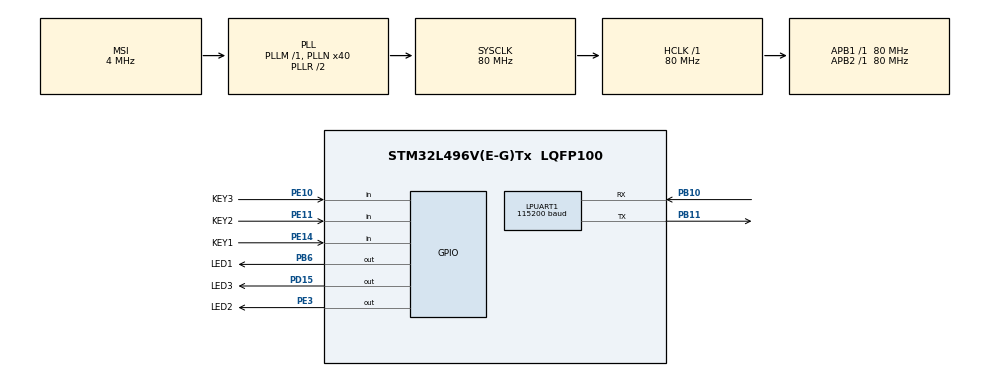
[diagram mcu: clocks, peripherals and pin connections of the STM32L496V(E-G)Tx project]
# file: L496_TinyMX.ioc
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LPUART1.BaudRate=115200
LPUART1.WordLength=UART_WORDLENGTH_8B
Mcu.Family=STM32L4
Mcu.Name=STM32L496V(E-G)Tx
Mcu.Package=LQFP100
NVIC.LPUART1_IRQn=true\:0\:0\:false\:false\:true\:true\:true\:true
NVIC.PriorityGroup=NVIC_PRIORITYGROUP_4
PA13\ (JTMS/SWDIO).Mode=Serial_Wire
PA13\ (JTMS/SWDIO).Signal=SYS_JTMS-SWDIO
PA14\ (JTCK/SWCLK).Mode=Serial_Wire
PA14\ (JTCK/SWCLK).Signal=SYS_JTCK-SWCLK
PB10.Mode=Asynchronous
PB10.Signal=LPUART1_RX
PB11.Mode=Asynchronous
PB11.Signal=LPUART1_TX
PB6.GPIO_FM6=I2C_FASTMODEPLUS_PB6
PB6.GPIO_Label=LED1
PB6.GPIO_Speed=GPIO_SPEED_FREQ_VERY_HIGH
PB6.Signal=GPIO_Output
PD15.GPIO_Label=LED3
PD15.GPIO_Speed=GPIO_SPEED_FREQ_VERY_HIGH
PD15.Signal=GPIO_Output
PE10.GPIO_Label=KEY3
PE10.GPIO_PuPd=GPIO_PULLUP
PE10.Signal=GPIO_Input
PE11.GPIO_Label=KEY2
PE11.GPIO_PuPd=GPIO_PULLUP
PE11.Signal=GPIO_Input
PE14.GPIO_Label=KEY1
PE14.GPIO_PuPd=GPIO_PULLUP
PE14.Signal=GPIO_Input
PE3.GPIO_Label=LED2
PE3.GPIO_Speed=GPIO_SPEED_FREQ_VERY_HIGH
PE3.Signal=GPIO_Output
PH0-OSC_IN\ (PH0).Mode=HSE-External-Oscillator
PH0-OSC_IN\ (PH0).Signal=RCC_OSC_IN
PH1-OSC_OUT\ (PH1).Mode=HSE-External-Oscillator
PH1-OSC_OUT\ (PH1).Signal=RCC_OSC_OUT
ProjectManager.HeapSize=0x200
ProjectManager.StackSize=0x400
ProjectManager.TargetToolchain=MDK-ARM V5.32
RCC.ADCFreq_Value=16000000
RCC.AHBFreq_Value=80000000
RCC.APB1Freq_Value=80000000
RCC.APB1TimFreq_Value=80000000
RCC.APB2Freq_Value=80000000
RCC.APB2TimFreq_Value=80000000
RCC.CortexFreq_Value=80000000
RCC.HCLKFreq_Value=80000000
RCC.HSE_VALUE=8000000
RCC.HSI48_VALUE=48000000
RCC.HSI_VALUE=16000000
RCC.LSE_VALUE=32768
RCC.MSI_VALUE=4000000
RCC.PLLN=40
RCC.SYSCLKFreq_VALUE=80000000
RCC.SYSCLKSource=RCC_SYSCLKSOURCE_PLLCLK
RCC.USBFreq_Value=16000000
RCC.VCOOutputFreq_Value=160000000
board=custom

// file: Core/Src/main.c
/* USER CODE BEGIN Header */
/**
  ******************************************************************************
  * @file           : main.c
  * @brief          : Main program body
  ******************************************************************************
  * @attention
  *
  * Copyright (c) 2022 STMicroelectronics.
  * All rights reserved.
  *
  * This software is licensed under terms that can be found in the LICENSE file
  * in the root directory of this software component.
  * If no LICENSE file comes with this software, it is provided AS-IS.
  *
  ******************************************************************************
  */
/* USER CODE END Header */
#include "main.h"
#include "usart.h"
#include "gpio.h"

/* USER CODE BEGIN Includes */
#include "stdio.h"

#include "tinymaix.h"

/* USER CODE END Includes */

void SystemClock_Config(void);

/* USER CODE BEGIN 0 */
int fputc(int ch, FILE *f)
{
  HAL_UART_Transmit(&hlpuart1, (uint8_t *)&ch, 1, 0xffff);
  return ch;
}

int fgetc(FILE *f)
{
  uint8_t ch = 0;
  HAL_UART_Receive(&hlpuart1, &ch, 1, 0xffff);
  return ch;
}

#define TEST_MDL 2

#if TEST_MDL==0
	#include "mnist_q_valid.h"
	#define IMG_L   (28)
	#define IMG_CH  (1)
	#define CLASS_N (10)

const uint8_t test_pic[28*28] ={
  0,  0,  0,  0,  0,  0,  0,  0,  0,  0,  0,  0,  0,  0,  0,  0,  0,  0,  0,  0,  0,  0,  0,  0,  0,  0,  0,  0,
  0,  0,  0,  0,  0,  0,  0,  0,  0,  0,  0,  0,  0,  0,  0,  0,  0,  0,  0,  0,  0,  0,  0,  0,  0,  0,  0,  0,
  0,  0,  0,  0,  0,  0,  0,  0,  0,  0,  0,  0,  0,  0,  0,  0,  0,  0,  0,  0,  0,  0,  0,  0,  0,  0,  0,  0,
  0,  0,  0,  0,  0,  0,  0,  0,  0,  0,116,125,171,255,255,150, 93,  0,  0,  0,  0,  0,  0,  0,  0,  0,  0,  0,
  0,  0,  0,  0,  0,  0,  0,  0,  0,169,253,253,253,253,253,253,218, 30,  0,  0,  0,  0,  0,  0,  0,  0,  0,  0,
  0,  0,  0,  0,  0,  0,  0,  0,169,253,253,253,213,142,176,253,253,122,  0,  0,  0,  0,  0,  0,  0,  0,  0,  0,
  0,  0,  0,  0,  0,  0,  0, 52,250,253,210, 32, 12,  0,  6,206,253,140,  0,  0,  0,  0,  0,  0,  0,  0,  0,  0,
  0,  0,  0,  0,  0,  0,  0, 77,251,210, 25,  0,  0,  0,122,248,253, 65,  0,  0,  0,  0,  0,  0,  0,  0,  0,  0,
  0,  0,  0,  0,  0,  0,  0,  0, 31, 18,  0,  0,  0,  0,209,253,253, 65,  0,  0,  0,  0,  0,  0,  0,  0,  0,  0,
  0,  0,  0,  0,  0,  0,  0,  0,  0,  0,  0,  0,  0,117,247,253,198, 10,  0,  0,  0,  0,  0,  0,  0,  0,  0,  0,
  0,  0,  0,  0,  0,  0,  0,  0,  0,  0,  0,  0, 76,247,253,231, 63,  0,  0,  0,  0,  0,  0,  0,  0,  0,  0,  0,
  0,  0,  0,  0,  0,  0,  0,  0,  0,  0,  0,  0,128,253,253,144,  0,  0,  0,  0,  0,  0,  0,  0,  0,  0,  0,  0,
  0,  0,  0,  0,  0,  0,  0,  0,  0,  0,  0,176,246,253,159, 12,  0,  0,  0,  0,  0,  0,  0,  0,  0,  0,  0,  0,
  0,  0,  0,  0,  0,  0,  0,  0,  0,  0, 25,234,253,233, 35,  0,  0,  0,  0,  0,  0,  0,  0,  0,  0,  0,  0,  0,
  0,  0,  0,  0,  0,  0,  0,  0,  0,  0,198,253,253,141,  0,  0,  0,  0,  0,  0,  0,  0,  0,  0,  0,  0,  0,  0,
  0,  0,  0,  0,  0,  0,  0,  0,  0, 78,248,253,189, 12,  0,  0,  0,  0,  0,  0,  0,  0,  0,  0,  0,  0,  0,  0,
  0,  0,  0,  0,  0,  0,  0,  0, 19,200,253,253,141,  0,  0,  0,  0,  0,  0,  0,  0,  0,  0,  0,  0,  0,  0,  0,
  0,  0,  0,  0,  0,  0,  0,  0,134,253,253,173, 12,  0,  0,  0,  0,  0,  0,  0,  0,  0,  0,  0,  0,  0,  0,  0,
  0,  0,  0,  0,  0,  0,  0,  0,248,253,253, 25,  0,  0,  0,  0,  0,  0,  0,  0,  0,  0,  0,  0,  0,  0,  0,  0,
  0,  0,  0,  0,  0,  0,  0,  0,248,253,253, 43, 20, 20, 20, 20,  5,  0,  5, 20, 20, 37,150,150,150,147, 10,  0,
  0,  0,  0,  0,  0,  0,  0,  0,248,253,253,253,253,253,253,253,168,143,166,253,253,253,253,253,253,253,123,  0,
  0,  0,  0,  0,  0,  0,  0,  0,174,253,253,253,253,253,253,253,253,253,253,253,249,247,247,169,117,117, 57,  0,
  0,  0,  0,  0,  0,  0,  0,  0,  0,118,123,123,123,166,253,253,253,155,123,123, 41,  0,  0,  0,  0,  0,  0,  0,
  0,  0,  0,  0,  0,  0,  0,  0,  0,  0,  0,  0,  0,  0,  0,  0,  0,  0,  0,  0,  0,  0,  0,  0,  0,  0,  0,  0,
  0,  0,  0,  0,  0,  0,  0,  0,  0,  0,  0,  0,  0,  0,  0,  0,  0,  0,  0,  0,  0,  0,  0,  0,  0,  0,  0,  0,
  0,  0,  0,  0,  0,  0,  0,  0,  0,  0,  0,  0,  0,  0,  0,  0,  0,  0,  0,  0,  0,  0,  0,  0,  0,  0,  0,  0,
  0,  0,  0,  0,  0,  0,  0,  0,  0,  0,  0,  0,  0,  0,  0,  0,  0,  0,  0,  0,  0,  0,  0,  0,  0,  0,  0,  0,
  0,  0,  0,  0,  0,  0,  0,  0,  0,  0,  0,  0,  0,  0,  0,  0,  0,  0,  0,  0,  0,  0,  0,  0,  0,  0,  0,  0,
};
#elif TEST_MDL==1
	#include "cifar10_q.h"
	#define IMG_L   (32)
	#define IMG_CH  (3)
	#define CLASS_N (10)

const unsigned char test_pic[32*32*3]={\
 62,116, 47,  60,111, 51,  64,113, 59,  68,119, 62,  74,127, 64,  79,132, 69,  82,133, 76,  89,134, 85,  94,136, 89,  97,136, 91, 104,143, 98, 100,142, 95, 100,145, 89, 102,146, 87, 106,145, 90, 113,146,101, 107,156, 88, 110,157, 95, 113,154,103, 118,157,112, 120,156,112, 120,157,111, 127,163,116, 126,162,115, 128,164,118, 130,166,120, 133,169,122, 136,174,122, 140,178,126, 142,178,131, 141,175,134, 140,172,137,
 67,118, 51,  66,114, 56,  71,117, 64,  74,123, 67,  79,130, 68,  82,135, 72,  85,135, 77,  92,138, 85,  98,142, 89, 103,144, 93, 101,143, 95, 100,143, 92, 105,153, 94, 104,151, 88, 110,154, 95, 113,152,100, 113,159, 93, 114,158, 99, 116,158,105, 125,162,116, 127,164,118, 127,165,117, 133,170,120, 133,170,120, 134,170,123, 137,173,127, 139,175,129, 142,179,129, 144,181,131, 148,182,135, 147,179,138, 146,176,141,
 72,116, 55,  73,115, 60,  76,119, 68,  81,126, 70,  84,133, 71,  88,137, 75,  90,138, 79,  96,141, 84, 102,145, 88, 104,146, 91, 108,149, 98, 116,159,108, 115,163,105, 107,156, 94, 104,152, 93, 109,155,102, 115,157, 96, 116,157, 99, 119,159,104, 128,165,115, 131,167,120, 131,168,118, 134,173,118, 134,173,118, 136,175,123, 138,176,128, 141,177,133, 144,179,135, 147,180,135, 148,181,136, 150,180,139, 149,177,141,
 76,118, 57,  76,116, 61,  80,121, 70,  82,127, 71,  86,133, 71,  92,139, 77,  96,139, 82, 103,144, 87, 132,172,114, 117,153, 99, 120,153,109, 146,180,140, 149,185,143, 146,185,139, 122,163,118, 110,152,111, 118,158,100, 120,160,102, 125,165,107, 133,169,115, 136,171,121, 137,173,121, 136,175,119, 135,176,118, 139,180,123, 142,180,132, 145,181,139, 147,181,141, 150,183,139, 152,182,139, 154,182,139, 155,181,141,
 78,122, 61,  78,121, 64,  81,125, 72,  83,128, 71,  87,133, 74,  93,139, 80, 101,141, 86, 109,145, 91, 153,187,133, 145,173,127, 124,145,113, 103,119,101, 101,120,103, 138,161,139, 151,179,156, 124,152,133, 121,160,104, 123,164,103, 129,170,109, 135,173,115, 137,172,122, 140,174,127, 139,177,125, 137,178,120, 139,182,125, 142,182,134, 145,182,142, 148,182,145, 151,183,142, 154,185,140, 157,184,140, 159,183,141,
 80,127, 65,  78,126, 68,  80,129, 73,  81,131, 73,  86,134, 75,  94,139, 82, 102,141, 89, 109,145, 91, 121,151, 98, 141,164,120, 107,120, 96,  34, 38, 33,  19, 23, 24,  63, 71, 70, 138,153,149, 145,164,161, 121,164,107, 122,164,103, 129,171,106, 132,173,112, 136,171,121, 141,174,130, 139,175,128, 139,179,124, 140,182,127, 143,183,135, 145,183,141, 148,183,143, 149,184,140, 153,184,139, 157,184,140, 159,184,140,
 77,128, 68,  76,127, 70,  78,130, 76,  79,133, 74,  84,136, 76,  90,140, 82,  99,141, 86, 106,145, 89,  90,125, 68, 110,136, 90,  82, 95, 71,  21, 22, 20,  12, 10, 16,  17, 21, 26,  80, 92, 92, 145,163,162, 127,173,121, 122,168,109, 126,172,106, 132,174,113, 136,172,125, 139,173,133, 139,173,132, 142,180,132, 142,184,131, 143,185,137, 145,185,143, 148,186,144, 152,188,142, 157,189,142, 159,188,142, 160,187,143,
 75,126, 68,  74,127, 70,  76,131, 76,  75,133, 74,  81,138, 77,  90,141, 83,  93,143, 85,  99,146, 84,  97,140, 77, 109,142, 91,  71, 88, 61,   6, 12,  7,   5,  5, 11,   2,  9, 12,  27, 44, 41, 121,144,140, 133,179,137, 121,169,117, 122,171,109, 128,175,113, 135,173,123, 136,171,131, 136,170,133, 141,177,133, 141,181,133, 144,183,137, 146,185,140, 148,187,142, 151,189,141, 153,190,140, 158,190,143, 158,189,144,
 76,126, 68,  76,129, 72,  77,132, 77,  76,134, 75,  78,137, 76,  84,140, 81,  89,143, 84,  93,146, 83,  92,144, 80, 106,148, 95,  81,106, 78,   0,  8,  5,   4,  6, 14,   1,  7, 12,   1, 19, 18,  90,114,112, 150,193,166, 122,167,128, 117,166,110, 127,175,116, 132,176,123, 131,170,125, 134,171,131, 138,177,132, 140,179,133, 142,181,135, 146,185,140, 148,187,141, 152,190,142, 153,191,141, 155,191,144, 155,190,146,
 79,127, 68,  78,129, 72,  76,131, 76,  76,134, 75,  80,137, 76,  85,139, 80,  88,141, 84,  89,145, 86,  96,150, 90, 106,150,103,  68, 91, 69,   5, 10, 11,   3,  0, 10,   0,  0,  8,  25, 33, 40, 122,136,142, 162,196,186, 140,179,154, 125,171,125, 122,170,112, 123,169,110, 129,173,120, 134,174,126, 137,176,130, 139,178,132, 141,180,134, 145,184,139, 148,187,141, 150,190,142, 151,191,143, 152,191,145, 153,192,147,
 81,127, 68,  78,127, 71,  77,129, 75,  80,133, 76,  82,136, 76,  85,136, 78,  89,139, 85,  91,144, 87,  94,147, 90, 100,141, 96,  49, 68, 47,   9,  4,  3,  17,  0,  7,  26,  8, 15,  65, 53, 59, 157,150,157, 165,186,188, 147,175,162, 137,172,138, 126,170,117, 127,174,112, 123,172,110, 126,171,114, 127,171,118, 137,177,129, 140,179,133, 146,183,137, 149,185,141, 149,188,143, 150,189,144, 150,191,146, 151,192,147,
 81,126, 69,  77,126, 72,  78,127, 75,  82,133, 76,  84,135, 75,  87,135, 77,  89,138, 82,  92,143, 86,  98,148, 90, 107,143, 96,  53, 65, 35,  20,  4,  0,  62, 28, 22, 101, 62, 54, 114, 78, 70, 156,124,118, 145,152,155, 132,146,140, 131,155,131, 130,165,121, 120,167,105, 119,170,102, 125,175,111, 132,179,123, 134,177,126, 139,179,131, 145,182,136, 148,184,140, 149,185,143, 149,187,145, 149,190,145, 148,192,145,
 77,124, 68,  75,122, 73,  77,125, 77,  81,131, 77,  84,135, 75,  88,134, 75,  90,138, 79,  92,143, 83,  93,144, 82, 104,142, 84,  70, 79, 36,  67, 45, 10, 130, 87, 54, 158,105, 72, 157,103, 72, 176,126, 98, 116,110,103, 109,107, 99, 116,126,109, 136,161,127, 123,163,108, 121,172,105, 118,170,106, 126,176,118, 131,177,125, 138,179,128, 144,182,132, 147,183,137, 148,183,143, 148,185,145, 148,188,146, 148,193,144,
 72,121, 67,  73,121, 73,  74,123, 77,  78,130, 77,  83,134, 74,  86,135, 73,  87,138, 76,  88,143, 80,  94,148, 81, 104,145, 83,  86, 99, 43, 102, 81, 30, 156,109, 57, 162,102, 48, 169,109, 57, 190,130, 84, 126,109, 83,  88, 74, 56,  88, 85, 70, 110,123, 99, 124,157,113, 114,162,103, 118,170,110, 125,175,121, 127,175,123, 136,178,125, 143,181,129, 146,182,135, 148,182,142, 149,183,146, 149,188,143, 149,192,141,
 70,119, 65,  69,119, 71,  71,122, 78,  74,127, 77,  81,132, 74,  84,135, 73,  84,138, 78,  82,141, 80,  83,143, 79,  99,146, 83,  93,111, 52,  93, 76, 19, 132, 88, 27, 159,100, 38, 178,115, 57, 182,119, 68, 135,111, 65,  84, 63, 32,  71, 58, 44,  82, 85, 69, 124,148,116, 117,159,111, 121,171,117, 120,171,121, 127,174,125, 133,177,124, 141,180,124, 146,182,130, 148,180,139, 149,182,145, 147,186,141, 147,191,138,
 67,117, 63,  69,119, 71,  71,122, 78,  74,127, 77,  78,132, 73,  84,137, 74,  82,139, 78,  79,141, 81,  80,145, 83,  95,146, 86, 105,126, 71,  91, 78, 22, 108, 67,  5, 145, 88, 26, 171,108, 50, 179,116, 66, 147,119, 59, 110, 83, 46,  72, 53, 38,  66, 64, 53, 100,121, 96, 119,159,117, 117,167,119, 119,168,122, 126,174,126, 133,178,122, 140,180,122, 145,181,127, 147,179,138, 147,180,143, 148,184,140, 147,189,134,
 67,115, 67,  68,114, 71,  75,121, 79,  77,124, 78,  76,125, 73,  85,136, 78,  81,137, 72,  82,140, 75,  83,143, 79,  86,141, 86,  94,136, 88,  77, 99, 51,  74, 70, 19, 119, 84, 28, 155, 93, 39, 171, 92, 41, 193,103, 49, 178,113, 52, 123, 89, 29,  77, 68, 25,  81, 87, 62, 117,142,116, 116,161,118, 116,172,113, 121,175,115, 133,177,124, 138,175,125, 141,177,130, 144,183,138, 139,182,137, 141,184,133, 145,188,131,
 66,115, 65,  68,116, 68,  71,118, 72,  79,125, 78,  80,128, 76,  82,132, 74,  78,133, 70,  83,141, 76,  80,140, 79,  84,142, 84,  90,139, 87,  89,121, 67,  88, 97, 41, 103, 84, 27, 117, 71, 17, 136, 75, 25, 171, 99, 45, 189,131, 72, 182,143, 88, 129,107, 66,  87, 78, 51,  95,106, 80, 125,159,118, 116,166,112, 121,174,117, 127,173,120, 135,173,123, 138,174,127, 140,176,132, 139,180,135, 140,182,134, 140,185,128,
 64,114, 60,  68,117, 65,  72,121, 71,  76,123, 74,  74,123, 69,  81,131, 73,  85,138, 75,  78,135, 72,  79,139, 78,  80,141, 83,  83,141, 83,  91,137, 78,  95,124, 61, 100,105, 44,  90, 73, 17,  94, 62, 13, 142,100, 47, 161,120, 65, 182,142, 90, 190,151,112, 114, 86, 56,  86, 78, 49, 124,138,102, 127,163,117, 125,170,121, 123,172,118, 132,177,121, 138,177,125, 137,174,128, 140,179,134, 139,181,133, 134,181,125,
 58,113, 56,  61,116, 61,  69,121, 67,  78,129, 72,  75,125, 67,  77,128, 66,  79,132, 69,  81,138, 77,  80,140, 80,  75,139, 79,  75,140, 78,  86,144, 79,  91,138, 70, 102,131, 68,  94,104, 51,  83, 83, 35, 101, 90, 38, 136,113, 63, 181,142, 97, 198,154,113, 156,118, 83, 112, 91, 59,  95, 94, 60, 103,119, 85, 127,160,116, 127,171,118, 126,176,118, 131,178,122, 136,176,128, 139,175,131, 140,179,133, 131,177,125,
 55,113, 58,  61,119, 64,  65,123, 65,  70,124, 64,  76,130, 65,  87,140, 73,  84,137, 70,  81,136, 73,  79,137, 78,  73,137, 77,  71,139, 74,  82,148, 77,  86,143, 74,  95,140, 77, 100,132, 77, 100,124, 76, 101,113, 65, 117,112, 67, 163,139, 97, 176,145,100, 161,135, 89, 178,162,120, 103, 93, 63,  64, 63, 35, 131,145,109, 138,171,120, 124,172,113, 123,174,116, 128,176,124, 129,171,124, 136,175,129, 135,176,125,
 59,115, 66,  60,117, 66,  64,122, 64,  71,126, 63,  84,139, 70, 119,175,100, 121,176,103,  90,144, 77,  74,130, 71,  78,138, 78,  72,138, 73,  74,141, 72,  82,145, 76,  85,139, 79,  94,140, 87,  99,140, 89,  96,121, 77, 111,122, 82, 151,149,108, 142,137, 88, 141,142, 86, 158,161,112, 122,120, 86,  84, 77, 50, 134,133, 99, 145,166,117, 129,170,112, 118,172,113, 120,175,120, 120,167,118, 134,172,124, 138,174,127,
 67,114, 75,  73,120, 74,  76,125, 73,  96,147, 87, 107,160, 87, 123,179, 98, 126,182,101,  94,149, 76,  73,128, 65,  77,135, 76,  73,136, 74,  72,136, 70,  80,143, 81,  82,140, 82,  86,141, 86,  75,127, 73,  58, 92, 51,  89,116, 77, 121,144,100, 133,160,104, 111,145, 80, 110,142, 85, 107,120, 82,  73, 71, 41, 114,108, 71, 133,145, 93, 132,165,108, 119,168,112, 116,171,116, 119,169,115, 128,169,118, 138,172,125,
 98,129, 98, 138,171,134, 135,170,126, 144,184,129, 144,189,120, 119,171, 88, 104,159, 72,  83,140, 61,  77,133, 68,  72,130, 71,  75,135, 74,  76,139, 77,  81,142, 84,  77,136, 85,  83,140, 89,  58,115, 60,  78,120, 79,  89,129, 88,  83,127, 80,  96,149, 86, 101,163, 93, 105,159, 99, 105,142, 96, 109,125, 84,  76, 79, 33, 107,115, 62, 131,154,100, 124,163,111, 116,167,110, 121,172,114, 124,169,113, 135,170,120,
165,182,155, 220,238,209, 209,231,196, 196,223,179, 167,204,142, 123,170, 91, 105,161, 72,  83,141, 60,  73,133, 63,  75,135, 71,  74,135, 71,  75,138, 76,  81,140, 89,  79,135, 92,  73,128, 81,  71,129, 75,  90,138, 96,  77,128, 84,  77,133, 80,  86,152, 87,  87,159, 89,  86,155, 94,  96,154,100, 116,155,103, 105,129, 71,  70, 84, 26,  98,114, 61, 127,156,107, 118,163,106, 117,168,106, 124,170,111, 135,171,117,
194,203,177, 229,241,213, 228,242,214, 232,249,216, 201,230,181, 115,159, 88, 100,155, 70,  88,147, 66,  74,134, 64,  76,137, 71,  74,137, 68,  79,138, 77,  78,132, 85,  74,125, 88,  83,134, 96,  81,135, 88,  77,130, 86,  79,134, 87,  83,144, 88,  85,151, 86,  81,152, 86,  81,151, 90,  84,152, 93,  95,155, 91, 117,161, 92, 105,130, 68,  79, 94, 43, 118,142, 94, 128,169,112, 123,174,107, 121,166,103, 135,172,116,
177,189,159, 210,222,194, 225,238,214, 230,244,220, 207,232,194, 144,182,122, 121,173, 96,  95,152, 77,  73,132, 64,  78,136, 71,  76,136, 66,  81,136, 73,  85,131, 88,  88,127,101, 109,149,121,  89,133, 94,  71,126, 79,  83,140, 89,  89,151, 91,  89,150, 86,  87,147, 86,  83,149, 90,  83,153, 92,  89,159, 88, 104,161, 86, 125,163, 97, 124,148, 94, 120,146, 98, 122,161,105, 119,165, 99, 125,167,102, 135,167,108,
158,178,143, 148,166,135, 193,209,185, 230,244,226, 210,232,204, 189,223,176, 148,194,128,  96,148, 84,  86,137, 79,  86,138, 78,  87,138, 70,  94,139, 76,  75,110, 70,  71, 97, 79, 111,137,119, 111,141,112,  75,132, 81,  84,142, 87,  89,148, 87,  91,148, 87,  92,148, 89,  91,149, 91,  89,155, 90,  92,163, 90,  99,163, 87, 118,168, 98, 146,184,126, 125,161,107, 114,157,100, 140,185,122, 145,182,118, 135,163,103,
161,191,150, 101,127, 91, 156,175,150, 226,239,223, 210,227,206, 222,249,210, 184,220,168, 123,161,111, 139,178,133, 134,175,124, 116,157, 95, 121,157, 97,  77,101, 66,  74, 91, 78,  98,114,103,  97,116, 95,  82,138, 85,  86,144, 85,  90,147, 84,  93,147, 87,  95,148, 91,  93,148, 91,  91,152, 88,  96,160, 88,  99,162, 88, 107,163, 92, 131,181,117, 122,168,109, 121,166,109, 156,197,139, 170,204,143, 159,188,125,
182,215,171, 153,180,141, 188,207,180, 225,235,218, 204,215,195, 216,233,200, 206,230,188, 175,201,165, 200,225,197, 199,225,189, 155,186,131, 154,183,128, 101,120, 87, 105,116,106, 102,113,105,  80, 96, 78,  80,141, 85,  86,146, 85,  92,149, 86,  92,149, 88,  94,149, 92,  93,151, 92,  93,154, 88,  94,155, 87,  98,158, 88, 100,158, 87, 116,172,101, 116,167,100, 138,181,124, 177,216,161, 174,209,152, 148,184,118,
193,223,182, 203,229,189, 214,229,198, 232,236,217, 233,234,214, 233,239,208, 220,232,196, 214,227,203, 222,235,221, 207,223,199, 148,169,124, 144,166,117, 113,128,100, 111,122,114, 128,140,134, 118,137,118,  79,145, 86,  85,148, 86,  91,151, 87,  95,151, 92,  93,152, 94,  93,156, 94,  95,157, 91,  96,154, 89,  97,155, 90, 107,167, 97, 113,172, 97, 122,172,102, 143,182,126, 183,218,168, 140,179,123, 116,163, 95,
176,203,163, 210,231,192, 219,230,198, 233,232,212, 234,229,208, 230,230,200, 211,216,185, 218,222,203, 223,227,221, 222,232,215, 167,185,144, 125,145, 98,  81, 96, 68,  59, 69, 63, 120,134,128, 140,160,141,  84,154, 93,  83,148, 86,  89,149, 85,  95,153, 94,  94,156, 96,  91,156, 94,  93,157, 91,  93,153, 89, 114,171,110, 118,178,108, 111,169, 91, 115,163, 91, 158,193,137, 160,192,145, 109,151, 96, 100,155, 86,
};

  #elif TEST_MDL==2
	#include "vww96_q.h"
	#define IMG_L   (96)
	#define IMG_CH  (3)
	#define CLASS_N (2)
const unsigned char test_pic[96*96*3]={\
155,156,176, 104,105,125, 122,123,143, 155,158,177,  94, 99,118,  75, 80, 99,  73, 79, 95,  77, 83, 99, 133,139,155, 161,164,179, 167,170,185, 165,164,180, 164,161,178, 148,146,160, 145,141,156, 168,161,177, 159,166,174, 160,167,175, 158,165,173,  97,104,112,  71, 78, 86,  79, 86, 94,  74, 81, 89, 126,133,141, 142,149,157, 114,121,129, 142,149,157, 147,154,162,  80, 87, 95,  70, 77, 85,  59, 66, 74,  68, 75, 83,  43, 53, 52,  37, 47, 46,  42, 52, 51,  68, 80, 78, 112,124,122, 145,157,155, 149,161,159, 137,149,147, 137,147,146, 149,159,158, 154,163,162, 144,150,150, 132,136,137, 127,131,132, 122,123,125, 114,115,117,  92, 91, 96,  87, 86, 91,  81, 81, 83,  75, 75, 77,  70, 70, 72,  64, 64, 66,  59, 59, 61,  55, 55, 57,  67, 67, 67,  93, 95, 94, 113,115,114, 118,120,119, 129,131,130, 146,148,145, 142,144,141, 124,126,123,  90, 88, 93,  84, 83, 88,  87, 88, 92, 106,110,113, 119,124,127, 116,126,127, 141,153,151, 185,200,197, 230,245,242, 235,250,247, 241,253,251, 241,252,248, 238,247,244, 240,246,244, 246,252,250, 252,255,255, 252,254,253, 249,251,250, 246,248,247, 247,249,248, 249,251,250, 251,253,252, 249,251,250, 247,249,248, 254,255,255, 254,255,255, 254,255,255, 253,255,254, 253,255,254, 252,254,253, 252,254,253, 252,254,253,
139,138,156,  90, 91,109, 101,103,118, 133,136,151,  81, 84, 99,  60, 66, 80,  57, 63, 77,  60, 66, 78, 100,106,118, 129,133,145, 136,138,150, 132,132,144, 130,128,141, 114,110,124, 108,102,116, 127,121,135, 119,123,132, 119,123,132, 118,122,131,  61, 65, 74,  33, 37, 46,  34, 38, 47,  23, 27, 36,  65, 69, 78,  81, 85, 94,  51, 55, 64,  78, 82, 91,  99,103,112,  55, 59, 68,  64, 68, 77,  74, 78, 87,  97,101,110, 165,174,173, 153,162,161, 128,137,136, 101,110,109,  86, 95, 94,  84, 93, 92,  86, 95, 94,  86, 95, 94, 102,111,110, 103,109,109,  98,104,104,  89, 93, 94,  85, 86, 88,  84, 85, 87,  84, 84, 86,  81, 81, 83,  67, 66, 71,  64, 63, 68,  60, 60, 62,  56, 56, 58,  53, 53, 55,  48, 48, 50,  43, 43, 45,  38, 39, 41,  29, 31, 30,  44, 46, 45,  55, 57, 56,  57, 59, 58,  68, 70, 69,  86, 88, 87,  91, 93, 92,  84, 86, 85,  76, 74, 79,  80, 79, 84,  90, 91, 95, 108,112,115, 114,122,124, 112,122,123, 142,154,154, 191,206,203, 217,232,229, 230,245,242, 247,255,255, 247,255,255, 248,255,255, 247,255,253, 246,252,250, 248,252,251, 254,255,255, 253,255,254, 250,252,251, 250,252,251, 253,255,254, 254,255,255, 253,255,254, 252,254,253, 252,254,253, 252,254,253, 251,253,252, 251,253,252, 250,252,251, 250,252,251, 250,252,251, 249,251,250,
167,167,179, 128,128,140, 128,128,140, 160,163,172, 120,124,133, 103,107,116,  99,103,112, 101,106,112, 121,126,132, 151,154,161, 159,162,167, 156,157,162, 155,154,160, 140,137,144, 133,128,135, 149,144,151, 130,135,141, 129,134,140, 131,136,142,  86, 91, 97,  59, 64, 70,  55, 60, 66,  42, 47, 53,  71, 76, 82,  97,102,108,  60, 65, 71,  69, 74, 80,  90, 95,101,  49, 54, 60,  50, 55, 61,  57, 62, 68,  80, 85, 91, 122,123,125, 139,140,142, 151,152,154, 146,147,149, 130,131,133, 113,117,118, 104,108,109, 100,101,103,  76, 77, 79,  67, 68, 70,  60, 61, 63,  59, 59, 61,  59, 59, 61,  58, 56, 59,  58, 56, 59,  60, 58, 61,  50, 49, 54,  48, 47, 52,  46, 45, 50,  44, 44, 46,  43, 43, 45,  40, 40, 42,  35, 36, 38,  32, 33, 35,  36, 37, 39,  38, 39, 41,  38, 40, 39,  36, 38, 37,  39, 41, 40,  46, 48, 47,  49, 53, 52,  48, 52, 51,  48, 47, 52,  57, 56, 61,  68, 69, 73,  80, 84, 87,  85, 93, 95,  94,104,105, 139,151,151, 199,213,213, 218,232,232, 228,243,240, 238,253,250, 242,254,252, 239,249,248, 239,248,247, 246,252,252, 251,255,255, 252,255,255, 252,255,255, 250,254,253, 250,254,253, 251,255,254, 252,255,255, 252,255,255, 252,255,255, 251,255,254, 251,255,254, 250,254,253, 250,254,253, 250,254,253, 249,253,252, 249,253,252, 249,253,252,
146,145,150, 118,117,122, 105,106,110, 140,141,145, 115,119,122,  99,103,106,  93, 99, 99,  95,101,101, 104,108,109, 136,140,139, 149,151,150, 149,149,149, 152,150,151, 142,138,137, 134,128,128, 147,141,141, 146,149,154, 144,147,152, 149,152,157, 120,123,128,  97,100,105,  92, 95,100,  84, 87, 92, 103,106,111, 144,147,152, 111,114,119, 112,115,120, 141,144,149, 107,110,115,  97,100,105,  96, 99,104, 114,117,122, 156,151,155, 156,151,155, 149,144,148, 132,127,131, 113,108,112,  94, 89, 93,  76, 71, 75,  61, 59, 62,  61, 59, 62,  57, 52, 56,  58, 53, 57,  65, 60, 64,  65, 60, 64,  56, 51, 55,  53, 48, 52,  57, 52, 56,  49, 48, 53,  46, 45, 50,  43, 43, 45,  41, 41, 43,  41, 41, 43,  40, 41, 43,  39, 40, 42,  38, 39, 41,  40, 41, 43,  37, 38, 40,  34, 38, 39,  34, 38, 39,  31, 35, 36,  25, 29, 30,  22, 26, 27,  23, 27, 28,  36, 35, 41,  40, 41, 46,  38, 42, 45,  40, 45, 48,  44, 52, 54,  60, 70, 71, 111,123,123, 170,184,184, 192,206,206, 210,224,224, 233,247,247, 247,255,255, 247,255,255, 242,250,252, 239,247,249, 239,247,249, 250,254,253, 249,253,252, 248,252,251, 247,251,250, 248,252,251, 249,253,252, 250,254,253, 251,255,254, 249,253,252, 249,253,252, 249,253,252, 249,253,252, 249,253,252, 249,253,252, 249,253,252, 249,253,252,
128,126,127, 115,114,112,  89, 89, 87, 122,122,120, 110,112,109,  90, 95, 91,  83, 88, 82,  84, 89, 83,  91, 96, 90, 127,129,124, 142,143,137, 143,142,137, 151,148,143, 143,138,134, 136,129,123, 147,140,134, 140,141,145, 135,136,140, 139,140,144, 121,122,126,  98, 99,103,  91, 92, 96,  90, 91, 95, 101,102,106, 126,127,131, 103,104,108,  99,100,104, 134,135,139, 111,112,116,  99,100,104,  98, 99,103, 111,112,116, 145,134,140, 135,124,130, 115,104,110,  95, 84, 90,  82, 73, 78,  77, 68, 73,  72, 63, 68,  65, 56, 61,  55, 46, 51,  55, 46, 51,  61, 52, 57,  67, 61, 65,  62, 56, 60,  50, 44, 48,  47, 41, 45,  54, 48, 52,  48, 48, 50,  43, 43, 45,  37, 37, 39,  34, 34, 36,  34, 34, 36,  36, 37, 39,  38, 39, 41,  39, 40, 42,  30, 31, 33,  26, 30, 31,  28, 32, 33,  34, 38, 39,  34, 38, 39,  27, 31, 32,  24, 30, 30,  26, 32, 32,  40, 41, 46,  45, 46, 51,  40, 43, 48,  38, 43, 47,  38, 46, 49,  42, 52, 53,  67, 79, 79, 105,117,117, 143,157,157, 162,176,176, 191,203,203, 212,224,224, 225,235,236, 230,240,241, 235,243,245, 238,246,248, 245,249,248, 246,250,249, 247,251,250, 247,251,250, 247,251,250, 247,251,250, 248,252,251, 249,253,252, 246,250,249, 246,250,249, 246,250,249, 247,251,250, 247,251,250, 247,251,250, 247,251,250, 247,251,250,
116,112,109, 116,115,111,  79, 78, 74, 109,110,105, 106,107,101,  83, 86, 79,  73, 76, 69,  74, 77, 70,  81, 84, 75, 117,118,110, 131,131,123, 131,128,119, 139,135,126, 134,127,119, 124,117,109, 133,124,117, 139,139,139, 133,133,133, 134,134,134, 121,121,121,  93, 93, 93,  80, 80, 80,  84, 84, 84,  87, 87, 87, 131,131,131, 117,117,117,  99, 99, 99, 126,126,126, 105,105,105,  92, 92, 92,  91, 91, 91,  97, 97, 97, 106, 93,100, 109, 96,103, 106, 93,100,  92, 79, 86,  77, 64, 71,  67, 54, 61,  59, 46, 53,  54, 41, 48,  62, 51, 57,  63, 52, 58,  65, 54, 60,  62, 53, 58,  54, 45, 50,  44, 38, 42,  46, 40, 44,  53, 47, 51,  45, 43, 46,  40, 38, 41,  32, 32, 34,  29, 29, 31,  30, 30, 32,  33, 33, 35,  35, 36, 38,  37, 38, 40,  37, 38, 40,  32, 36, 37,  32, 36, 37,  34, 38, 39,  35, 41, 41,  34, 40, 40,  36, 42, 42,  40, 46, 46,  36, 37, 41,  46, 50, 53,  54, 58, 61,  60, 65, 68,  62, 70, 72,  51, 61, 63,  45, 55, 57,  54, 65, 67,  91,102,104, 113,124,126, 150,161,163, 186,197,199, 215,225,227, 232,242,244, 239,249,251, 241,251,253, 241,247,245, 244,250,248, 247,253,251, 249,255,253, 248,254,252, 247,253,251, 247,253,251, 247,253,251, 249,255,253, 249,255,253, 249,255,253, 249,255,253, 250,255,254, 250,255,254, 250,255,254, 250,255,254,
118,114,111, 133,129,126,  92, 88, 85, 119,118,114, 123,124,119,  98, 99, 93,  88, 89, 83,  91, 92, 86,  91, 92, 84, 126,127,119, 139,139,131, 138,135,128, 147,143,134, 144,137,129, 134,125,118, 140,131,124, 137,136,134, 131,130,128, 133,132,130, 127,126,124,  93, 92, 90,  75, 74, 72,  84, 83, 81,  82, 81, 79, 109,108,106, 109,108,106,  88, 87, 85, 112,111,109,  96, 95, 93,  86, 85, 83,  87, 86, 84,  88, 87, 85,  98, 86, 90,  96, 84, 88,  85, 73, 77,  70, 58, 62,  61, 49, 53,  63, 51, 55,  69, 57, 61,  72, 60, 64,  72, 60, 64,  73, 62, 66,  70, 59, 63,  59, 50, 53,  49, 43, 45,  47, 41, 43,  45, 41, 42,  44, 40, 41,  36, 34, 35,  33, 31, 32,  30, 28, 29,  29, 27, 28,  31, 29, 30,  33, 33, 35,  34, 34, 36,  33, 34, 36,  33, 34, 36,  31, 35, 36,  30, 34, 35,  27, 31, 32,  25, 30, 33,  27, 32, 35,  28, 33, 36,  27, 32, 35,  27, 31, 34,  40, 44, 47,  49, 53, 56,  57, 62, 65,  65, 70, 73,  54, 62, 64,  40, 50, 51,  41, 51, 53,  50, 60, 62,  77, 88, 90, 124,135,137, 176,186,188, 213,223,225, 230,240,242, 228,238,240, 222,232,234, 235,244,241, 240,249,246, 246,255,252, 249,255,255, 247,255,253, 245,254,251, 243,252,249, 243,252,249, 247,255,253, 248,255,254, 248,255,254, 248,255,254, 249,255,255, 249,255,255, 249,255,255, 249,255,255,
103, 97, 99, 126,122,121,  83, 79, 78, 112,111,109, 122,121,119,  96, 96, 94,  88, 89, 84,  92, 93, 88,  86, 87, 82, 122,121,117, 136,133,128, 134,129,125, 144,136,133, 142,132,130, 132,123,118, 139,128,124, 141,137,134, 137,133,130, 142,138,135, 141,137,134, 107,103,100,  88, 84, 81, 101, 97, 94,  97, 93, 90, 117,113,110, 128,124,121, 107,103,100, 129,125,122, 112,108,105, 100, 96, 93,  96, 92, 89,  88, 84, 81,  86, 77, 78,  77, 68, 69,  66, 56, 57,  59, 49, 50,  67, 55, 57,  77, 65, 67,  78, 66, 68,  74, 62, 64,  70, 58, 60,  72, 62, 63,  66, 57, 58,  52, 46, 46,  46, 42, 41,  43, 42, 40,  35, 34, 32,  22, 22, 20,  28, 22, 22,  26, 22, 21,  27, 23, 22,  29, 25, 24,  32, 28, 27,  32, 30, 31,  31, 29, 30,  29, 29, 29,  24, 26, 25,  31, 32, 34,  32, 36, 37,  30, 34, 35,  29, 35, 35,  32, 38, 38,  29, 34, 37,  22, 27, 30,  34, 38, 39,  39, 43, 44,  36, 40, 41,  34, 38, 39,  40, 45, 48,  39, 44, 47,  36, 41, 44,  40, 48, 50,  54, 62, 65,  52, 60, 63,  56, 66, 68,  80, 90, 92, 119,129,131, 163,172,177, 197,206,211, 216,225,230, 232,241,238, 238,247,244, 245,254,251, 248,255,254, 247,255,253, 243,252,249, 241,250,247, 241,250,247, 240,249,246, 240,249,246, 241,250,247, 241,250,247, 242,251,248, 242,251,248, 243,252,249, 243,252,249,
 71, 64, 71, 104, 99,105,  81, 76, 82,  75, 73, 76, 114,112,115,  72, 72, 74,  74, 74, 76,  68, 68, 68,  71, 71, 71,  96, 94, 95, 128,124,123, 136,130,130, 130,121,122, 133,123,124, 135,125,126, 125,113,115, 134,130,127, 138,134,131, 134,130,127, 133,129,126, 107,103,100,  86, 82, 79,  96, 92, 89,  91, 87, 84, 113,109,106, 131,127,124,  96, 92, 89, 122,118,115, 109,105,102,  82, 78, 75,  79, 75, 72,  71, 67, 64,  68, 64, 61,  62, 58, 55,  56, 51, 48,  56, 48, 46,  57, 49, 47,  62, 52, 51,  63, 53, 52,  64, 52, 52,  65, 55, 54,  73, 63, 62,  75, 67, 65,  63, 58, 55,  49, 45, 42,  38, 37, 33,  33, 34, 29,  28, 30, 25,  37, 29, 27,  36, 28, 26,  36, 28, 26,  34, 29, 26,  34, 29, 26,  31, 27, 26,  29, 25, 24,  25, 24, 22,  35, 35, 35,  22, 22, 22,  18, 20, 19,  27, 31, 32,  31, 35, 36,  24, 28, 29,  17, 23, 23,  19, 25, 25,  30, 32, 31,  29, 31, 30,  25, 29, 28,  24, 28, 27,  26, 30, 31,  30, 34, 35,  35, 39, 40,  38, 42, 45,  50, 55, 58,  56, 61, 64,  58, 63, 67,  65, 73, 76,  90, 98,101, 124,132,135, 167,176,181, 209,218,223, 226,237,233, 237,248,244, 244,255,251, 241,252,248, 236,247,243, 236,247,243, 240,251,247, 243,254,250, 248,255,255, 246,255,253, 242,253,249, 239,250,246, 239,250,246, 239,250,246, 239,250,246, 238,249,245,
 33, 27, 37,  68, 62, 72,  53, 47, 57,  35, 32, 39,  72, 71, 77,  42, 41, 47,  29, 28, 34,  28, 27, 32,  32, 31, 36,  55, 54, 59,  87, 85, 88,  99, 94, 98,  94, 88, 92,  98, 89, 94, 100, 89, 95,  88, 77, 83, 106,103, 98, 108,105,100, 104,101, 96, 101, 98, 93,  74, 71, 66,  52, 49, 44,  61, 58, 53,  56, 53, 48,  85, 82, 77, 108,105,100,  75, 72, 67,  93, 90, 85,  77, 74, 69,  57, 54, 49,  59, 56, 51,  55, 52, 47,  43, 44, 38,  40, 39, 34,  36, 35, 30,  40, 35, 31,  48, 40, 37,  55, 45, 43,  61, 50, 48,  64, 53, 51,  73, 62, 60,  76, 66, 64,  74, 66, 63,  62, 57, 53,  50, 47, 42,  43, 42, 37,  40, 41, 35,  37, 38, 32,  42, 31, 27,  41, 30, 26,  38, 29, 24,  37, 28, 23,  36, 28, 25,  36, 28, 25,  33, 28, 24,  31, 27, 24,  30, 29, 25,  24, 23, 21,  23, 23, 21,  28, 30, 29,  29, 31, 30,  22, 26, 25,  20, 24, 23,  22, 26, 25,  28, 30, 25,  26, 28, 25,  24, 26, 23,  24, 24, 22,  25, 25, 23,  28, 28, 28,  32, 32, 32,  35, 35, 37,  45, 46, 48,  51, 52, 56,  47, 51, 54,  51, 55, 58,  68, 73, 77,  93, 98,102, 126,134,137, 164,172,175, 207,218,214, 223,234,230, 236,247,243, 238,249,245, 237,248,244, 241,252,248, 242,253,249, 239,250,246, 245,255,252, 246,255,253, 248,255,255, 248,255,255, 248,255,255, 248,255,255, 245,255,252, 240,251,247,
 30, 24, 36,  63, 60, 71,  60, 57, 68,  27, 25, 36,  62, 61, 69,  50, 50, 58,  14, 14, 22,  22, 22, 30,  19, 20, 25,  41, 40, 46,  72, 69, 76,  87, 82, 88,  84, 77, 84,  86, 76, 84,  83, 73, 81,  70, 59, 67,  86, 83, 78,  88, 85, 80,  82, 79, 74,  78, 75, 70,  49, 46, 41,  25, 22, 17,  33, 30, 25,  27, 24, 19,  47, 44, 39,  72, 69, 64,  43, 40, 35,  52, 49, 44,  37, 34, 29,  32, 29, 24,  39, 36, 31,  40, 37, 32,  25, 28, 17,  26, 28, 17,  29, 29, 19,  37, 34, 25,  50, 43, 35,  62, 51, 45,  71, 58, 52,  74, 61, 55,  78, 63, 58,  76, 63, 57,  70, 57, 51,  58, 49, 42,  52, 45, 37,  50, 46, 37,  48, 45, 36,  43, 43, 33,  51, 36, 29,  50, 35, 28,  47, 34, 26,  45, 32, 24,  41, 30, 24,  38, 29, 22,  38, 29, 24,  37, 30, 24,  31, 26, 22,  30, 26, 23,  29, 28, 24,  28, 28, 26,  26, 26, 24,  24, 26, 23,  24, 26, 23,  25, 27, 26,  25, 26, 20,  24, 25, 19,  22, 23, 17,  22, 21, 16,  23, 22, 18,  27, 23, 20,  31, 27, 26,  33, 29, 28,  42, 40, 41,  47, 45, 48,  42, 42, 44,  40, 41, 45,  49, 53, 56,  63, 67, 70,  86, 91, 94, 117,122,126, 166,178,174, 199,211,207, 232,244,240, 245,255,253, 247,255,255, 247,255,255, 242,254,250, 232,244,240, 228,240,236, 230,242,238, 235,247,243, 239,251,247, 242,254,250, 240,252,248, 234,246,242, 230,242,238,
 53, 50, 61,  86, 83, 94,  95, 93,104,  54, 52, 63,  81, 81, 89,  88, 91, 98,  36, 39, 46,  49, 52, 59,  35, 38, 43,  53, 54, 59,  83, 82, 88, 100, 98,103,  99, 94,100,  99, 92, 99,  95, 85, 93,  79, 69, 77,  86, 85, 81,  88, 87, 83,  82, 81, 77,  77, 76, 72,  47, 46, 42,  22, 21, 17,  29, 28, 24,  22, 21, 17,  42, 41, 37,  62, 61, 57,  30, 29, 25,  28, 27, 23,  15, 14, 10,  20, 19, 15,  24, 23, 19,  24, 23, 19,  20, 22,  8,  25, 27, 13,  38, 36, 23,  52, 46, 34,  65, 55, 45,  77, 63, 54,  84, 67, 59,  87, 68, 61,  80, 60, 53,  78, 58, 51,  71, 52, 45,  64, 47, 39,  63, 49, 40,  66, 53, 44,  64, 54, 44,  59, 51, 40,  66, 48, 38,  65, 47, 37,  62, 45, 35,  58, 41, 33,  50, 36, 27,  44, 31, 23,  39, 29, 20,  37, 28, 21,  40, 33, 25,  37, 32, 26,  33, 28, 24,  29, 26, 21,  27, 26, 22,  28, 27, 23,  25, 26, 21,  22, 23, 18,  23, 23, 13,  22, 22, 12,  23, 20, 11,  22, 19, 12,  25, 20, 14,  28, 23, 19,  33, 25, 22,  35, 27, 25,  37, 31, 31,  43, 37, 37,  38, 34, 35,  35, 33, 36,  40, 40, 42,  44, 45, 47,  57, 61, 64,  81, 85, 88, 119,134,129, 168,183,178, 219,234,229, 238,253,248, 238,253,248, 239,254,249, 239,254,249, 236,251,246, 239,254,249, 237,252,247, 234,249,244, 234,249,244, 237,252,247, 240,255,250, 241,255,251, 242,255,252,
 37, 36, 44,  63, 62, 70,  83, 83, 91,  46, 46, 54,  58, 61, 66,  82, 85, 90,  29, 34, 38,  39, 44, 47,  42, 46, 49,  54, 58, 61,  82, 83, 87, 103,103,105, 106,104,107, 108,103,107, 103, 97,101,  87, 81, 85, 111,110,106, 114,113,109, 110,109,105, 106,105,101,  77, 76, 72,  51, 50, 46,  57, 56, 52,  49, 48, 44,  63, 62, 58,  71, 70, 66,  35, 34, 30,  26, 25, 21,  14, 13,  9,  22, 21, 17,  15, 14, 10,  14, 13,  9,  20, 21,  3,  32, 31, 13,  51, 45, 29,  68, 59, 44,  81, 67, 54,  90, 70, 59,  93, 69, 59,  94, 67, 58,  89, 60, 52,  88, 59, 51,  85, 56, 48,  83, 56, 47,  86, 62, 52,  89, 69, 58,  87, 69, 57,  82, 64, 52,  84, 62, 49,  82, 63, 49,  80, 61, 47,  73, 55, 43,  64, 46, 34,  54, 37, 27,  48, 34, 25,  45, 32, 23,  55, 45, 36,  44, 35, 28,  33, 26, 18,  29, 24, 18,  31, 28, 23,  32, 29, 24,  23, 22, 17,  17, 16, 11,  23, 21,  8,  22, 20,  8,  23, 19,  8,  26, 19,  9,  28, 21, 13,  32, 23, 16,  37, 26, 22,  39, 28, 26,  31, 21, 19,  36, 26, 25,  33, 24, 25,  28, 24, 23,  29, 27, 28,  26, 26, 26,  31, 32, 34,  49, 50, 52,  73, 88, 83, 131,146,141, 195,210,205, 224,239,234, 224,239,234, 223,238,233, 232,247,242, 242,255,252, 245,255,255, 241,255,251, 236,251,246, 233,248,243, 235,250,245, 239,254,249, 243,255,253, 245,255,255,
 44, 45, 49,  59, 60, 64,  84, 85, 89,  62, 66, 69,  55, 60, 63,  87, 93, 93,  49, 55, 55,  48, 54, 54,  36, 42, 40,  43, 47, 46,  66, 70, 69,  91, 93, 90, 100,100, 98, 105,104,102, 102, 98, 97,  88, 84, 83,  84, 85, 80,  89, 90, 85,  89, 90, 85,  89, 90, 85,  61, 62, 57,  35, 36, 31,  40, 41, 36,  32, 33, 28,  53, 54, 49,  52, 53, 48,  22, 23, 18,  18, 19, 14,  12, 13,  8,  23, 24, 19,  12, 13,  8,  16, 17, 12,  30, 25,  6,  44, 37, 19,  64, 55, 38,  85, 69, 54,  98, 76, 63, 103, 76, 65, 105, 72, 63, 106, 69, 61,  99, 60, 53, 101, 62, 55, 101, 62, 55, 100, 63, 55, 104, 70, 61, 109, 76, 67, 107, 77, 67, 101, 73, 62, 101, 78, 62, 101, 78, 64,  97, 74, 60,  88, 66, 52,  76, 57, 43,  69, 51, 37,  66, 50, 37,  65, 51, 40,  71, 58, 49,  50, 40, 31,  35, 26, 17,  36, 29, 21,  39, 35, 26,  35, 30, 24,  25, 22, 15,  22, 19, 12,  28, 25, 10,  28, 25, 10,  30, 24, 10,  32, 24, 13,  35, 25, 15,  40, 27, 19,  43, 30, 24,  44, 30, 27,  36, 22, 19,  39, 28, 26,  35, 25, 24,  31, 22, 23,  27, 23, 22,  17, 15, 16,  14, 14, 14,  27, 27, 27,  23, 38, 33,  85,100, 95, 170,185,180, 228,243,238, 241,255,251, 231,246,241, 225,240,235, 228,243,238, 230,245,240, 229,244,239, 228,243,238, 229,244,239, 230,245,240, 230,245,240, 228,243,238, 226,241,236,
 20, 22, 21,  22, 26, 25,  48, 52, 51,  46, 52, 50,  21, 27, 25,  52, 61, 56,  33, 42, 37,  19, 28, 23,  26, 35, 30,  28, 35, 28,  47, 52, 46,  71, 73, 68,  82, 83, 77,  88, 87, 82,  87, 84, 79,  74, 71, 66,  76, 76, 74,  85, 85, 83,  88, 88, 86,  92, 92, 90,  67, 67, 65,  41, 41, 39,  46, 46, 44,  36, 36, 34,  29, 29, 27,  26, 26, 24,   8,  8,  6,  13, 13, 11,  10, 10,  8,  22, 22, 20,  10, 10,  8,  26, 26, 24,  36, 28,  9,  51, 40, 22,  73, 57, 41,  92, 73, 58, 106, 80, 67, 112, 80, 69, 116, 78, 69, 119, 76, 69, 111, 66, 60, 115, 68, 62, 115, 68, 62, 112, 67, 61, 115, 72, 65, 119, 79, 71, 120, 82, 73, 116, 79, 70, 117, 91, 74, 114, 88, 71, 109, 83, 68,  97, 74, 58,  89, 67, 53,  86, 67, 52,  92, 74, 60,  97, 81, 68,  87, 73, 62,  61, 48, 39,  46, 36, 26,  53, 44, 35,  55, 48, 40,  41, 37, 28,  35, 31, 22,  40, 35, 29,  45, 39, 23,  44, 38, 22,  45, 38, 22,  46, 36, 24,  49, 37, 25,  51, 37, 28,  52, 37, 30,  53, 38, 33,  48, 33, 30,  52, 38, 35,  46, 35, 33,  41, 31, 30,  34, 29, 26,  21, 17, 16,  12, 11,  9,  21, 20, 18,   2, 19, 13,  44, 61, 55, 124,141,135, 205,222,216, 244,255,255, 239,255,250, 224,241,235, 221,238,232, 229,246,240, 230,247,241, 233,250,244, 236,253,247, 237,254,248, 236,253,247, 231,248,242, 227,244,238,
 18, 23, 19,  15, 20, 16,  39, 44, 40,  50, 56, 52,  10, 19, 14,  42, 52, 44,  37, 47, 39,  14, 24, 16,  15, 25, 16,  13, 20, 12,  27, 34, 26,  50, 53, 46,  60, 61, 53,  64, 65, 57,  61, 61, 53,  50, 47, 40,  47, 47, 45,  57, 57, 55,  63, 63, 61,  69, 69, 67,  46, 46, 44,  21, 21, 19,  25, 25, 23,  16, 16, 14,  28, 28, 26,  24, 24, 22,  13, 13, 11,  19, 19, 17,  12, 12, 10,  19, 19, 17,   6,  6,  4,  29, 29, 27,  35, 24,  4,  49, 36, 17,  71, 54, 36,  91, 68, 52, 104, 75, 61, 114, 78, 66, 121, 78, 69, 125, 78, 70, 127, 77, 70, 129, 79, 72, 128, 78, 71, 124, 75, 68, 124, 77, 69, 128, 84, 75, 130, 87, 78, 130, 87, 78, 125, 98, 81, 121, 94, 77, 112, 86, 69, 103, 77, 62,  96, 73, 57, 100, 78, 64, 112, 93, 79, 122,104, 90, 100, 84, 71,  71, 59, 47,  59, 49, 39,  69, 60, 51,  68, 59, 50,  49, 42, 34,  45, 41, 32,  59, 55, 46,  59, 54, 35,  59, 52, 36,  58, 51, 35,  58, 49, 34,  59, 47, 35,  60, 46, 37,  63, 46, 38,  63, 46, 39,  55, 37, 33,  58, 43, 40,  54, 40, 39,  46, 36, 34,  41, 33, 31,  25, 19, 19,  16, 12, 11,  22, 21, 19,  17, 34, 28,  24, 41, 35,  71, 88, 82, 152,169,163, 212,229,223, 229,246,240, 231,248,242, 237,254,248, 229,246,240, 229,246,240, 230,247,241, 232,249,243, 234,251,245, 234,251,245, 233,250,244, 230,247,241,
 37, 41, 42,  39, 43, 44,  51, 53, 52,  91, 93, 92,  55, 57, 56,  68, 70, 69, 100,100, 98,  63, 63, 61,  64, 64, 62,  69, 69, 67,  73, 72, 68, 102,101, 97, 118,117,113, 112,111,107, 118,114,111, 111,108,103, 112,106, 92, 122,116,104, 124,117,107, 120,113,105, 108,101, 95,  80, 72, 70,  54, 48, 48,  51, 45, 47,  42, 37, 41,  25, 23, 26,  14, 14, 16,  14, 15, 17,  13, 17, 18,  10, 16, 14,  12, 18, 16,  16, 25, 22,  45, 27, 13,  53, 34, 20,  69, 50, 35,  91, 69, 55, 104, 81, 67, 107, 81, 66, 112, 84, 70, 121, 89, 74, 123, 90, 75, 125, 88, 72, 124, 85, 70, 125, 83, 67, 128, 85, 69, 133, 87, 72, 137, 91, 75, 140, 93, 77, 132, 95, 77, 130, 93, 77, 124, 88, 74, 117, 85, 72, 119, 89, 79, 127, 98, 90, 129,104, 97, 128,103, 98,  91, 68, 62,  95, 72, 66,  98, 73, 68,  94, 67, 60,  86, 57, 49,  85, 55, 45,  95, 63, 52, 103, 71, 58, 101, 65, 49,  97, 64, 47,  93, 62, 42,  89, 63, 40,  88, 62, 39,  87, 61, 36,  85, 57, 35,  86, 54, 33,  79, 42, 26,  85, 47, 36,  87, 50, 42,  76, 45, 42,  58, 34, 34,  38, 22, 23,  24, 15, 18,  18, 13, 17,  12, 22, 13,  25, 35, 26,  61, 74, 64, 126,142,131, 159,179,167, 218,240,227, 233,255,245, 224,252,237, 231,255,247, 220,253,236, 209,243,226, 208,242,225, 207,241,224, 205,239,222, 209,243,226, 215,249,232,
 66, 70, 71,  69, 73, 74,  83, 84, 86, 125,126,128,  89, 91, 90, 101,103,102, 131,131,131,  92, 92, 92,  81, 81, 79,  86, 86, 84,  91, 90, 88, 123,122,118, 141,140,136, 138,137,133, 146,142,139, 141,137,134, 138,132,120, 149,143,131, 153,146,136, 152,145,137, 144,136,133, 116,108,106,  87, 81, 81,  82, 76, 78,  43, 38, 42,  26, 24, 27,  15, 13, 16,  14, 14, 16,  15, 17, 16,  11, 15, 14,  14, 19, 15,  19, 25, 21,  46, 27, 13,  50, 31, 16,  65, 43, 29,  82, 60, 46,  95, 72, 58, 104, 78, 63, 115, 86, 72, 126, 94, 79, 122, 89, 74, 124, 87, 71, 124, 85, 70, 126, 84, 68, 129, 86, 70, 134, 88, 73, 138, 92, 76, 140, 94, 78, 138, 99, 82, 133, 96, 78, 127, 91, 75, 124, 91, 76, 131, 99, 88, 136,108, 97, 133,106, 97, 124, 99, 92,  98, 73, 68, 102, 77, 70, 107, 80, 73, 107, 78, 70, 104, 74, 64, 107, 75, 64, 113, 81, 68, 121, 87, 75, 116, 79, 63, 113, 77, 61, 107, 76, 56, 104, 76, 54, 101, 75, 52,  98, 72, 47,  95, 67, 43,  95, 63, 42,  87, 50, 34,  90, 52, 41,  91, 54, 46,  81, 50, 47,  64, 40, 40,  43, 29, 29,  27, 21, 23,  19, 17, 20,  14, 24, 15,  23, 35, 25,  62, 75, 65, 131,147,136, 159,179,167, 205,227,214, 213,240,225, 205,233,218, 212,245,228, 208,241,224, 208,242,225, 214,248,231, 216,250,233, 211,245,228, 208,242,225, 209,243,226,
 66, 70, 73,  70, 74, 75,  84, 85, 87, 126,127,129,  88, 89, 91,  97, 98,100, 124,124,124,  84, 84, 84,  70, 70, 70,  74, 74, 72,  78, 77, 75, 110,109,107, 130,129,127, 128,127,125, 138,134,131, 133,129,126, 124,120,109, 134,130,119, 139,135,126, 141,136,130, 135,130,126, 107,102, 99,  78, 72, 72,  71, 65, 67,  46, 42, 43,  29, 25, 26,  14, 12, 13,  14, 12, 13,  15, 15, 13,  14, 14, 12,  17, 19, 14,  23, 25, 20,  47, 28, 13,  54, 32, 18,  66, 44, 30,  83, 60, 46,  96, 70, 55, 105, 77, 63, 114, 85, 69, 124, 92, 77, 122, 89, 74, 125, 88, 72, 127, 88, 73, 130, 88, 72, 133, 90, 74, 136, 93, 77, 141, 95, 79, 143, 97, 81, 142,101, 83, 139, 98, 80, 133, 94, 77, 133, 97, 81, 140,106, 94, 144,112,101, 135,105, 95, 121, 92, 84, 114, 85, 77, 116, 87, 79, 119, 91, 80, 122, 92, 82, 125, 93, 82, 128, 94, 82, 131, 98, 83, 136,100, 86, 132, 93, 78, 129, 92, 76, 124, 91, 72, 121, 90, 69, 116, 88, 66, 111, 83, 59, 107, 77, 53, 103, 71, 50,  96, 60, 44,  97, 59, 48,  93, 59, 50,  84, 55, 51,  68, 47, 44,  47, 35, 35,  31, 25, 25,  19, 19, 19,  19, 29, 20,  22, 34, 24,  62, 75, 65, 140,156,145, 168,188,176, 207,231,217, 219,246,231, 219,250,234, 209,242,225, 211,244,227, 218,252,235, 228,255,245, 230,255,247, 223,255,240, 214,248,231, 210,244,227,
 85, 89, 92,  88, 92, 95, 101,102,106, 140,141,145, 100,101,105, 108,109,111, 135,135,137,  94, 94, 96,  88, 88, 90,  90, 90, 90,  91, 89, 90, 121,119,120, 140,139,137, 138,137,135, 147,143,142, 141,137,136, 130,127,120, 139,136,129, 142,139,134, 144,141,136, 139,135,132, 112,108,107,  83, 79, 80,  76, 72, 73,  47, 43, 44,  31, 27, 28,  18, 14, 13,  16, 12,  9,  17, 13, 10,  17, 14,  9,  22, 19, 12,  31, 28, 21,  55, 33, 19,  65, 43, 29,  83, 60, 44,  98, 75, 59, 109, 83, 68, 112, 84, 70, 114, 85, 69, 117, 85, 70, 120, 87, 70, 124, 87, 71, 126, 87, 72, 129, 87, 71, 132, 90, 74, 136, 93, 77, 139, 96, 80, 143, 97, 81, 141, 99, 77, 141, 98, 79, 138, 97, 79, 137, 98, 81, 142,105, 89, 144,108, 94, 135,101, 89, 124, 92, 81, 130, 98, 87, 130, 98, 87, 131, 99, 86, 134,100, 88, 138,102, 88, 138,102, 86, 138,101, 85, 137,100, 82, 140, 98, 84, 137, 98, 83, 132, 97, 78, 127, 96, 75, 121, 93, 71, 114, 86, 62, 108, 78, 54, 104, 72, 51, 102, 67, 48, 100, 64, 50,  93, 59, 50,  83, 54, 48,  67, 48, 44,  47, 37, 35,  28, 27, 25,  18, 20, 19,  10, 22, 12,   7, 19,  9,  47, 60, 50, 129,147,135, 159,179,167, 195,219,205, 213,241,226, 228,255,243, 205,238,221, 205,239,222, 207,241,224, 211,245,228, 212,246,229, 208,242,225, 202,236,219, 199,232,215,
 80, 83, 88,  81, 84, 89,  92, 93, 98, 130,131,136,  91, 92, 97, 101,102,106, 130,129,134,  92, 91, 96,  88, 88, 90,  88, 88, 90,  88, 86, 89, 117,115,118, 137,135,136, 135,133,134, 142,138,139, 135,131,132, 127,126,121, 136,135,131, 139,138,134, 140,139,137, 135,134,132, 113,109,110,  88, 84, 85,  84, 80, 81,  47, 41, 43,  33, 27, 27,  22, 17, 14,  21, 13, 10,  20, 13,  7,  21, 14,  6,  32, 25, 15,  45, 38, 28,  75, 52, 36,  86, 63, 47, 103, 77, 62, 115, 89, 74, 122, 95, 78, 124, 95, 79, 125, 93, 78, 123, 90, 75, 120, 84, 68, 121, 84, 68, 123, 84, 69, 124, 85, 68, 129, 87, 71, 133, 90, 74, 137, 94, 78, 139, 96, 80, 141, 95, 72, 144, 99, 76, 145,100, 79, 141, 98, 79, 141,100, 82, 141,102, 85, 138,101, 85, 133, 97, 81, 139,103, 89, 138,102, 88, 138,102, 86, 141,104, 88, 143,106, 88, 143,104, 87, 140,102, 83, 138, 97, 79, 142, 98, 85, 139, 97, 83, 133, 96, 78, 127, 95, 74, 122, 91, 70, 115, 85, 61, 107, 77, 53, 102, 70, 49, 102, 67, 48,  98, 62, 48,  89, 57, 46,  77, 50, 43,  60, 43, 36,  42, 34, 31,  24, 25, 20,  14, 19, 15,  18, 31, 21,  13, 26, 16,  53, 69, 58, 139,157,145, 162,184,171, 190,214,200, 205,233,218, 221,252,236, 217,250,233, 210,244,227, 203,237,220, 197,231,214, 197,231,214, 201,235,218, 205,238,221, 206,239,222,
 61, 64, 71,  62, 65, 72,  73, 73, 81, 112,112,120,  75, 76, 81,  87, 88, 93, 119,118,124,  82, 81, 86,  72, 71, 76,  72, 71, 76,  73, 71, 76, 105,103,106, 127,125,128, 126,124,127, 132,127,131, 124,119,123, 121,121,119, 132,132,130, 137,137,137, 138,138,138, 132,132,132, 110,108,109,  89, 87, 88,  90, 86, 87,  42, 36, 36,  35, 27, 25,  29, 19, 17,  27, 18, 11,  27, 17,  8,  32, 19, 10,  50, 38, 26,  72, 58, 45, 104, 78, 61, 112, 86, 69, 121, 94, 77, 124, 97, 80, 128, 99, 83, 131,102, 86, 134,103, 85, 133,100, 83, 123, 87, 71, 123, 86, 70, 122, 85, 69, 123, 84, 67, 127, 85, 69, 131, 89, 73, 136, 94, 78, 140, 97, 81, 139, 91, 68, 145, 97, 74, 147,101, 77, 145, 99, 76, 142, 97, 76, 143,100, 81, 143,102, 82, 143,102, 84, 140,102, 83, 140,102, 83, 140,102, 83, 144,103, 85, 146,105, 87, 145,104, 84, 144,101, 82, 142, 99, 80, 142, 95, 85, 138, 94, 81, 132, 93, 76, 126, 91, 72, 120, 88, 67, 113, 83, 59, 107, 75, 52, 104, 69, 49, 100, 65, 46,  96, 60, 46,  85, 53, 42,  68, 44, 34,  50, 35, 28,  32, 27, 21,  20, 22, 17,  13, 19, 15,  22, 35, 25,  23, 39, 28,  73, 91, 79, 160,180,168, 181,203,190, 198,225,210, 205,233,218, 216,247,231, 226,255,242, 219,253,236, 208,242,225, 199,233,216, 201,235,218, 211,245,228, 220,253,236, 223,255,239,
 16, 19, 26,  19, 22, 29,  31, 31, 39,  71, 71, 79,  33, 33, 41,  44, 44, 52,  73, 72, 78,  35, 34, 40,  24, 23, 29,  25, 24, 29,  27, 25, 30,  61, 59, 64,  84, 82, 87,  83, 81, 84,  89, 84, 88,  79, 74, 78,  74, 75, 77,  90, 91, 93,  98, 99,101,  97, 98,100,  87, 87, 89,  60, 60, 62,  41, 39, 42,  43, 39, 40,  35, 29, 29,  33, 25, 22,  35, 24, 20,  37, 24, 16,  36, 22, 11,  46, 30, 17,  73, 55, 41, 101, 82, 67, 126, 99, 82, 134,105, 89, 138,109, 93, 135,106, 88, 134,103, 85, 133,102, 84, 130, 97, 80, 125, 92, 75, 118, 82, 66, 116, 79, 63, 113, 76, 58, 113, 74, 57, 115, 76, 59, 120, 81, 64, 127, 85, 69, 131, 89, 73, 135, 85, 60, 140, 90, 65, 142, 95, 69, 142, 94, 71, 144, 98, 74, 147,101, 78, 146,101, 78, 143, 98, 77, 140, 98, 76, 141, 99, 77, 142,100, 78, 143,101, 79, 142,100, 78, 144, 99, 78, 144, 99, 78, 144, 99, 78, 140, 92, 82, 137, 91, 78, 130, 88, 74, 123, 86, 68, 117, 85, 64, 112, 80, 57, 107, 75, 52, 105, 70, 48,  99, 64, 44,  93, 60, 43,  81, 52, 38,  63, 41, 30,  43, 29, 20,  26, 23, 14,  17, 22, 15,  15, 25, 17,   9, 25, 14,  19, 35, 24,  73, 91, 79, 158,180,167, 176,200,186, 191,218,203, 193,224,208, 199,232,215, 205,239,222, 206,240,223, 202,236,219, 196,230,213, 199,233,216, 207,240,223, 210,243,226, 207,240,223,
 21, 24, 33,  24, 27, 36,  37, 37, 47,  76, 76, 84,  36, 36, 44,  43, 43, 51,  69, 68, 76,  28, 27, 33,  23, 22, 28,  24, 23, 29,  26, 24, 29,  60, 58, 63,  84, 82, 87,  82, 80, 85,  86, 81, 87,  75, 70, 76,  67, 68, 72,  85, 86, 90,  94, 95, 99,  92, 93, 97,  76, 77, 81,  45, 45, 47,  22, 20, 23,  24, 20, 21,  30, 25, 22,  33, 24, 19,  39, 26, 18,  44, 27, 17,  45, 27, 15,  58, 36, 22,  90, 67, 51, 122, 99, 81, 139,108, 90, 149,118,100, 154,123,105, 149,118,100, 141,108, 91, 132, 99, 82, 118, 85, 68, 108, 72, 56, 103, 67, 51, 101, 64, 46,  97, 60, 42,  94, 57, 39,  96, 57, 40, 102, 63, 46, 108, 69, 52, 112, 73, 56, 130, 80, 53, 133, 83, 56, 136, 86, 61, 140, 90, 65, 145, 98, 72, 150,102, 79, 145, 97, 74, 136, 90, 66, 142, 96, 73, 143, 97, 74, 143, 98, 75, 141, 96, 73, 139, 94, 71, 137, 92, 69, 138, 93, 72, 140, 95, 74, 139, 89, 80, 133, 87, 74, 127, 83, 70, 119, 82, 64, 116, 81, 61, 110, 78, 55, 106, 74, 51, 105, 70, 48,  99, 64, 44,  94, 61, 44,  82, 53, 39,  62, 40, 27,  39, 26, 17,  24, 21, 12,  18, 24, 14,  17, 29, 19,  23, 41, 29,  33, 51, 39,  81,101, 89, 160,182,169, 171,198,183, 188,216,201, 191,222,206, 196,229,212, 197,231,214, 203,237,220, 207,241,224, 207,241,224, 209,243,226, 212,245,228, 206,239,222, 196,229,212,
 50, 53, 62,  50, 53, 62,  70, 70, 80, 100,100,108,  61, 61, 69,  80, 80, 88, 100, 99,107,  64, 63, 69,  56, 55, 61,  50, 49, 55,  56, 54, 59,  91, 89, 94, 107,105,110, 105,103,108, 111,106,112,  94, 89, 95,  89, 90, 95, 104,105,110,  98, 99,104, 102,103,108,  87, 88, 92,  49, 50, 54,  36, 36, 38,  36, 32, 31,  33, 28, 25,  51, 42, 37,  42, 29, 21,  58, 40, 28,  47, 25, 11,  69, 43, 28, 105, 78, 61, 136,107, 89, 149,116, 97, 151,118, 99, 152,119,100, 150,117, 98, 145,110, 91, 134, 99, 80, 123, 88, 69, 116, 81, 62, 116, 81, 62, 121, 84, 66, 117, 80, 62, 105, 68, 50, 100, 63, 45, 103, 66, 48, 100, 63, 45,  92, 55, 37, 111, 61, 36, 116, 66, 41, 124, 74, 49, 133, 83, 58, 140, 90, 65, 145, 95, 70, 144, 97, 71, 144, 97, 71, 144, 96, 73, 142, 96, 72, 141, 95, 72, 140, 94, 71, 138, 93, 70, 136, 91, 70, 133, 88, 67, 130, 85, 64, 137, 87, 78, 131, 84, 74, 122, 78, 65, 114, 77, 59, 111, 76, 56, 110, 78, 55, 111, 79, 56, 113, 78, 56, 105, 70, 50, 100, 67, 48,  86, 57, 41,  65, 43, 30,  44, 32, 20,  29, 27, 15,  22, 28, 16,  18, 30, 18,  28, 48, 36,  42, 62, 50, 109,131,118, 171,195,181, 184,211,196, 201,229,214, 218,251,234, 210,243,226, 201,235,218, 205,239,222, 207,241,224, 204,238,221, 201,234,217, 199,232,215, 197,230,213, 196,227,211,
 33, 36, 43,  33, 36, 43,  53, 53, 61,  83, 83, 91,  44, 44, 52,  62, 62, 70,  82, 81, 87,  46, 45, 51,  44, 43, 49,  39, 38, 43,  46, 44, 49,  82, 80, 85,  99, 97,102,  97, 95, 98, 103, 98,102,  85, 80, 84,  98, 99,104, 113,114,119, 109,110,115, 114,115,120, 101,102,106,  64, 65, 69,  51, 51, 53,  51, 47, 46,  34, 29, 25,  50, 39, 33,  43, 29, 20,  66, 46, 35,  59, 36, 22,  77, 50, 33, 115, 84, 66, 147,116, 96, 157,120,101, 159,122,103, 160,123,104, 157,120,101, 150,113, 94, 142,105, 87, 135, 98, 80, 133, 96, 78, 129, 92, 74, 137,100, 82, 143,106, 88, 143,106, 88, 140,103, 87, 132, 95, 79, 120, 83, 67, 109, 72, 56, 113, 65, 42, 115, 68, 42, 121, 74, 48, 127, 80, 54, 134, 84, 59, 136, 86, 61, 136, 86, 61, 133, 86, 60, 135, 88, 62, 133, 85, 62, 128, 82, 58, 124, 78, 55, 120, 75, 54, 115, 73, 51, 113, 70, 51, 111, 68, 49, 112, 64, 54, 114, 67, 57, 116, 74, 60, 118, 81, 63, 118, 86, 65, 115, 83, 60, 111, 79, 54, 109, 74, 52, 111, 76, 54, 103, 70, 51,  95, 66, 50,  79, 57, 43,  48, 34, 21,  17, 15,  2,  17, 23,  9,  35, 46, 32,  58, 80, 67,  66, 88, 75, 120,144,130, 173,200,185, 187,215,200, 201,232,216, 212,245,228, 198,232,215, 191,225,208, 189,223,206, 188,222,205, 190,224,207, 194,227,210, 198,231,214, 206,237,221, 211,242,226,
 53, 56, 63,  52, 55, 62,  73, 73, 81, 102,102,110,  64, 65, 70,  82, 83, 88, 102,101,107,  66, 65, 70,  60, 59, 64,  57, 56, 61,  65, 63, 68, 103,101,104, 120,118,121, 118,116,119, 123,118,122, 105,100,104,  94, 93, 99, 111,110,116, 108,107,113, 114,113,119, 101,102,106,  64, 64, 66,  51, 51, 51,  52, 48, 47,  45, 40, 36,  61, 50, 44,  52, 38, 29,  74, 55, 41,  67, 41, 26,  83, 54, 38, 117, 84, 65, 148,113, 94, 146,108, 87, 147,109, 88, 146,108, 87, 137, 99, 80, 124, 86, 67, 114, 77, 58, 110, 73, 54, 111, 74, 55, 102, 65, 47, 100, 63, 45, 102, 67, 48, 108, 73, 54, 115, 79, 63, 119, 83, 67, 126, 90, 74, 132, 96, 80, 117, 71, 48, 118, 72, 49, 121, 75, 52, 125, 79, 55, 131, 83, 60, 133, 85, 62, 133, 86, 60, 131, 84, 58, 137, 89, 66, 131, 85, 61, 123, 77, 54, 113, 68, 47, 105, 62, 43, 100, 59, 39,  98, 57, 39,  96, 58, 39,  95, 48, 40,  94, 50, 39,  94, 55, 40,  95, 60, 41,  97, 65, 44,  99, 69, 45, 104, 72, 47, 107, 73, 48, 118, 83, 61, 114, 79, 59, 107, 76, 58,  86, 63, 47,  51, 38, 22,  23, 20,  5,  26, 30, 16,  45, 53, 40,  54, 76, 63,  78,102, 88, 142,166,152, 191,218,203, 196,224,209, 195,228,211, 196,229,212, 181,215,198, 192,229,211, 189,226,208, 195,229,212, 204,238,221, 205,238,221, 196,229,212, 191,222,206, 191,222,206,
 23, 26, 31,  22, 25, 30,  43, 44, 49,  73, 74, 79,  34, 35, 40,  52, 53, 57,  72, 71, 76,  36, 35, 40,  25, 25, 27,  22, 22, 24,  32, 30, 33,  70, 68, 71,  88, 86, 87,  86, 84, 85,  90, 86, 87,  71, 67, 68,  92, 87, 93, 108,103,109, 102,100,105, 106,105,110,  93, 92, 97,  55, 55, 57,  41, 41, 41,  41, 37, 36,  44, 39, 35,  68, 57, 51,  57, 43, 34,  69, 50, 36,  64, 38, 23,  93, 61, 46, 126, 91, 72, 141,106, 87, 153,112, 92, 156,115, 95, 155,114, 94, 145,104, 84, 129, 91, 70, 119, 81, 62, 118, 80, 61, 119, 82, 63, 103, 66, 48,  85, 48, 30,  68, 33, 14,  61, 26,  7,  58, 22,  6,  57, 24,  7,  69, 36, 19,  84, 51, 34, 114, 71, 52, 114, 71, 52, 116, 74, 52, 123, 78, 57, 131, 85, 62, 136, 90, 67, 136, 90, 66, 135, 89, 65, 124, 78, 55, 121, 76, 53, 117, 72, 51, 113, 70, 51, 112, 71, 53, 115, 76, 59, 120, 83, 67, 125, 88, 72, 139, 95, 86, 134, 92, 80, 124, 87, 71, 112, 79, 60, 103, 72, 51,  98, 68, 44,  96, 66, 40,  98, 66, 41, 120, 85, 63, 122, 87, 67, 111, 80, 62,  85, 59, 44,  53, 37, 22,  36, 30, 16,  37, 39, 25,  45, 51, 37,  79,103, 89, 124,148,134, 188,215,200, 218,246,231, 203,234,218, 194,227,210, 201,235,218, 201,235,218, 196,233,215, 191,228,210, 198,232,215, 209,243,226, 209,242,225, 194,227,210, 184,215,199, 182,213,197,
 22, 26, 29,  21, 25, 28,  41, 42, 46,  71, 72, 76,  32, 33, 37,  51, 52, 54,  71, 71, 73,  35, 35, 37,  26, 26, 28,  23, 23, 23,  32, 30, 31,  70, 68, 69,  87, 86, 84,  85, 84, 82,  89, 85, 84,  70, 66, 65,  83, 76, 83,  97, 90, 97,  90, 85, 91,  90, 88, 91,  75, 73, 76,  35, 35, 37,  22, 20, 21,  21, 17, 14,  30, 25, 21,  67, 56, 50,  57, 43, 34,  58, 39, 25,  58, 32, 19, 105, 73, 58, 137,101, 85, 139,102, 84, 153,111, 89, 159,117, 95, 164,122,100, 159,118, 98, 151,110, 90, 147,106, 86, 147,109, 90, 151,113, 94, 153,116, 97, 138,101, 83, 124, 89, 70, 117, 81, 65, 105, 72, 55,  94, 61, 44,  93, 60, 43, 100, 67, 50, 112, 73, 56, 110, 72, 53, 114, 73, 55, 121, 78, 59, 129, 87, 65, 136, 91, 70, 136, 91, 68, 134, 89, 66, 136, 91, 70, 131, 89, 67, 123, 82, 62, 113, 75, 56, 105, 68, 52, 103, 67, 53, 104, 71, 56, 108, 74, 62, 116, 73, 64, 121, 81, 69, 127, 91, 75, 127, 96, 76, 122, 94, 72, 116, 88, 64, 112, 82, 56, 109, 77, 52, 122, 87, 65, 120, 85, 65, 113, 80, 61,  92, 65, 48,  52, 35, 19,  25, 18,  2,  36, 37, 21,  66, 70, 55, 132,159,144, 166,193,178, 202,230,215, 205,233,218, 185,216,200, 183,216,199, 199,233,216, 208,245,227, 190,227,209, 182,219,201, 181,215,198, 187,221,204, 192,225,208, 193,224,208, 198,229,213, 207,238,222,
 48, 52, 55,  47, 51, 52,  68, 69, 71,  98, 99,101,  59, 60, 62,  77, 78, 80,  97, 97, 97,  61, 61, 61,  54, 54, 54,  51, 51, 49,  58, 57, 55,  94, 93, 91, 111,110,108, 108,107,105, 112,108,105,  93, 89, 86, 101, 92, 97, 114,105,110, 103, 97,101, 103, 98,102,  85, 83, 86,  47, 45, 46,  35, 34, 32,  35, 31, 28,  42, 37, 33,  81, 72, 65,  71, 57, 48,  68, 48, 37,  66, 40, 27, 110, 78, 63, 135, 99, 83, 128, 91, 73, 140, 95, 74, 145,100, 79, 147,105, 83, 146,104, 82, 143,101, 79, 140, 99, 79, 141,103, 82, 145,107, 88, 133, 96, 77, 129, 92, 74, 125, 90, 71, 124, 91, 74, 122, 89, 72, 120, 87, 70, 119, 88, 70, 122, 91, 73, 124, 88, 72, 123, 86, 70, 123, 86, 68, 130, 91, 74, 139, 98, 80, 144,101, 82, 141, 99, 77, 137, 95, 73, 124, 81, 62, 119, 78, 58, 106, 68, 49,  89, 52, 36,  72, 36, 22,  57, 25, 12,  51, 21, 10,  51, 21, 11,  68, 28, 18,  77, 39, 28,  89, 56, 41, 100, 69, 49, 106, 78, 56, 111, 83, 59, 119, 89, 63, 123, 91, 66, 122, 88, 63, 114, 78, 56, 112, 79, 60, 101, 74, 57,  52, 33, 18,  12,  3,  0,  47, 44, 29, 113,115,101, 147,174,159, 171,198,183, 186,214,199, 183,214,198, 182,215,198, 187,221,204, 190,224,207, 186,223,205, 189,226,208, 189,226,208, 190,224,207, 188,222,205, 188,221,204, 191,222,206, 195,226,210, 199,230,214,
 89, 93, 94,  89, 93, 94, 109,110,112, 139,140,142, 100,102,101, 119,121,120, 139,139,139, 102,102,102,  97, 97, 95,  91, 91, 89,  97, 96, 94, 131,130,126, 146,145,141, 142,141,137, 147,143,140, 128,124,121, 141,130,134, 153,142,146, 143,134,137, 142,136,138, 127,123,124,  90, 88, 89,  81, 80, 78,  83, 79, 76,  80, 75, 69, 108, 99, 92,  98, 84, 75, 102, 82, 71,  94, 68, 55, 118, 86, 71, 131, 95, 79, 125, 88, 72, 138, 93, 70, 139, 94, 71, 139, 94, 73, 135, 93, 71, 135, 93, 71, 136, 95, 75, 140, 99, 79, 142,104, 85, 146,109, 90, 146,109, 91, 140,105, 86, 131, 98, 81, 130, 97, 80, 132,101, 83, 134,103, 85, 133,102, 84, 138,104, 92, 136,103, 88, 138,102, 88, 144,107, 91, 152,113, 96, 156,115, 97, 151,110, 90, 146,103, 84, 142,101, 81, 141,103, 84, 138,101, 83, 130, 94, 80, 120, 86, 74, 111, 81, 70, 110, 82, 71, 113, 84, 76, 111, 73, 62, 113, 77, 65, 112, 80, 65, 109, 81, 60, 105, 79, 56, 105, 79, 54, 110, 83, 56, 118, 86, 61, 120, 84, 60, 117, 81, 59, 113, 78, 59,  91, 62, 46,  56, 34, 20,  46, 34, 18,  95, 92, 77, 158,159,143, 149,176,161, 175,203,188, 191,219,204, 193,224,208, 203,236,219, 207,241,224, 193,230,212, 179,216,198, 186,223,205, 198,235,217, 206,240,223, 197,231,214, 189,222,205, 189,220,204, 186,217,201, 182,210,195,
 92, 96, 97,  92, 96, 97, 112,114,113, 142,144,143, 103,105,104, 122,124,123, 142,142,140, 106,106,104, 104,104,102,  98, 98, 96, 101,100, 96, 134,133,129, 148,147,143, 144,143,139, 149,145,142, 130,127,122, 144,132,136, 155,144,148, 146,137,140, 146,140,142, 133,129,130,  99, 97, 98,  93, 92, 90,  96, 92, 89, 104, 99, 93, 123,114,107, 115,101, 92, 134,114,103, 125, 99, 86, 132,100, 87, 138,102, 88, 140,103, 87, 133, 87, 64, 130, 85, 62, 129, 84, 61, 130, 85, 64, 133, 91, 69, 141, 99, 77, 149,108, 88, 152,114, 95, 154,117, 98, 162,125,107, 163,128,109, 156,123,106, 155,122,105, 157,126,108, 154,123,105, 145,113, 98, 140,108, 95, 139,105, 93, 140,107, 92, 149,113, 97, 157,120,102, 160,122,103, 156,115, 97, 149,108, 88, 143,102, 84, 144,105, 88, 143,106, 90, 133,100, 85, 122, 90, 79, 113, 83, 73, 110, 81, 73, 110, 83, 76, 133, 97, 85, 139,105, 93, 146,114, 99, 144,117, 96, 137,111, 88, 128,102, 77, 122, 95, 68, 122, 90, 65, 116, 80, 56, 128, 92, 70, 112, 77, 58,  69, 40, 22,  58, 37, 20, 100, 87, 71, 153,147,133, 180,178,163, 153,181,166, 184,212,197, 194,225,209, 188,219,203, 190,223,206, 193,227,210, 183,220,202, 176,213,195, 172,209,191, 188,225,207, 193,227,210, 179,213,196, 174,207,190, 188,219,203, 198,229,213, 198,226,211,
 81, 80, 78,  84, 83, 81, 107,103,102, 137,133,132, 107,101,101, 106,101, 98, 145,137,135, 104, 96, 94,  84, 74, 72,  99, 88, 86, 103, 89, 86, 124,110,107, 147,132,129, 155,140,137, 157,142,137, 135,120,115, 137,128,131, 142,133,136, 143,137,141, 143,138,144, 126,123,130,  93, 90, 97,  80, 79, 85,  97, 95,100, 127,122,126, 144,135,136, 139,128,124, 131,116,109, 121,101, 90, 128,105, 91, 145,119,102, 127,100, 81, 131, 88, 72, 130, 87, 70, 132, 86, 70, 137, 90, 72, 145, 97, 77, 155,104, 83, 162,110, 88, 166,111, 90, 172,117, 96, 177,122,101, 183,128,108, 181,129,108, 173,120,102, 161,110, 93, 153,102, 85, 148, 96, 82, 143, 86, 67, 143, 86, 67, 147, 92, 72, 159,107, 86, 172,119,101, 173,122,103, 160,112, 92, 148, 99, 82, 147, 98, 81, 157,108, 91, 165,116, 99, 164,112, 98, 159,106, 92, 155,102, 88, 153, 97, 84, 150, 94, 81, 148,100, 77, 149,101, 78, 153,103, 80, 157,107, 82, 159,109, 84, 155,107, 84, 146,102, 77, 136, 98, 75, 118, 86, 65, 126,104, 83,  91, 78, 59,  58, 57, 39,  98,107, 90, 159,175,162, 175,199,185, 167,193,180, 178,204,193, 179,205,194, 179,205,194, 176,204,192, 176,204,192, 180,208,196, 188,216,204, 192,222,210, 181,211,199, 186,216,204, 185,215,203, 178,210,197, 181,213,200, 189,221,208, 186,218,205, 174,206,193,
 87, 85, 86,  88, 86, 87, 106,105,103, 136,132,131, 105,101,100, 105, 99, 99, 143,138,135, 106, 98, 96, 100, 90, 89,  96, 86, 85,  96, 85, 83, 134,123,121, 164,150,149, 157,143,142, 145,131,128, 123,108,105, 145,136,141, 144,138,142, 136,131,137, 131,126,132, 126,123,130, 120,119,125, 132,131,137, 159,158,163, 211,206,210, 220,214,214, 212,203,198, 194,179,172, 153,135,123, 128,105, 91, 137,111, 94, 130,103, 84, 134, 91, 74, 132, 89, 72, 134, 89, 70, 138, 91, 71, 146, 98, 76, 155,104, 83, 161,109, 87, 165,110, 89, 168,113, 92, 166,111, 90, 162,107, 87, 154,102, 81, 146, 93, 75, 138, 87, 70, 133, 81, 67, 128, 79, 64, 146, 90, 73, 143, 90, 72, 146, 93, 75, 155,104, 85, 164,116, 96, 165,118, 98, 155,108, 88, 144, 99, 80, 138, 93, 74, 143, 96, 78, 147,100, 82, 153,104, 87, 164,112, 98, 173,120,106, 174,121,107, 169,116,102, 164,114, 91, 162,112, 89, 159,109, 84, 158,108, 83, 157,107, 82, 151,103, 80, 144, 99, 76, 135, 97, 74, 133,101, 80, 115, 93, 72,  98, 85, 68, 110,109, 91, 150,158,143, 175,191,178, 170,194,181, 160,186,173, 173,199,188, 183,209,198, 195,221,210, 199,225,214, 195,223,211, 190,218,206, 189,217,205, 190,218,206, 187,217,205, 186,216,204, 187,217,205, 189,221,208, 191,223,210, 188,220,207, 185,217,204, 184,216,203,
105,103,104, 104,102,103, 120,118,119, 146,144,145, 116,112,113, 116,112,111, 156,152,151, 118,112,112, 112,106,106, 113,104,105, 111,102,103, 142,132,131, 163,153,152, 158,148,147, 157,145,145, 143,131,131, 121,114,121, 140,135,141, 155,152,159, 168,165,172, 186,185,193, 199,199,207, 215,215,223, 236,235,241, 217,215,218, 210,204,204, 197,187,185, 196,181,174, 169,151,139, 141,119,105, 144,118,101, 135,108, 89, 135, 90, 71, 133, 88, 69, 133, 86, 66, 135, 87, 65, 142, 91, 70, 149, 97, 75, 153,101, 79, 157,103, 79, 167,113, 89, 160,105, 84, 150, 95, 75, 140, 88, 67, 133, 82, 63, 127, 76, 59, 118, 69, 54, 113, 64, 49, 126, 77, 60, 124, 75, 58, 125, 78, 60, 131, 86, 67, 141, 96, 77, 142, 99, 80, 136, 93, 74, 128, 87, 67, 129, 86, 67, 126, 83, 64, 125, 80, 61, 132, 85, 67, 150,103, 85, 168,119,102, 174,123,106, 170,119,102, 174,122, 98, 169,117, 93, 162,110, 86, 157,105, 81, 152,102, 77, 146, 98, 75, 141, 96, 73, 134, 96, 75, 131,100, 80, 108, 87, 68, 127,115, 99, 171,169,154, 180,188,175, 160,176,165, 156,177,168, 166,192,181, 159,185,174, 171,197,186, 185,211,200, 192,218,207, 191,217,206, 188,214,203, 189,217,205, 191,219,207, 179,207,195, 171,201,189, 174,204,192, 184,214,202, 183,213,201, 171,203,190, 170,202,189, 178,210,197,
 95, 95, 95,  95, 95, 95, 113,113,113, 141,139,140, 110,108,109, 110,108,109, 149,147,148, 112,108,109, 101, 97, 98, 108,104,105, 106,100,102, 126,120,122, 145,139,141, 148,142,144, 150,144,146, 135,126,129, 135,132,139, 169,166,173, 195,194,202, 208,208,216, 219,219,229, 216,219,228, 206,209,218, 205,205,213, 211,210,215, 202,198,199, 187,177,175, 184,171,163, 161,143,131, 137,115,101, 138,112, 95, 124, 97, 78, 130, 83, 63, 128, 82, 59, 126, 78, 56, 128, 78, 55, 132, 82, 59, 137, 85, 61, 142, 88, 64, 143, 89, 65, 142, 88, 64, 137, 82, 61, 130, 78, 57, 130, 79, 60, 133, 82, 65, 129, 80, 65, 121, 74, 58, 114, 66, 52, 100, 57, 40,  98, 55, 38,  96, 55, 37,  99, 58, 40, 101, 63, 44, 102, 64, 43,  97, 61, 39,  92, 56, 34, 118, 80, 59, 116, 78, 57, 113, 72, 52, 114, 72, 50, 126, 81, 60, 143, 96, 76, 155,107, 87, 158,110, 90, 172,118, 94, 167,113, 89, 159,107, 83, 153,101, 77, 147, 97, 74, 142, 94, 72, 138, 93, 72, 131, 94, 75, 129,100, 82, 119, 98, 81, 156,144,130, 200,198,186, 189,197,186, 165,181,171, 173,194,187, 190,213,207, 184,207,199, 182,205,197, 178,201,193, 172,195,187, 165,191,182, 164,190,181, 167,193,184, 170,197,188, 174,201,192, 172,199,190, 174,201,192, 176,206,196, 173,203,193, 167,197,187, 170,200,190, 178,208,198,
 49, 49, 51,  51, 51, 53,  73, 73, 75, 102,102,104,  72, 72, 74,  72, 72, 74, 109,108,113,  69, 68, 73,  60, 59, 64,  57, 55, 60,  56, 54, 59,  93, 91, 96, 117,115,120, 112,109,116, 116,113,120, 111,108,115, 192,191,199, 216,215,223, 224,224,234, 216,219,228, 215,217,229, 206,210,221, 190,194,203, 182,185,192, 195,194,199, 210,206,207, 204,196,193, 183,170,162, 139,123,110, 116, 94, 80, 128,105, 87, 123, 98, 78, 127, 79, 56, 124, 76, 53, 120, 72, 49, 121, 71, 46, 124, 72, 48, 127, 76, 49, 131, 77, 51, 132, 78, 52, 128, 74, 50, 121, 69, 47, 119, 67, 46, 124, 73, 54, 133, 84, 67, 139, 92, 76, 137, 91, 76, 132, 86, 71, 118, 79, 62, 116, 77, 60, 113, 76, 58, 113, 76, 58, 112, 77, 58, 110, 75, 55, 106, 71, 51, 103, 68, 46, 117, 82, 60, 124, 88, 66, 125, 87, 64, 118, 77, 55, 113, 71, 49, 125, 80, 57, 143, 97, 74, 157,109, 87, 164,108, 83, 161,107, 81, 158,104, 80, 151, 99, 75, 145, 95, 72, 138, 92, 69, 133, 90, 71, 127, 92, 73, 124, 97, 80, 123,104, 90, 152,142,132, 178,178,168, 180,187,180, 182,197,192, 188,207,203, 177,199,196, 184,205,198, 178,201,193, 172,195,187, 169,192,184, 171,194,186, 174,197,189, 174,200,191, 174,200,191, 182,208,199, 188,214,205, 187,214,205, 179,206,197, 176,203,194, 183,210,201, 186,216,206, 186,216,206,
 21, 22, 26,  23, 24, 28,  46, 47, 51,  76, 77, 81,  47, 48, 52,  47, 48, 52,  84, 85, 90,  43, 44, 49,  28, 29, 34,  20, 20, 28,  28, 28, 36,  73, 73, 81,  86, 86, 94,  78, 78, 86, 126,126,136, 179,179,189, 222,222,232, 234,237,246, 233,236,245, 223,227,238, 225,229,240, 220,227,237, 211,218,228, 211,215,224, 178,179,184, 191,189,192, 185,180,177, 170,159,153, 140,123,113, 124,105, 90, 137,114, 96, 125,100, 80, 128, 81, 55, 124, 77, 51, 122, 72, 47, 120, 70, 43, 122, 71, 44, 126, 72, 46, 128, 74, 48, 128, 74, 48, 133, 79, 55, 120, 68, 46, 108, 57, 36, 103, 55, 35, 106, 59, 41, 110, 64, 48, 109, 66, 50, 107, 63, 50, 117, 79, 66, 120, 82, 69, 123, 87, 73, 127, 91, 75, 130, 94, 78, 130, 97, 78, 130, 98, 77, 131, 96, 76, 127, 92, 70, 139,103, 81, 142,104, 81, 130, 88, 64, 116, 71, 48, 117, 71, 47, 133, 85, 62, 147, 99, 76, 156,100, 75, 157,101, 76, 155,101, 77, 150, 98, 76, 142, 94, 72, 135, 90, 69, 130, 89, 71, 124, 91, 74, 132,106, 93, 156,138,128, 180,171,162, 180,179,174, 174,180,176, 182,194,192, 180,198,198, 165,185,184, 165,186,181, 169,190,185, 177,198,193, 185,206,201, 191,212,207, 190,213,207, 184,207,201, 179,202,196, 176,199,193, 182,207,201, 180,205,199, 169,194,188, 168,193,187, 179,206,199, 184,211,204, 179,206,199,
 36, 37, 41,  37, 38, 42,  58, 59, 63,  85, 88, 93,  55, 58, 63,  55, 58, 63,  94, 97,102,  54, 57, 64,  34, 37, 44,  38, 41, 50,  44, 47, 56,  75, 78, 87,  90, 93,102, 108,110,122, 179,181,193, 240,242,254, 228,231,240, 235,238,247, 230,234,245, 224,228,239, 222,228,240, 213,219,231, 200,207,217, 202,206,215, 205,208,213, 196,196,198, 181,176,173, 180,169,163, 162,148,137, 140,121,107, 134,113, 96, 110, 87, 69, 130, 83, 57, 127, 80, 54, 124, 74, 49, 122, 72, 45, 123, 72, 45, 125, 74, 47, 126, 75, 48, 126, 75, 48, 127, 75, 51, 113, 63, 40,  94, 46, 24,  79, 32, 12,  71, 25,  9,  64, 21,  5,  59, 15,  2,  53, 11,  0,  67, 27, 17,  72, 34, 23,  80, 42, 31,  87, 49, 36,  90, 54, 40,  91, 55, 39,  92, 57, 38,  92, 57, 37, 105, 69, 47, 116, 78, 57, 122, 81, 59, 117, 72, 49, 109, 63, 39, 111, 63, 40, 122, 72, 49, 130, 80, 57, 143, 87, 62, 145, 89, 66, 145, 91, 67, 141, 91, 68, 135, 88, 68, 131, 88, 71, 128, 91, 75, 124, 95, 81, 157,133,123, 192,175,167, 212,203,198, 202,201,197, 190,196,196, 182,194,194, 179,194,197, 182,200,202, 179,198,194, 185,204,200, 191,210,206, 191,210,206, 183,202,198, 172,193,188, 165,186,181, 162,183,178, 169,192,186, 169,192,186, 168,191,185, 167,190,184, 167,192,186, 171,196,190, 172,197,191, 170,195,189,
 57, 61, 64,  56, 59, 64,  74, 77, 82, 101,104,109,  70, 73, 78,  71, 74, 79, 111,114,121,  73, 76, 83,  61, 64, 71,  72, 75, 84,  65, 68, 77,  84, 87, 96, 128,130,142, 178,180,192, 215,217,229, 208,210,222, 230,230,238, 230,233,242, 223,226,235, 220,224,235, 221,228,238, 213,220,230, 205,212,222, 210,217,225, 203,206,211, 193,193,195, 184,180,177, 191,182,175, 164,151,142, 126,108, 94, 119,100, 83, 111, 90, 71, 130, 84, 58, 126, 80, 54, 123, 76, 50, 120, 73, 45, 123, 73, 46, 124, 74, 47, 126, 75, 48, 125, 75, 48, 132, 82, 57, 122, 74, 51, 110, 62, 40,  96, 51, 30,  83, 40, 23,  71, 29, 13,  60, 18,  4,  50, 11,  0,  45,  2,  0,  50,  7,  0,  57, 14,  5,  57, 17,  7,  53, 13,  1,  48,  9,  0,  43,  4,  0,  41,  2,  0,  60, 19,  1,  69, 26,  7,  80, 35, 14,  87, 41, 18,  99, 49, 26, 112, 60, 38, 122, 67, 46, 124, 70, 46, 129, 75, 51, 132, 78, 54, 132, 80, 58, 130, 82, 62, 126, 83, 64, 126, 87, 70, 128, 95, 80, 128,101, 90, 154,134,125, 169,156,150, 171,166,162, 178,178,178, 191,196,199, 181,191,193, 170,181,185, 179,192,198, 172,188,187, 179,195,194, 183,199,198, 178,194,193, 169,185,184, 167,186,184, 179,198,196, 191,210,208, 183,203,201, 174,194,192, 175,195,193, 186,206,204, 189,211,208, 182,204,201, 178,200,197, 182,204,201,
 49, 52, 57,  44, 47, 52,  63, 66, 71, 102,105,110,  70, 73, 78,  66, 69, 74, 108,111,118,  54, 57, 64,  52, 55, 62,  52, 55, 62,  56, 59, 68,  85, 88, 97, 149,152,161, 211,214,223, 232,232,242, 219,219,229, 213,212,218, 212,213,218, 213,216,223, 218,221,230, 218,222,231, 212,219,229, 203,210,218, 198,202,211, 198,201,206, 189,190,192, 190,186,185, 191,184,178, 175,162,153, 126,110, 97, 130,113, 97,  92, 73, 56, 117, 75, 51, 116, 74, 49, 116, 72, 47, 113, 67, 43, 114, 68, 42, 120, 73, 47, 125, 78, 52, 126, 79, 53, 130, 82, 59, 135, 89, 65, 139, 92, 72, 133, 88, 69, 117, 74, 57,  99, 57, 41,  86, 47, 32,  81, 42, 27,  83, 34, 29,  77, 30, 24,  75, 28, 22,  74, 27, 19,  64, 20,  9,  55, 11,  0,  54, 10,  0,  60, 17,  1,  62, 16,  0,  74, 27,  9,  88, 40, 20,  98, 47, 26, 105, 53, 32, 113, 58, 37, 120, 63, 43, 122, 65, 45, 124, 72, 50, 136, 85, 64, 134, 86, 66, 126, 81, 62, 123, 84, 67, 124, 91, 76, 131,103, 91, 144,124,115, 155,140,133, 147,137,135, 155,151,150, 179,179,181, 192,196,199, 186,193,199, 175,184,189, 171,182,188, 163,177,178, 172,186,187, 191,205,206, 205,219,220, 194,210,210, 173,189,189, 165,181,181, 171,187,187, 162,180,180, 151,169,169, 161,179,179, 176,196,195, 173,193,192, 168,188,187, 175,195,194, 181,201,200,
 54, 57, 62,  41, 44, 49,  53, 56, 61,  87, 90, 95,  56, 59, 64,  57, 58, 63, 100,101,106,  54, 55, 60,  50, 51, 56,  32, 31, 37,  51, 50, 56, 128,127,133, 208,207,213, 243,242,248, 243,242,248, 238,237,243, 233,228,232, 226,224,227, 217,216,221, 209,210,215, 203,206,213, 201,206,212, 202,207,213, 204,209,215, 196,199,204, 191,192,194, 185,184,182, 180,173,167, 166,156,147, 136,122,111, 120,104, 89,  88, 71, 55, 105, 67, 44, 107, 69, 46, 110, 69, 47, 109, 69, 44, 110, 68, 44, 117, 73, 48, 122, 78, 53, 127, 81, 57, 129, 85, 60, 135, 90, 67, 141, 99, 77, 145,102, 83, 141,100, 82, 128, 89, 72, 115, 78, 62, 106, 69, 53, 117, 64, 60, 113, 60, 56, 108, 58, 51, 107, 57, 50, 102, 54, 44,  98, 50, 40, 101, 55, 42, 109, 63, 48, 112, 65, 49, 120, 73, 55, 123, 74, 57, 120, 69, 50, 126, 71, 51, 135, 80, 60, 136, 79, 60, 129, 71, 51, 133, 86, 66, 116, 71, 50, 114, 71, 52, 134, 95, 78, 133,100, 85, 108, 80, 68, 121, 99, 88, 167,152,145, 171,160,156, 161,156,153, 164,162,163, 180,181,183, 191,194,199, 189,194,200, 184,191,197, 187,194,200, 195,206,208, 198,209,211, 202,213,215, 203,214,216, 191,205,206, 176,190,191, 168,182,183, 169,183,184, 177,193,193, 167,183,183, 171,187,187, 178,196,196, 171,189,189, 164,182,182, 163,181,181, 159,177,177,
 42, 45, 50,  24, 27, 32,  34, 37, 42,  70, 71, 75,  44, 45, 49,  42, 43, 47,  79, 78, 83,  42, 41, 46,  26, 24, 27,  46, 44, 47, 113,108,112, 201,196,200, 248,242,246, 244,238,242, 237,231,235, 246,240,244, 249,241,239, 242,237,234, 233,229,228, 220,218,219, 209,208,213, 203,204,208, 200,203,208, 201,204,209, 193,197,200, 194,195,197, 187,186,184, 177,172,166, 165,156,147, 151,139,127, 101, 87, 74,  83, 67, 52,  99, 66, 47,  98, 65, 46,  99, 64, 44,  98, 63, 41,  99, 63, 41, 102, 64, 41, 108, 67, 45, 113, 71, 47, 121, 79, 55, 126, 84, 62, 134, 93, 73, 145,104, 84, 149,111, 92, 143,106, 88, 131, 94, 78, 120, 83, 67, 113, 58, 53, 110, 55, 50, 109, 56, 50, 110, 60, 53, 113, 63, 54, 117, 69, 59, 125, 79, 66, 134, 88, 73, 144, 98, 83, 148,101, 85, 139, 92, 74, 127, 78, 61, 129, 78, 59, 139, 86, 68, 137, 81, 64, 124, 68, 51, 119, 78, 60, 131, 93, 74, 130, 93, 75, 115, 83, 68, 106, 80, 67, 111, 91, 80, 143,129,120, 182,173,168, 192,187,184, 183,182,180, 184,184,186, 192,193,197, 195,198,203, 191,194,199, 190,193,198, 194,197,204, 199,208,213, 199,208,213, 196,205,210, 190,201,205, 186,197,201, 182,193,197, 173,184,188, 161,175,178, 175,189,192, 168,182,185, 173,187,190, 178,193,196, 176,191,194, 177,192,195, 175,190,193, 164,179,182,
 49, 53, 56,  29, 33, 36,  47, 48, 52,  85, 86, 90,  67, 66, 71,  60, 60, 62,  85, 83, 86,  60, 56, 57,  52, 46, 48, 116,107,108, 190,181,182, 228,218,217, 230,218,218, 221,210,208, 225,211,210, 231,217,216, 239,226,220, 239,228,222, 240,231,226, 239,231,229, 229,225,224, 214,214,214, 198,199,201, 188,189,193, 188,189,191, 188,188,188, 185,184,182, 180,177,172, 166,159,151, 153,143,133,  83, 71, 59,  83, 71, 57, 109, 83, 68, 100, 72, 58,  90, 63, 46,  89, 60, 42,  93, 60, 41,  95, 60, 40,  96, 60, 38,  97, 59, 38, 105, 67, 46, 109, 71, 50, 117, 79, 58, 129, 91, 72, 140,102, 83, 143,106, 88, 140,103, 85, 135, 99, 83, 138, 83, 76, 136, 83, 75, 136, 83, 75, 137, 87, 78, 140, 92, 82, 145, 99, 86, 150,106, 93, 155,112, 96, 147,105, 89, 143,100, 84, 134, 91, 74, 128, 82, 66, 125, 79, 63, 126, 79, 61, 124, 77, 59, 122, 73, 56, 104, 68, 52, 128, 95, 78, 118, 89, 75,  93, 67, 54, 107, 87, 76, 153,139,130, 183,174,167, 190,187,182, 196,196,194, 193,195,194, 195,196,198, 196,200,203, 194,195,199, 184,185,189, 179,180,185, 181,180,186, 174,181,187, 179,186,192, 179,188,193, 180,189,194, 189,198,203, 199,208,213, 187,198,202, 168,179,183, 163,174,178, 160,171,175, 164,178,181, 170,184,187, 174,188,191, 186,200,203, 189,203,206, 176,191,194,
 94, 98,101,  69, 70, 74,  85, 86, 90, 121,121,123, 107,105,108, 101, 97, 98, 121,115,115, 113,105,103, 134,124,123, 174,163,161, 206,192,189, 207,192,187, 207,189,185, 219,200,194, 223,204,198, 216,197,191, 217,199,189, 217,200,190, 220,205,198, 224,213,207, 225,217,214, 216,212,209, 201,199,200, 188,188,188, 185,187,186, 179,179,179, 175,174,172, 178,175,170, 162,158,149, 148,139,130,  92, 82, 72, 111,101, 89, 121,101, 90, 100, 81, 67,  84, 62, 49,  85, 62, 48,  95, 68, 51,  99, 70, 52,  99, 66, 47,  99, 64, 44,  94, 57, 38,  98, 62, 40, 104, 67, 48, 113, 76, 57, 123, 86, 67, 135, 98, 80, 144,107, 89, 149,114, 95, 150,100, 89, 151,101, 90, 149,101, 89, 146,100, 87, 143, 99, 86, 141, 99, 85, 137, 98, 83, 134, 97, 81, 136,101, 82, 125, 90, 71, 120, 85, 66, 121, 86, 67, 114, 77, 59, 102, 65, 47, 105, 66, 49, 116, 77, 60,  97, 68, 54,  81, 53, 39,  79, 55, 43, 116, 98, 86, 167,154,145, 186,179,171, 188,185,180, 194,196,193, 187,191,190, 185,191,191, 185,190,193, 185,189,192, 180,181,185, 173,172,177, 171,169,172, 173,171,174, 167,174,182, 174,181,189, 177,184,192, 181,188,196, 199,206,214, 216,225,232, 210,219,226, 189,198,205, 164,173,180, 160,171,177, 163,174,180, 165,176,182, 163,176,182, 175,188,194, 184,197,203, 177,190,196,
124,125,129,  86, 87, 91,  93, 94, 96, 119,119,121, 107,105,106, 107,101,101, 136,128,126, 150,140,138, 178,164,161, 191,176,171, 205,188,181, 213,193,186, 218,195,187, 221,197,187, 217,193,183, 211,187,175, 204,182,168, 197,178,164, 192,174,162, 191,177,168, 195,184,178, 201,193,190, 202,198,195, 201,200,198, 192,192,192, 179,179,177, 170,169,165, 170,167,162, 161,156,150, 154,147,137, 136,128,117, 152,144,133, 120,106, 97,  96, 82, 73,  79, 62, 52,  85, 65, 54,  99, 77, 63, 106, 80, 65, 106, 77, 61, 107, 76, 56,  95, 62, 43,  97, 62, 42,  98, 61, 42,  99, 62, 43, 104, 67, 48, 113, 76, 58, 123, 86, 68, 129, 94, 75, 143, 97, 82, 146,100, 85, 145,102, 86, 142,100, 84, 139,102, 86, 136,100, 84, 127, 94, 77, 117, 88, 70, 106, 77, 59,  95, 68, 49,  91, 64, 45,  92, 65, 46,  85, 58, 39,  75, 46, 28,  80, 51, 33,  94, 65, 47,  80, 56, 44,  82, 60, 47, 108, 90, 78, 162,149,140, 195,188,180, 181,178,173, 168,170,167, 183,189,187, 184,193,192, 181,189,191, 179,184,187, 175,179,182, 175,176,178, 179,177,180, 186,182,183, 192,186,188, 188,192,201, 190,194,203, 188,192,201, 187,194,202, 201,208,216, 218,225,233, 216,223,231, 200,209,216, 168,177,184, 165,174,181, 169,180,186, 169,180,186, 162,173,179, 169,180,186, 184,195,201, 189,200,206,
119,120,124,  75, 76, 80,  79, 79, 81,  98, 96, 97,  90, 86, 85,  95, 90, 87, 133,123,121, 169,158,154, 186,171,164, 201,182,175, 219,199,190, 231,207,197, 227,200,189, 213,185,173, 203,175,161, 203,174,160, 193,167,150, 187,164,148, 179,157,143, 169,151,139, 164,151,142, 170,161,154, 181,176,172, 188,187,183, 187,187,185, 179,179,177, 168,167,163, 157,156,151, 159,156,149, 159,155,146, 176,169,159, 162,154,143, 125,114,108, 105, 94, 88,  93, 80, 72,  99, 82, 72, 107, 87, 76, 108, 85, 71, 108, 82, 67, 111, 82, 64, 108, 77, 57, 105, 72, 53, 103, 68, 48, 103, 68, 48, 108, 71, 52, 111, 74, 55, 112, 75, 57, 110, 75, 56, 109, 67, 51, 113, 71, 55, 113, 74, 57, 111, 74, 56, 110, 77, 58, 107, 79, 58,  99, 72, 51,  87, 65, 44,  82, 61, 40,  82, 61, 40,  75, 57, 35,  69, 51, 29,  71, 53, 33,  82, 64, 44,  94, 73, 54,  98, 77, 58,  96, 76, 65, 135,117,107, 163,149,140, 170,161,152, 172,169,162, 168,170,165, 167,173,171, 175,185,184, 184,194,195, 182,192,193, 179,187,189, 180,184,185, 186,186,188, 194,192,193, 203,197,199, 209,200,201, 201,205,214, 202,206,215, 200,204,213, 200,204,213, 206,210,219, 209,216,224, 204,211,219, 194,201,209, 160,169,176, 159,168,175, 172,181,188, 177,186,193, 163,174,180, 163,174,180, 185,196,202, 202,213,219,
113,114,118,  69, 70, 72,  76, 76, 78,  96, 94, 95,  92, 88, 87, 102, 94, 92, 142,133,128, 190,177,171, 212,195,188, 221,201,192, 223,201,190, 218,192,179, 211,183,169, 207,178,164, 200,168,153, 189,157,142, 175,148,129, 178,152,135, 175,152,136, 162,143,129, 146,132,121, 141,130,124, 149,142,136, 157,153,150, 172,171,169, 173,173,171, 162,161,157, 143,142,137, 152,149,142, 158,154,145, 189,182,172, 139,132,122, 142,133,128, 127,118,113, 117,106,100, 120,106, 97, 119,101, 91, 112, 90, 77, 110, 84, 69, 114, 87, 70, 120, 89, 71, 116, 83, 64, 116, 81, 61, 123, 88, 68, 134, 99, 79, 139,102, 83, 134, 97, 78, 126, 91, 72, 132, 94, 75, 135, 97, 78, 133, 96, 77, 124, 91, 72, 121, 90, 70, 117, 90, 69, 105, 83, 60,  93, 72, 51,  86, 68, 46,  96, 80, 57,  89, 74, 53,  76, 61, 40,  90, 75, 54, 125,110, 89, 141,126,105, 132,117, 96, 149,131,121, 165,148,138, 161,148,139, 150,143,135, 159,158,153, 176,181,177, 183,192,189, 187,197,196, 177,189,189, 178,190,190, 181,189,191, 185,191,191, 195,195,197, 203,199,200, 205,199,199, 205,196,197, 202,206,215, 206,210,219, 211,215,224, 214,218,227, 214,218,227, 206,213,221, 194,201,209, 184,191,199, 151,158,166, 151,160,167, 169,178,185, 177,186,193, 159,168,175, 151,162,168, 174,185,191, 198,209,215,
116,118,113,  93, 94, 88,  79, 78, 73,  88, 85, 80, 106, 99, 93, 130,119,113, 175,160,153, 219,200,193, 221,196,189, 222,193,185, 222,189,182, 222,185,177, 219,179,171, 214,171,164, 207,163,154, 203,156,148, 178,145,126, 168,135,118, 160,129,111, 160,129,111, 155,126,110, 145,117,103, 136,109, 98, 132,110, 99, 160,140,133, 184,166,162, 167,153,150, 139,129,128, 159,153,155, 181,176,180, 160,158,163, 134,131,138, 145,137,134, 156,148,145, 150,142,139, 132,125,119, 132,125,119, 140,131,124, 118,109,100,  81, 73, 62, 106, 98, 85, 112,102, 90, 114,105, 90, 113,104, 87, 119,107, 91, 126,115, 97, 127,116, 98, 123,112, 94, 134,115,109, 136,119,112, 137,119,115, 129,114,109, 116,103, 97, 107, 93, 90, 103, 94, 89, 106, 98, 95, 111,106,102, 101, 97, 94,  95, 94, 90, 104,104,102, 117,119,116, 127,132,128, 139,143,142, 150,154,153, 169,153,153, 165,149,149, 147,133,132, 132,122,120, 147,139,136, 173,170,165, 182,181,176, 173,174,168, 179,180,174, 182,183,177, 188,187,182, 195,192,187, 200,195,191, 205,197,194, 208,198,196, 209,199,197, 208,194,194, 210,196,196, 212,198,198, 211,197,196, 210,196,195, 211,199,199, 218,206,206, 223,213,214, 218,212,214, 199,197,202, 187,188,193, 182,186,195, 169,177,188, 158,168,180, 168,180,194, 190,203,219,
121,122,116,  97, 96, 91,  77, 74, 69,  90, 85, 79, 136,127,120, 183,170,164, 205,188,181, 207,187,180, 214,189,182, 215,186,178, 215,181,172, 213,176,167, 210,170,162, 205,162,153, 198,154,145, 194,147,139, 178,143,123, 167,132,112, 159,124,105, 156,123,104, 152,121,103, 142,113, 97, 134,106, 94, 129,105, 93, 132,109,101, 151,132,126, 148,133,130, 140,129,127, 152,143,144, 157,151,153, 152,147,151, 156,151,157, 163,155,153, 170,162,160, 163,153,151, 148,138,136, 151,142,137, 161,152,147, 146,137,130, 118,108, 99, 101, 91, 81, 110,100, 88, 117,105, 93, 113,101, 87, 111, 99, 83, 117,105, 89, 124,112, 96, 127,116, 98, 129,110,104, 120,103, 96, 117,100, 93, 124,107,100, 131,116,111, 137,124,118, 145,134,130, 154,145,140, 145,137,134, 145,140,136, 147,143,140, 146,145,141, 139,140,135, 136,136,134, 143,145,142, 156,158,155, 175,159,159, 168,154,153, 143,132,130, 129,119,117, 145,137,134, 166,161,157, 174,171,166, 176,175,170, 176,175,170, 182,182,174, 191,188,181, 196,191,185, 194,187,181, 183,174,169, 171,160,156, 164,150,147, 164,148,148, 168,152,152, 175,159,159, 179,163,163, 178,162,162, 170,156,155, 158,146,146, 149,139,138, 185,176,179, 219,214,218, 228,227,233, 190,193,202, 158,165,175, 166,176,188, 189,201,215, 201,215,228,
110,107,100,  73, 68, 62,  72, 65, 59, 128,119,112, 185,174,168, 204,189,182, 204,185,178, 210,187,179, 207,180,171, 207,177,167, 205,171,161, 204,166,157, 199,159,149, 193,151,139, 186,142,131, 180,136,125, 174,133,111, 164,123,101, 152,114, 91, 149,113, 91, 146,111, 91, 138,105, 86, 128, 99, 83, 123, 95, 83, 114, 90, 78, 116, 96, 87, 122,105, 98, 137,123,120, 147,135,135, 138,129,130, 142,136,138, 169,163,165, 177,167,168, 178,168,169, 170,160,161, 161,149,149, 166,154,154, 178,167,165, 172,161,157, 157,144,138, 119,106,100, 117,104, 96, 112, 98, 89, 104, 90, 81, 105, 91, 80, 115,101, 90, 126,112, 99, 131,117,104, 127,108,101, 127,110,102, 139,122,114, 160,143,136, 167,152,145, 163,150,142, 168,155,149, 177,166,160, 172,163,158, 162,155,149, 150,145,141, 142,137,133, 139,136,131, 147,143,140, 164,163,159, 182,181,177, 183,169,168, 172,158,157, 139,128,126, 127,117,115, 150,143,137, 162,157,151, 166,161,155, 180,177,170, 186,182,173, 181,177,168, 173,166,158, 163,154,147, 156,143,135, 149,134,127, 147,130,123, 145,128,121, 160,141,137, 165,146,142, 176,157,153, 188,169,165, 191,173,169, 184,166,164, 166,151,148, 150,139,137, 109, 99,100, 118,112,114, 144,143,148, 167,170,177, 163,170,180, 154,162,173, 170,182,194, 202,214,228,
 74, 65, 58,  72, 63, 56, 109, 98, 92, 175,162,154, 209,194,187, 202,183,176, 196,176,167, 211,187,177, 203,175,164, 203,171,160, 199,165,153, 196,158,145, 191,151,139, 185,143,129, 177,133,120, 172,128,115, 167,123, 96, 157,113, 86, 145,103, 78, 140,100, 75, 138,100, 77, 134, 97, 78, 124, 91, 72, 116, 87, 71, 110, 84, 71,  95, 73, 62,  97, 78, 71, 123,105,101, 134,120,117, 127,115,115, 134,124,123, 158,149,150, 174,161,168, 171,159,163, 166,154,158, 165,153,157, 173,161,163, 184,169,172, 183,169,169, 177,163,162, 159,144,141, 138,123,120, 111, 96, 91,  96, 81, 74, 100, 83, 76, 109, 92, 85, 114, 97, 89, 113, 96, 88, 116, 99, 91, 128,111,103, 152,135,127, 169,155,146, 162,148,139, 146,133,125, 152,139,131, 171,160,154, 177,166,160, 153,144,137, 129,120,115, 126,119,113, 145,138,132, 170,162,159, 187,179,176, 193,188,184, 183,172,170, 164,153,151, 128,119,114, 125,116,111, 157,150,144, 167,160,152, 164,157,149, 179,172,162, 174,165,156, 161,151,141, 142,129,120, 128,111,101, 122,104, 94, 129,109,100, 142,119,111, 152,127,120, 164,141,135, 169,146,140, 178,155,149, 189,166,160, 194,174,167, 192,173,167, 185,167,163, 177,162,159, 145,134,132,  80, 71, 72,  77, 72, 76, 154,155,160, 201,205,214, 177,185,196, 165,175,187, 188,200,214,
 67, 52, 45, 126,111,104, 181,164,156, 197,178,171, 201,181,172, 211,189,178, 210,186,176, 201,173,162, 201,171,160, 199,167,154, 196,160,146, 191,154,138, 186,147,132, 180,138,122, 172,130,114, 168,125,108, 161,114, 84, 152,105, 77, 142, 97, 68, 136, 92, 67, 135, 95, 70, 132, 94, 73, 122, 87, 68, 111, 79, 64,  95, 67, 55,  88, 64, 54,  95, 75, 68, 109, 92, 85, 110, 95, 92, 109, 98, 96, 125,113,113, 142,132,131, 153,140,149, 149,136,145, 151,138,147, 162,149,156, 171,158,165, 176,161,166, 177,162,167, 179,164,167, 186,172,172, 168,152,153, 143,127,127, 124,108,108, 116, 98, 96, 110, 92, 90, 106, 88, 84, 103, 85, 81, 100, 87, 78, 102, 89, 80, 110, 97, 88, 119,106, 98, 118,105, 97, 121,108,100, 145,132,124, 173,162,156, 170,159,153, 159,148,142, 150,139,135, 158,147,143, 175,166,161, 186,177,172, 181,171,169, 169,159,157, 168,159,154, 139,130,125, 107, 98, 93, 116,107,100, 153,144,137, 165,156,147, 157,149,138, 162,152,142, 131,119,107, 129,113,100, 124,104, 93, 122,100, 87, 126,100, 87, 135,107, 95, 146,116,105, 154,122,111, 161,133,122, 166,138,127, 171,144,133, 175,148,139, 174,150,140, 174,149,142, 173,153,146, 174,155,149, 155,140,137,  79, 69, 68,  36, 30, 32,  80, 79, 84, 155,158,165, 196,203,213, 208,216,227, 212,222,234,
126,106, 99, 170,150,143, 204,184,175, 206,183,175, 201,177,167, 206,179,168, 207,179,167, 199,170,156, 199,167,152, 195,162,147, 191,155,139, 186,149,131, 180,142,123, 175,134,116, 168,127,107, 163,122,102, 158,109, 79, 149,102, 72, 139, 94, 65, 132, 88, 63, 131, 91, 66, 127, 91, 69, 114, 81, 62,  99, 70, 54,  79, 52, 41,  93, 70, 62, 117, 98, 91, 116,101, 96,  97, 83, 80, 100, 89, 87, 126,114,114, 141,131,130, 124,112,122, 118,106,116, 127,115,125, 147,136,144, 156,145,153, 151,138,147, 150,137,144, 158,146,150, 174,162,166, 179,164,167, 181,166,169, 176,162,162, 161,145,146, 144,128,129, 138,122,122, 140,124,124, 111,102, 95, 100, 91, 84,  92, 83, 76, 100, 91, 84, 118,109,102, 138,129,122, 157,148,143, 172,161,157, 158,147,143, 168,157,153, 177,166,164, 178,167,165, 174,163,161, 168,157,155, 160,149,147, 153,142,140, 141,134,128, 105, 98, 90,  81, 74, 66,  97, 88, 79, 127,118,109, 145,135,125, 142,130,118, 132,116,103, 107, 89, 75, 111, 89, 75, 116, 90, 75, 122, 93, 77, 132, 99, 84, 144,108, 92, 153,116,100, 160,121,106, 158,126,113, 165,133,120, 174,142,129, 177,148,134, 176,146,135, 174,146,134, 173,149,139, 172,152,143, 181,164,157, 124,110,107,  52, 44, 42,  17, 12, 16,  37, 38, 43,  89, 93,102, 136,143,153, 160,168,179,
185,160,153, 185,161,151, 196,169,160, 209,182,171, 209,181,170, 197,167,156, 194,165,151, 201,169,154, 192,159,142, 190,155,136, 185,148,130, 179,141,122, 173,135,114, 169,128,108, 162,121, 99, 157,116, 94, 152,105, 77, 144, 99, 70, 133, 89, 62, 123, 83, 58, 120, 84, 62, 116, 83, 64,  99, 70, 54,  81, 54, 43,  78, 55, 47, 100, 81, 75, 132,117,112, 134,120,117, 105, 93, 93, 105, 95, 94, 129,119,120, 138,129,130, 111,104,112, 101, 94,102, 110,103,111, 133,126,134, 136,129,137, 120,110,118, 116,106,114, 127,118,123, 143,132,138, 152,141,145, 168,157,161, 182,171,175, 182,170,172, 170,158,160, 160,148,150, 158,146,148, 130,127,122, 124,121,116, 118,115,110, 124,119,115, 141,136,132, 157,152,148, 156,151,148, 149,141,139, 146,138,136, 165,155,154, 176,166,165, 164,154,153, 145,135,134, 139,127,127, 143,131,133, 149,137,139, 118,111,103,  76, 69, 59,  65, 56, 47,  78, 70, 59,  92, 82, 72, 118,104, 93, 124,108, 95,  99, 80, 65, 107, 84, 68, 110, 83, 66, 115, 84, 66, 122, 87, 68, 133, 95, 76, 146,105, 87, 158,115, 96, 167,122,103, 155,119,103, 160,124,108, 168,132,116, 174,141,124, 177,144,129, 178,146,133, 174,146,134, 171,147,135, 174,154,145, 151,136,129, 103, 92, 90,  43, 37, 37,  11,  9, 12,  30, 31, 36,  80, 84, 93, 121,125,134,
197,168,160, 202,174,163, 203,173,163, 200,170,160, 203,173,162, 210,178,165, 205,172,157, 192,159,142, 188,153,134, 185,148,129, 179,142,123, 173,135,114, 168,130,107, 163,122,100, 157,117, 92, 153,113, 88, 143,101, 76, 137, 95, 71, 123, 85, 62, 114, 77, 58, 109, 76, 59, 102, 74, 60,  83, 59, 47,  61, 41, 34,  85, 67, 63,  96, 82, 79, 129,117,117, 138,128,129, 115,106,107, 112,103,106, 124,118,120, 121,115,117, 116,113,120, 103,100,107, 109,106,113, 129,126,133, 126,124,129, 102, 97,103,  94, 89, 95, 107,102,106, 119,113,117, 113,107,111, 120,114,116, 144,138,140, 164,155,158, 160,151,152, 141,132,133, 126,117,118, 132,134,133, 135,137,136, 133,133,133, 127,127,127, 131,131,131, 141,139,140, 137,135,136, 127,123,124, 144,138,140, 162,156,158, 173,164,167, 159,150,153, 140,129,133, 131,120,124, 134,123,127, 138,127,131, 105, 98, 88,  63, 57, 45,  59, 51, 40,  69, 59, 47,  69, 55, 42,  97, 81, 66, 113, 94, 79,  82, 59, 43, 103, 74, 58, 111, 78, 59, 122, 85, 66, 134, 93, 73, 144,102, 80, 153,106, 86, 158,110, 88, 159,111, 89, 168,130,111, 167,129,110, 166,129,110, 171,134,116, 176,141,122, 177,144,127, 174,142,127, 168,140,128, 158,134,124, 179,160,153, 157,144,138,  81, 71, 70,  18, 14, 15,   9,  8, 13,  21, 22, 27,  21, 24, 31,
202,172,162, 208,178,168, 214,182,171, 213,181,170, 212,180,167, 211,178,163, 206,173,158, 201,165,149, 193,156,138, 183,146,127, 172,134,113, 164,126,103, 162,121, 99, 157,117, 92, 149,109, 84, 142,102, 76, 136,100, 78, 128, 91, 72, 116, 83, 64, 105, 73, 58,  87, 61, 48,  71, 49, 38,  68, 49, 43,  72, 57, 54,  87, 75, 75, 103, 94, 95, 115,109,111, 112,106,110,  98, 92, 96,  96, 91, 95, 112,107,111, 131,126,130, 119,120,122, 113,114,116, 112,113,115, 117,117,119, 118,118,120, 110,110,112,  99, 99,101,  93, 91, 92, 112,110,111,  93, 91, 92,  84, 80, 81,  94, 90, 89, 114,110,109, 122,118,117, 114,110,109, 105,101,100, 136,140,143, 124,128,131, 114,118,121, 118,122,125, 132,133,137, 137,138,140, 132,132,134, 123,121,124, 143,141,144, 154,149,153, 150,144,148, 130,124,128, 117,108,113, 117,108,113, 121,112,117, 120,111,116,  89, 81, 68,  60, 52, 39,  41, 31, 19,  52, 38, 25,  64, 48, 33,  68, 49, 34,  79, 56, 40,  96, 67, 51, 111, 78, 59, 119, 82, 63, 128, 87, 67, 136, 91, 70, 142, 96, 73, 149,101, 78, 160,110, 87, 167,117, 94, 166,125,105, 168,130,109, 173,135,116, 177,139,120, 177,140,121, 177,142,123, 176,143,126, 174,145,131, 162,136,123, 164,144,133, 168,151,144, 137,126,122,  57, 49, 47,   9,  5,  6,  18, 16, 19,   4,  3,  8,
204,171,162, 211,178,169, 217,185,174, 217,185,174, 217,183,171, 213,180,165, 206,170,154, 197,162,143, 195,158,139, 183,146,127, 169,131,110, 157,119, 96, 153,113, 88, 150,110, 85, 146,106, 80, 143,103, 77, 128, 95, 78, 126, 95, 77, 119, 90, 76, 103, 76, 65,  75, 55, 46,  58, 41, 34,  60, 46, 43,  70, 60, 59,  69, 60, 63,  88, 82, 86, 106,101,105, 105,100,104,  91, 86, 90,  86, 81, 85, 101, 95, 99, 117,111,113, 126,128,125, 118,120,117, 115,117,114, 124,126,123, 133,133,131, 130,130,128, 120,120,118, 113,112,108,  96, 95, 91,  86, 85, 81,  78, 77, 73,  81, 77, 74,  91, 87, 84, 105,101, 98, 124,120,117, 139,136,131, 137,141,144, 129,133,136, 124,128,131, 128,132,135, 140,141,145, 145,144,149, 139,138,143, 132,130,135, 142,140,143, 153,148,152, 153,147,151, 138,132,136, 128,119,124, 126,117,122, 124,115,120, 120,109,115,  87, 75, 61,  59, 47, 33,  41, 28, 12,  47, 29, 15,  57, 38, 23,  64, 41, 25,  78, 51, 34,  95, 64, 46, 106, 71, 52, 115, 77, 56, 129, 87, 65, 140, 95, 72, 148,102, 79, 157,109, 86, 167,117, 94, 173,123, 98, 166,128,107, 170,132,111, 175,137,118, 178,140,121, 176,139,120, 175,138,120, 171,138,119, 170,138,123, 171,143,129, 157,133,121, 150,132,122, 156,141,134, 122,111,107,  77, 69, 67,  52, 46, 46,  16, 12, 13,
208,178,168, 213,183,173, 218,186,175, 215,183,172, 212,180,167, 210,177,162, 205,169,153, 197,162,143, 193,156,137, 185,147,128, 173,135,114, 163,122,100, 154,114, 89, 148,108, 83, 145,103, 78, 142,100, 75, 123, 94, 78, 116, 88, 74, 106, 80, 67,  89, 67, 56,  71, 52, 46,  60, 45, 42,  62, 50, 50,  70, 61, 62,  64, 58, 62,  85, 80, 84, 106,101,105, 106,100,104,  89, 83, 85,  81, 72, 73,  89, 79, 80, 102, 92, 91, 117,117,109, 108,108,100, 105,105, 97, 117,117,109, 132,132,124, 137,134,127, 130,127,120, 124,121,114, 102, 97, 91,  98, 93, 87,  97, 92, 86, 100, 96, 87, 110,103, 95, 124,117,109, 146,139,131, 165,158,150, 154,154,156, 152,152,154, 152,152,154, 158,156,159, 165,163,166, 169,165,166, 164,160,161, 159,153,155, 156,150,152, 161,152,155, 154,144,145, 137,127,128, 124,112,114, 118,106,108, 111, 99,101, 102, 90, 92,  80, 64, 49,  60, 44, 28,  47, 30, 14,  52, 31, 14,  57, 34, 18,  59, 32, 15,  67, 36, 18,  80, 45, 26, 106, 68, 49, 117, 76, 56, 130, 88, 66, 142, 97, 74, 149,103, 80, 154,108, 84, 160,114, 90, 164,118, 94, 169,131,112, 174,136,117, 181,143,124, 184,147,128, 185,148,129, 182,147,128, 181,146,127, 178,147,129, 170,141,127, 161,135,122, 148,128,117, 164,147,139, 154,141,135, 119,108,104, 101, 93, 90,  85, 77, 75,
202,174,163, 204,174,164, 201,171,160, 193,163,152, 191,159,146, 190,158,143, 189,156,141, 186,150,134, 177,140,122, 174,137,118, 171,133,112, 167,126,104, 159,119, 94, 150,108, 84, 140, 98, 74, 133, 91, 66, 125, 96, 82, 108, 80, 66,  90, 63, 52,  81, 58, 50,  80, 61, 55,  79, 64, 61,  73, 61, 61,  66, 57, 58,  86, 77, 80, 106, 97,100, 125,116,117, 123,113,112, 105, 94, 92,  93, 79, 76,  98, 83, 78, 110, 92, 88,  95, 89, 75,  89, 83, 69,  91, 83, 70, 103, 95, 82, 116,108, 97, 121,113,102, 120,112,101, 120,110,100, 125,115,105, 120,110,100, 126,113,104, 142,129,120, 157,144,135, 161,148,139, 155,142,133, 150,137,128, 157,147,146, 160,150,149, 165,155,154, 170,160,159, 174,164,162, 174,163,161, 171,160,158, 170,156,155, 160,146,143, 155,140,137, 139,124,121, 119,104, 99, 109, 91, 87, 105, 87, 83, 100, 82, 78,  94, 76, 72,  84, 65, 48,  75, 56, 39,  72, 51, 34,  77, 51, 34,  77, 48, 32,  69, 38, 20,  64, 29, 10,  64, 27,  9, 109, 68, 50, 118, 77, 57, 131, 88, 69, 140, 98, 76, 147,105, 81, 152,110, 86, 158,116, 92, 162,120, 96, 166,130,114, 171,135,119, 178,143,124, 183,148,129, 183,148,129, 180,145,126, 176,143,126, 173,142,124, 165,136,120, 172,146,133, 158,134,122, 158,138,129, 153,136,128, 127,114,108, 115,104,100, 106, 95, 91,
173,146,135, 174,147,136, 173,145,134, 165,137,125, 161,131,120, 161,129,116, 156,124,109, 152,119,102, 155,120,101, 155,118, 99, 154,116, 95, 154,113, 93, 151,109, 87, 144,102, 78, 136, 91, 68, 129, 84, 61, 121, 89, 74, 112, 83, 67, 104, 76, 64, 100, 76, 66, 100, 80, 73,  94, 77, 70,  78, 64, 61,  63, 52, 50,  75, 64, 62,  92, 81, 79, 110, 95, 92, 111, 94, 87, 100, 80, 73,  94, 72, 61, 101, 77, 65, 113, 87, 74,  95, 79, 63,  94, 78, 62,  99, 83, 67, 108, 91, 75, 114, 97, 81, 116, 99, 83, 120,103, 87, 126,107, 92, 138,119,104, 133,114,100, 138,116,103, 155,133,120, 168,146,133, 162,140,127, 143,121,108, 127,105, 92, 132,111,106, 136,116,109, 143,123,116, 147,127,120, 148,128,121, 147,127,118, 147,124,116, 145,122,114, 137,115,104, 132,110, 99, 122, 98, 86, 112, 88, 76, 108, 84, 72, 110, 86, 74, 109, 86, 72, 109, 83, 70, 102, 79, 61, 101, 75, 58, 101, 74, 57, 102, 73, 55, 100, 67, 50,  91, 56, 37,  78, 41, 23,  70, 31, 14, 107, 66, 48, 115, 74, 56, 127, 86, 66, 138, 97, 77, 145,107, 84, 155,117, 94, 163,127,103, 170,134,110, 174,141,126, 179,146,131, 185,152,137, 189,156,139, 188,155,138, 185,152,135, 181,148,131, 179,148,130, 169,140,124, 181,153,139, 159,136,122, 156,134,123, 165,147,137, 149,132,124, 105, 90, 83,  48, 35, 27,
202,178,168, 207,183,173, 208,184,172, 206,179,168, 202,174,162, 196,167,153, 188,156,141, 180,147,130, 155,119,103, 149,112, 94, 141,103, 84, 139, 98, 78, 140, 98, 76, 139, 94, 73, 133, 88, 65, 127, 82, 59, 107, 72, 53, 121, 88, 71, 132,103, 87, 130,102, 90, 115, 91, 81,  97, 77, 68,  83, 64, 58,  73, 56, 49,  66, 49, 42,  79, 60, 53,  94, 74, 65, 102, 78, 66, 103, 75, 61, 107, 76, 58, 117, 84, 65, 128, 93, 73, 125,100, 80, 128,101, 82, 134,107, 88, 138,111, 92, 137,110, 91, 135,108, 89, 140,111, 93, 147,118,102, 144,115, 99, 140,111, 95, 142,110, 95, 145,113, 98, 145,113, 98, 139,107, 92, 134,101, 86, 133,100, 85, 121, 89, 78, 124, 92, 81, 128, 96, 83, 130, 98, 85, 130, 98, 85, 129, 97, 82, 128, 96, 81, 128, 97, 79, 125, 94, 76, 126, 93, 76, 126, 93, 74, 126, 93, 74, 126, 94, 73, 125, 93, 72, 122, 90, 69, 120, 88, 67, 115, 88, 69, 113, 84, 66, 110, 79, 61, 107, 74, 55, 107, 72, 53, 103, 66, 48,  91, 52, 35,  81, 40, 22, 105, 64, 46, 113, 72, 54, 122, 84, 65, 132, 94, 73, 140,104, 82, 148,113, 91, 156,124,101, 162,130,107, 163,133,122, 168,138,127, 178,146,133, 184,152,139, 187,155,140, 187,155,140, 187,156,138, 188,156,141, 172,143,127, 183,155,141, 167,141,128, 162,138,126, 170,150,139, 167,149,139, 121,104, 96,  43, 26, 18,
197,175,164, 200,178,167, 199,177,166, 195,171,159, 191,165,152, 187,159,147, 180,151,137, 176,143,128, 169,133,117, 157,120,102, 143,105, 86, 136, 95, 75, 135, 92, 73, 130, 85, 64, 118, 73, 52, 108, 61, 41,  92, 56, 34, 114, 77, 58, 131, 98, 79, 130, 98, 83, 116, 88, 76, 105, 81, 69, 101, 79, 68, 100, 77, 69, 104, 82, 71, 113, 89, 77, 127, 99, 87, 137,105, 90, 144,109, 89, 150,112, 89, 160,118, 94, 168,124, 99, 159,124,102, 159,124,104, 162,127,107, 165,130,110, 163,128,108, 159,122,103, 160,123,104, 164,127,108, 157,118,101, 153,114, 97, 150,111, 94, 148,109, 92, 145,103, 87, 140, 98, 82, 143,101, 87, 149,107, 93, 137, 96, 78, 137, 96, 78, 138, 97, 79, 137, 96, 78, 137, 96, 76, 137, 96, 76, 137, 96, 76, 136, 95, 73, 136, 95, 73, 137, 97, 72, 139, 99, 74, 140,100, 74, 138, 98, 72, 133, 94, 65, 130, 91, 62, 128, 89, 60, 120, 89, 69, 118, 87, 67, 113, 80, 61, 110, 75, 56, 110, 73, 55, 108, 69, 52,  95, 53, 37,  77, 36, 18,  96, 55, 37, 106, 65, 47, 119, 81, 62, 131, 94, 75, 139,107, 86, 148,117, 96, 155,127,105, 161,133,111, 157,129,118, 161,133,122, 167,137,126, 170,140,129, 173,141,128, 172,140,125, 171,139,124, 172,140,125, 167,138,122, 175,148,131, 171,145,130, 167,144,130, 160,138,125, 161,141,130, 143,125,115,  80, 62, 52,
192,172,161, 190,170,159, 183,161,150, 173,149,137, 169,142,131, 171,143,131, 172,143,129, 172,140,125, 177,141,125, 164,127,109, 147,109, 90, 139, 98, 80, 132, 89, 70, 118, 73, 52,  95, 50, 29,  77, 30, 10,  86, 48, 25,  98, 60, 39, 106, 71, 51, 107, 74, 57, 108, 79, 63, 117, 91, 78, 123, 99, 87, 125,101, 89, 131,107, 95, 138,110, 98, 148,116,101, 157,122,102, 162,124,101, 168,126,101, 173,128, 99, 176,129, 99, 172,134,111, 169,131,108, 171,130,108, 175,134,112, 175,134,114, 169,128,108, 165,124,104, 166,123,104, 168,125,106, 162,119,102, 160,114, 98, 163,117,101, 165,119,103, 160,114, 98, 154,108, 92, 152,104, 90, 153,106, 86, 151,104, 84, 148,101, 81, 147,101, 78, 146,100, 77, 147,101, 78, 147,101, 77, 147,101, 77, 143, 99, 72, 142, 98, 71, 142, 98, 69, 141, 97, 68, 138, 95, 63, 135, 92, 60, 137, 94, 62, 141, 98, 66, 123, 90, 71, 124, 91, 72, 123, 88, 69, 121, 84, 66, 122, 83, 66, 118, 76, 60,  94, 52, 36,  70, 27, 11,  80, 38, 22,  95, 53, 37, 115, 78, 60, 136,101, 82, 152,121,101, 165,137,116, 176,149,128, 184,157,136, 200,173,164, 201,173,162, 198,170,159, 193,163,152, 183,154,140, 176,144,131, 169,137,122, 166,134,119, 163,134,118, 160,131,115, 162,134,120, 168,145,131, 155,133,120, 151,131,120, 139,119,108,  76, 58, 48,
197,170,153, 172,143,127, 173,142,124, 178,145,126, 163,128,108, 156,120, 98, 165,127,104, 166,125,103, 167,126,104, 161,120, 98, 157,116, 94, 148,107, 87, 120, 82, 61,  88, 50, 31,  79, 42, 24,  88, 51, 33, 115, 70, 37, 120, 75, 42, 127, 82, 51, 134, 89, 58, 139, 95, 66, 145,101, 74, 151,107, 82, 153,111, 87, 160,118, 96, 162,121,101, 167,126,108, 170,131,114, 174,135,120, 174,136,123, 174,136,123, 173,135,122, 177,148,108, 176,144,105, 176,142,104, 178,143,105, 177,137,101, 171,127, 92, 168,122, 88, 170,121, 88, 175,125, 92, 178,128, 93, 177,129, 93, 169,123, 87, 164,120, 83, 163,121, 83, 159,120, 81, 155,116, 77, 145,127, 91, 140,122, 84, 134,115, 72, 129,111, 63, 131,111, 60, 136,115, 62, 138,114, 66, 137,112, 71, 136,107, 75, 135,105, 81, 135,104, 86, 136,102, 90, 133,101, 90, 130, 98, 85, 130, 98, 85, 132,100, 85, 143, 94, 87, 138, 89, 82, 136, 88, 78, 131, 83, 69, 128, 82, 66, 132, 87, 66, 113, 71, 47,  76, 39, 13,  63, 27,  3,  95, 65, 41, 142,116, 93, 165,143,122, 167,148,133, 176,160,147, 184,170,159, 177,164,155, 199,161,152, 193,159,147, 189,162,145, 189,168,147, 188,173,150, 183,171,149, 181,165,149, 181,161,152, 160,132,129, 157,121,125, 157,114,121, 163,118,121, 160,116,115, 163,120,111, 149,110, 93, 101, 65, 43,
155,126,110, 161,132,114, 177,146,128, 184,151,132, 176,141,121, 170,134,112, 164,126,103, 155,114, 92, 149,108, 86, 152,110, 88, 150,109, 87, 139, 98, 78, 112, 74, 53,  91, 53, 34,  93, 56, 37, 108, 71, 53, 121, 77, 48, 127, 83, 54, 135, 91, 62, 143, 99, 70, 150,106, 79, 156,112, 85, 161,117, 92, 165,120, 97, 171,129,105, 174,132,110, 178,135,116, 183,140,121, 185,142,125, 186,143,126, 185,142,126, 184,141,125, 181,147,110, 181,147,110, 185,149,113, 189,151,115, 187,144,110, 174,129, 96, 164,118, 85, 162,113, 81, 168,119, 87, 177,128, 96, 183,134,102, 179,133,100, 174,129, 96, 172,129, 95, 171,128, 94, 167,127, 92, 144,124, 89, 136,117, 77, 128,107, 64, 124,104, 54, 129,108, 55, 136,113, 61, 139,113, 64, 137,110, 67, 142,112, 78, 142,110, 85, 142,109, 90, 143,110, 95, 143,109, 97, 143,110, 95, 144,111, 94, 146,113, 96, 143, 99, 86, 140, 96, 83, 142, 99, 83, 141, 98, 81, 138, 95, 76, 139, 97, 75, 129, 87, 63, 104, 64, 39, 117, 79, 56, 140,105, 83, 170,138,117, 179,150,132, 169,143,128, 168,145,131, 176,154,143, 176,156,145, 184,141,134, 178,140,129, 173,141,126, 171,146,126, 168,150,126, 168,152,129, 168,150,130, 169,145,133, 175,144,139, 174,135,136, 167,125,127, 163,122,120, 155,114,108, 150,112, 99, 142,110, 89, 123, 91, 68,
142,111, 93, 174,141,124, 191,158,139, 187,152,133, 180,143,124, 169,131,110, 150,109, 87, 138, 96, 72, 138, 96, 72, 148,106, 82, 152,110, 88, 137, 96, 76, 114, 73, 53, 102, 64, 45, 113, 75, 56, 128, 89, 72, 133, 91, 67, 139, 97, 73, 149,107, 82, 158,116, 91, 165,123, 98, 172,128,103, 177,133,108, 179,135,110, 187,141,117, 189,143,119, 193,145,122, 196,148,125, 197,149,126, 197,149,126, 198,148,125, 197,147,124, 188,147,115, 187,146,114, 189,148,116, 191,148,116, 183,140,108, 169,124, 95, 157,112, 83, 152,107, 78, 166,121, 92, 175,130,101, 180,135,106, 177,132,103, 172,128, 99, 171,127, 98, 172,128, 99, 171,127, 98, 155,131, 95, 140,116, 78, 124,101, 57, 120, 96, 48, 130,104, 53, 140,115, 61, 147,119, 71, 148,119, 75, 151,118, 83, 151,117, 90, 150,113, 94, 148,111, 93, 147,110, 94, 146,109, 91, 146,109, 90, 145,109, 87, 146,111, 89, 141,107, 82, 146,110, 86, 148,112, 88, 141,103, 80, 142,101, 79, 141,100, 78, 133, 91, 69, 146,103, 84, 164,123,103, 188,147,129, 195,156,141, 182,144,131, 168,132,120, 166,132,120, 173,139,129, 177,128,121, 171,127,116, 164,125,108, 159,127,106, 157,131,106, 160,136,110, 162,138,114, 164,135,117, 178,144,132, 177,139,130, 170,129,123, 161,121,113, 148,112, 98, 129, 98, 78, 125, 99, 74, 140,119, 90,
159,123,107, 189,154,135, 193,156,138, 177,139,120, 171,130,110, 156,114, 92, 138, 96, 74, 142, 97, 74, 149,104, 81, 159,114, 91, 160,115, 94, 142,100, 78, 124, 83, 63, 122, 81, 63, 129, 91, 72, 139,100, 83, 149,111, 92, 155,117, 98, 165,127,106, 175,134,114, 180,139,117, 185,143,121, 189,144,121, 192,146,122, 195,147,124, 198,148,123, 201,150,123, 203,152,123, 205,151,123, 205,150,120, 203,148,118, 202,147,117, 198,151,125, 193,146,120, 191,144,118, 189,143,117, 184,140,115, 177,133,108, 171,129,104, 172,130,105, 185,143,119, 186,146,121, 185,143,119, 178,136,114, 175,133,111, 176,134,112, 175,133,111, 175,130,109, 166,137,103, 148,120, 83, 130,103, 60, 125, 97, 49, 131,104, 51, 143,113, 61, 154,124, 74, 161,128, 85, 158,124, 87, 158,123, 95, 157,119, 96, 153,115, 96, 152,114, 95, 154,116, 95, 152,114, 91, 149,112, 86, 150,128, 91, 140,117, 83, 144,120, 86, 149,120, 90, 142,111, 83, 145,109, 83, 158,117, 95, 161,118, 99, 150,104, 88, 167,120,104, 190,141,127, 204,155,141, 200,151,137, 176,126,115, 161,111,100, 165,115,104, 179,124,117, 176,124,113, 166,120,105, 157,116, 96, 154,118, 94, 159,125, 98, 165,131,104, 167,131,107, 165,127,106, 166,125,107, 169,127,111, 164,127,109, 151,120, 99, 118, 94, 68, 104, 87, 59, 145,132,100,
158,119,102, 172,133,116, 169,128,110, 157,116, 98, 157,114, 95, 147,102, 81, 144, 98, 75, 163,117, 94, 166,120, 97, 164,118, 95, 153,108, 87, 138, 93, 74, 131, 88, 69, 138, 97, 79, 151,109, 93, 155,116, 99, 167,131,117, 174,136,123, 182,145,129, 188,149,134, 193,151,135, 195,152,135, 198,153,132, 199,153,130, 201,153,130, 204,154,129, 205,154,127, 207,154,123, 208,153,123, 206,151,120, 206,150,117, 205,149,116, 205,150,130, 199,147,126, 196,145,124, 196,148,128, 194,149,128, 188,147,125, 187,151,129, 190,155,133, 176,141,121, 178,143,123, 178,143,124, 179,142,124, 182,143,126, 185,143,129, 178,136,122, 169,125,112, 172,141,110, 159,126, 91, 146,114, 75, 143,112, 66, 145,115, 65, 148,118, 66, 155,123, 76, 162,129, 86, 161,127, 90, 164,127, 98, 163,125,102, 161,123,102, 163,125,102, 170,130,105, 168,128,102, 162,123, 94, 142,131, 85, 132,119, 74, 135,120, 79, 145,125, 88, 149,122, 92, 161,129,104, 180,142,123, 189,146,130, 162,114,102, 175,123,112, 184,127,118, 194,136,125, 198,140,129, 178,118,107, 159,100, 86, 164,105, 91, 180,121,115, 176,122,112, 168,116,103, 154,109, 90, 150,108, 84, 156,117, 88, 164,123, 93, 167,123, 94, 162,117, 88, 158,112, 86, 176,134,109, 183,147,121, 170,143,116, 127,110, 82, 102, 91, 61, 146,141,109,
138, 96, 80, 143,100, 84, 141, 98, 81, 142, 97, 78, 144, 99, 78, 141, 94, 74, 146, 98, 76, 160,112, 90, 163,115, 93, 148,102, 79, 131, 84, 64, 125, 80, 61, 133, 90, 73, 151,109, 93, 168,129,112, 179,140,123, 185,148,139, 189,152,143, 194,158,146, 198,160,149, 200,160,148, 199,160,145, 201,160,142, 203,160,141, 206,161,140, 207,161,137, 207,160,134, 209,159,132, 208,159,129, 207,156,125, 206,155,124, 207,154,123, 207,149,135, 202,146,131, 198,147,130, 196,149,133, 189,148,130, 179,144,125, 173,142,122, 171,144,125, 170,145,125, 180,154,137, 193,166,149, 205,176,162, 215,181,169, 217,180,171, 205,167,158, 192,152,144, 193,159,131, 178,145,114, 166,134, 96, 166,134, 93, 167,136, 90, 163,132, 85, 160,129, 83, 162,130, 89, 163,130, 97, 168,133,105, 166,130,106, 162,124,103, 163,125,102, 166,129,103, 162,123, 94, 151,112, 81, 119,116, 61, 113,107, 55, 122,111, 65, 138,123, 84, 156,133,102, 177,146,125, 190,153,137, 187,143,134, 154,105,100, 166,113,109, 160,102, 98, 161,101, 93, 177,114,105, 169,107, 94, 160, 97, 82, 173,110, 93, 174,116,112, 174,119,112, 167,115,104, 153,106, 90, 149,104, 83, 158,112, 86, 166,119, 91, 167,118, 86, 166,115, 84, 152,103, 71, 185,140,111, 198,161,132, 183,156,127, 144,127, 99, 118,108, 81, 163,159,132,
122, 76, 61, 122, 76, 60, 127, 81, 65, 129, 82, 64, 130, 83, 63, 141, 93, 73, 145, 97, 75, 135, 87, 65, 134, 86, 64, 118, 71, 51, 111, 66, 47, 123, 80, 61, 144,103, 85, 161,122,105, 179,140,125, 192,155,139, 197,160,152, 200,163,155, 203,166,157, 204,167,158, 205,167,156, 204,166,153, 205,167,154, 207,168,153, 204,165,148, 204,166,147, 205,164,144, 204,163,143, 203,162,140, 202,162,137, 201,161,136, 200,160,135, 207,151,138, 201,148,134, 196,147,133, 192,149,133, 187,151,135, 179,150,132, 176,153,135, 177,159,139, 203,186,168, 219,202,186, 239,220,205, 252,230,217, 255,232,221, 255,229,221, 254,219,213, 246,211,205, 228,194,169, 198,164,137, 171,138,105, 165,135, 97, 170,141, 99, 170,141, 99, 166,138, 98, 166,138,101, 167,136,107, 172,140,115, 171,139,118, 168,133,113, 168,133,111, 172,136,110, 163,128, 98, 149,113, 81, 105,104, 47, 103,100, 47, 117,109, 62, 140,126, 89, 163,144,114, 182,155,136, 174,140,130, 148,107,103, 111, 63, 63, 140, 89, 88, 144, 88, 87, 144, 86, 82, 162,104, 93, 158, 99, 85, 147, 88, 70, 160,102, 82, 159,108,104, 164,115,110, 160,113,105, 149,103, 90, 147,101, 85, 157,110, 90, 164,117, 91, 166,115, 86, 155,102, 71, 130, 77, 46, 172,123, 93, 186,145,117, 167,135,112, 147,125,104, 136,123,106, 185,176,159,
107, 61, 46, 111, 64, 48, 121, 74, 58, 119, 72, 54, 120, 71, 54, 146, 98, 78, 152,104, 84, 122, 74, 54, 104, 56, 36,  95, 48, 30, 104, 59, 40, 132, 91, 73, 157,118,101, 169,132,116, 180,144,130, 193,157,143, 202,165,156, 205,168,159, 207,170,161, 208,171,162, 205,171,161, 205,171,161, 207,173,163, 207,175,164, 200,168,157, 198,168,157, 197,167,156, 195,167,155, 193,165,153, 191,165,152, 190,164,149, 190,164,149, 204,155,141, 198,150,136, 193,150,134, 195,158,142, 199,170,152, 207,184,166, 218,201,181, 228,215,196, 218,207,189, 236,225,207, 253,240,224, 255,242,229, 255,236,225, 255,233,223, 255,232,226, 255,232,227, 251,219,198, 204,172,149, 157,126, 98, 144,115, 83, 152,126, 89, 161,135, 98, 165,141,105, 168,143,112, 168,142,117, 176,149,128, 181,152,136, 183,152,134, 190,159,139, 198,166,143, 193,159,132, 179,145,117, 110,107, 52, 113,107, 57, 127,119, 73, 150,136,101, 174,154,129, 186,158,144, 158,125,118, 111, 73, 72,  74, 32, 34, 125, 79, 81, 146, 98, 96, 149,100, 95, 163,113,102, 148, 99, 82, 123, 75, 53, 128, 81, 55, 139, 98, 92, 147,108,101, 146,107,100, 137, 99, 90, 136, 96, 86, 148,106, 92, 158,111, 93, 160,108, 86, 135, 79, 54, 102, 46, 19, 150, 96, 70, 162,116, 93, 141,102, 85, 137,109, 98, 146,125,120, 200,185,182,
 70, 24,  9,  82, 34, 20,  80, 33, 17,  78, 31, 15, 105, 56, 39, 141, 92, 75, 142, 93, 76, 115, 68, 50, 116, 69, 51, 123, 80, 63, 138, 96, 80, 154,115,100, 168,130,117, 179,145,133, 188,156,143, 194,162,151, 205,167,158, 206,169,160, 208,171,162, 207,173,164, 205,172,163, 202,172,164, 199,170,162, 195,170,163, 192,169,163, 193,173,166, 195,176,170, 195,180,175, 199,186,180, 201,187,184, 191,180,176, 181,170,166, 201,158,142, 196,157,140, 199,164,145, 211,180,160, 224,202,181, 237,221,198, 244,232,210, 247,239,216, 247,241,219, 245,238,219, 246,238,219, 254,241,225, 255,242,228, 255,235,222, 244,220,210, 234,207,198, 227,194,177, 200,167,148, 180,150,126, 174,147,118, 166,142,108, 156,133, 99, 166,146,113, 190,169,142, 219,197,176, 234,211,195, 243,217,204, 238,210,198, 235,206,190, 241,213,192, 250,220,194, 252,222,194, 188,180,131, 153,142, 96, 186,172,133, 238,222,189, 242,220,197, 240,212,200, 211,180,175, 146,110,110,  73, 34, 35, 132, 92, 92, 161,122,117, 156,118,109, 140,103, 85, 102, 66, 44,  86, 51, 23, 114, 79, 49, 117, 87, 79, 118, 89, 81, 116, 87, 81, 113, 84, 80, 117, 86, 81, 129, 92, 86, 134, 91, 82, 133, 85, 71, 104, 51, 33, 114, 59, 38, 134, 79, 59, 146, 97, 82, 139, 96, 89, 136,100,100, 172,142,150, 220,194,205,
 94, 48, 35,  94, 48, 35,  93, 47, 32,  98, 50, 36, 114, 67, 51, 132, 85, 69, 136, 90, 74, 131, 85, 69, 146,103, 86, 152,110, 94, 160,123,107, 170,134,120, 177,145,132, 183,153,142, 188,160,149, 191,164,155, 213,177,165, 214,178,166, 210,176,166, 205,172,163, 200,170,160, 199,172,165, 203,180,174, 207,188,182, 227,209,205, 232,218,217, 236,226,225, 240,231,232, 241,237,238, 239,237,240, 232,230,233, 222,222,224, 224,192,171, 216,184,163, 209,181,159, 214,190,166, 225,205,181, 233,217,192, 233,221,195, 231,221,196, 230,220,195, 229,219,194, 231,219,197, 235,220,199, 236,218,198, 232,211,194, 222,199,183, 215,189,174, 236,200,184, 223,190,171, 218,188,164, 215,188,159, 203,178,147, 187,164,132, 185,164,135, 195,175,150, 225,204,185, 233,211,198, 239,215,205, 238,211,200, 234,206,192, 235,206,188, 240,210,186, 241,211,185, 234,217,174, 205,187,147, 221,201,166, 252,228,200, 255,229,208, 255,237,223, 255,228,221, 222,189,184, 209,174,170, 230,195,189, 224,190,180, 206,174,159, 185,154,133, 124, 97, 68,  72, 46, 13,  67, 43,  7,  81, 59, 46,  75, 55, 44,  70, 50, 43,  72, 51, 50,  87, 62, 65, 102, 73, 75, 105, 71, 70, 102, 61, 55, 108, 61, 51, 123, 74, 60, 137, 85, 72, 136, 86, 79, 136, 90, 92, 159,119,128, 204,170,187, 244,212,235,
129, 85, 74, 120, 76, 65, 120, 76, 63, 131, 87, 74, 137, 94, 78, 137, 94, 78, 147,104, 88, 161,119,103, 172,133,118, 176,140,126, 182,148,136, 186,156,145, 190,163,152, 193,169,159, 197,174,166, 198,178,171, 206,174,161, 205,175,164, 204,174,163, 200,172,161, 197,173,163, 206,183,175, 221,202,195, 235,217,213, 244,230,227, 248,238,236, 253,244,245, 251,247,248, 248,246,249, 247,246,251, 243,244,248, 238,239,243, 251,225,198, 237,211,184, 221,197,171, 217,196,169, 225,205,178, 232,212,185, 228,211,183, 222,205,177, 224,207,179, 224,207,179, 227,207,180, 230,209,182, 234,210,184, 234,208,183, 231,203,179, 227,199,175, 229,191,172, 233,197,175, 240,206,179, 242,211,182, 233,207,174, 220,197,165, 214,193,164, 215,195,170, 218,197,180, 217,195,182, 219,195,185, 222,195,184, 222,193,179, 221,190,172, 223,191,168, 228,196,171, 234,210,172, 222,198,162, 222,198,164, 229,202,173, 239,208,187, 255,226,209, 255,238,223, 255,227,215, 252,218,206, 253,220,205, 239,208,188, 235,207,183, 234,207,177, 192,168,132, 147,125, 84, 142,121, 78, 138,120, 98, 133,116,100, 128,111,103, 125,109,109, 124,107,113, 112, 92,101,  84, 61, 67,  63, 33, 35, 105, 70, 66, 104, 64, 56,  95, 51, 42,  94, 50, 47, 130, 89, 95, 189,150,168, 227,193,218, 236,203,234,
163,123,113, 156,113,104, 158,116,104, 169,127,115, 171,129,117, 165,126,111, 174,135,120, 191,153,140, 184,151,136, 187,155,142, 190,162,151, 192,168,158, 192,172,163, 195,176,169, 197,180,173, 198,183,178, 203,179,167, 203,179,167, 203,181,168, 206,184,173, 213,193,182, 228,210,200, 244,227,219, 254,239,232, 253,240,234, 255,246,240, 255,248,243, 249,241,238, 244,236,234, 242,237,234, 244,239,236, 243,239,238, 250,230,197, 236,216,183, 218,198,165, 210,187,155, 215,190,159, 225,198,168, 228,201,171, 227,198,166, 227,196,165, 224,191,160, 219,186,155, 222,187,157, 228,193,163, 234,199,167, 235,200,168, 233,198,166, 231,185,161, 237,193,166, 240,199,169, 239,203,169, 239,207,169, 238,210,173, 236,210,177, 232,206,181, 222,197,177, 211,183,169, 205,175,165, 208,176,165, 208,175,160, 207,170,151, 211,173,150, 220,183,156, 208,180,143, 214,186,149, 210,180,146, 206,173,142, 217,183,155, 234,198,172, 243,206,180, 245,208,182, 242,205,179, 241,204,177, 235,200,168, 239,207,169, 240,211,171, 221,192,148, 211,184,137, 229,203,154, 245,224,193, 248,230,206, 253,237,224, 255,241,240, 247,236,244, 227,215,227, 199,186,196, 181,162,168, 156,132,132, 142,115,108, 118, 88, 80, 115, 84, 81, 154,123,128, 205,177,192, 229,201,226, 221,196,228,
189,151,142, 187,149,140, 187,149,138, 191,153,142, 194,156,145, 194,158,146, 198,162,150, 199,167,154, 194,164,153, 196,169,158, 198,176,165, 199,180,173, 198,183,176, 199,186,180, 199,188,184, 200,191,186, 202,188,177, 198,184,173, 195,181,170, 199,185,174, 208,194,183, 216,199,189, 217,200,190, 215,199,186, 234,218,205, 243,227,214, 250,232,220, 247,229,217, 242,224,212, 242,224,212, 243,225,213, 244,226,214, 230,215,176, 224,206,168, 210,188,151, 197,171,136, 200,170,134, 216,180,146, 230,190,155, 237,192,159, 242,193,160, 231,181,148, 219,169,134, 218,168,133, 226,178,142, 233,188,149, 236,191,152, 234,189,150, 243,190,158, 243,190,156, 236,188,150, 230,187,145, 232,193,150, 237,202,160, 237,203,166, 228,197,166, 234,202,179, 217,184,167, 206,170,156, 206,167,152, 207,166,148, 207,165,143, 216,170,144, 227,182,151, 215,185,147, 228,196,158, 219,187,149, 210,176,139, 223,185,148, 231,191,155, 230,188,150, 232,188,149, 238,195,153, 238,195,152, 236,193,148, 234,192,144, 225,185,134, 211,171,119, 215,178,125, 237,200,145, 240,212,172, 248,223,192, 255,238,219, 255,247,242, 255,248,255, 252,246,255, 250,246,255, 255,250,255, 238,229,230, 235,222,216, 222,208,199, 210,193,186, 204,188,189, 211,195,206, 223,208,229, 231,216,245,
201,167,158, 204,170,161, 202,168,159, 199,165,155, 201,167,157, 206,172,162, 205,173,162, 198,170,158, 205,178,167, 209,187,176, 215,196,189, 221,206,199, 225,214,208, 227,219,216, 229,224,220, 231,227,224, 223,219,210, 215,211,200, 208,201,191, 207,199,188, 207,197,185, 200,188,174, 186,170,155, 173,154,139, 198,177,158, 216,191,171, 231,204,183, 240,209,188, 240,208,185, 241,207,182, 239,203,179, 236,200,174, 221,206,163, 221,202,160, 210,187,146, 198,166,127, 201,161,125, 220,172,136, 237,181,146, 246,183,150, 238,172,138, 228,162,127, 219,154,116, 220,155,117, 229,167,126, 239,180,136, 243,186,141, 242,188,142, 236,173,132, 231,170,126, 222,166,119, 217,165,117, 218,170,121, 222,178,131, 221,179,137, 216,176,140, 219,180,151, 209,168,146, 202,159,140, 204,157,139, 208,160,138, 216,165,138, 227,174,143, 236,182,148, 223,191,152, 223,191,150, 211,178,135, 205,168,124, 213,175,128, 219,177,127, 220,174,124, 224,177,123, 223,172,117, 224,172,115, 228,176,118, 229,177,119, 223,171,111, 214,162,102, 213,161,101, 215,163,103, 215,177,128, 226,193,152, 241,215,190, 249,230,223, 244,235,240, 237,235,249, 239,241,255, 246,250,255, 252,255,255, 249,252,243, 247,248,234, 242,242,230, 230,229,224, 217,216,221, 217,216,230, 225,226,246,
209,176,169, 209,176,169, 208,175,166, 206,173,164, 206,173,164, 206,176,166, 209,181,170, 210,183,172, 220,198,187, 225,207,197, 234,219,212, 243,232,226, 249,241,238, 251,247,244, 253,252,250, 255,254,252, 253,255,249, 247,248,240, 241,241,233, 239,237,225, 237,231,219, 228,216,202, 211,196,177, 199,178,157, 204,178,155, 220,189,161, 236,199,170, 244,203,171, 247,203,168, 249,201,165, 245,195,158, 240,190,153, 216,199,155, 217,196,153, 209,182,139, 199,164,124, 207,159,121, 225,167,130, 238,170,135, 239,165,130, 223,143,108, 223,141,104, 221,142,103, 221,144,102, 223,150,107, 228,160,113, 233,167,119, 236,173,122, 221,151,102, 214,146, 97, 205,142, 89, 199,140, 84, 192,137, 81, 189,139, 86, 193,147, 98, 198,153,112, 195,149,116, 198,151,125, 200,150,127, 199,147,125, 203,147,122, 209,150,120, 212,152,118, 212,150,113, 183,152,108, 172,141, 95, 165,131, 85, 168,131, 79, 175,134, 80, 187,142, 83, 203,153, 92, 215,161, 97, 227,170,103, 232,173,105, 242,181,114, 245,182,115, 237,172,106, 231,166,102, 222,157, 93, 207,142, 78, 194,147, 91, 203,161,113, 223,190,159, 244,222,209, 251,240,244, 244,243,255, 234,241,255, 229,242,250, 226,241,238, 220,234,221, 217,230,212, 222,235,217, 223,235,223, 216,228,226, 209,222,230, 208,220,234,
214,181,174, 210,177,170, 210,177,170, 214,181,172, 210,180,170, 207,179,168, 215,188,177, 227,203,193, 236,216,207, 241,224,216, 247,234,226, 251,242,237, 251,246,242, 247,246,242, 245,245,243, 244,244,244, 241,248,241, 239,246,239, 241,244,237, 243,243,233, 244,240,228, 241,232,215, 235,218,200, 230,208,185, 226,196,170, 234,199,169, 241,198,164, 241,193,155, 241,189,149, 244,187,144, 243,184,140, 241,180,136, 203,186,140, 204,183,138, 198,169,125, 194,155,114, 205,153,114, 223,159,123, 228,154,119, 224,141,107, 241,152,118, 248,158,123, 250,162,122, 245,161,117, 236,155,110, 229,153,104, 230,158,108, 234,164,112, 226,153,102, 217,146, 92, 205,136, 79, 186,124, 65, 169,110, 52, 159,104, 48, 168,116, 66, 183,134, 91, 195,145,110, 205,154,125, 210,156,132, 202,146,121, 195,135,107, 192,129, 98, 181,117, 81, 169,104, 66, 137,106, 60, 122, 91, 44, 124, 91, 40, 138,101, 46, 146,106, 45, 164,119, 54, 192,142, 73, 211,154, 83, 228,168, 95, 245,181,107, 255,198,125, 255,195,123, 255,182,113, 255,183,115, 254,179,112, 239,164, 99, 215,163,103, 211,163,114, 218,179,146, 238,212,199, 254,242,246, 253,252,255, 240,249,255, 229,246,254, 227,247,245, 233,255,240, 236,255,237, 226,248,227, 212,233,218, 205,224,218, 205,224,228, 208,228,237,
222,184,183, 218,183,181, 213,182,180, 211,182,184, 206,184,186, 206,190,193, 216,205,209, 226,221,225, 228,227,232, 226,230,233, 227,233,233, 228,237,236, 234,243,240, 238,249,243, 243,254,246, 247,255,249, 241,250,255, 240,245,251, 245,243,244, 254,243,239, 253,231,220, 239,206,189, 225,181,156, 221,168,137, 236,178,140, 251,190,146, 255,198,151, 255,194,143, 246,185,131, 238,178,124, 230,173,118, 225,170,114, 233,163,112, 236,166,115, 231,159,111, 216,146, 97, 208,140, 93, 213,149,103, 223,165,117, 227,175,127, 237,191,142, 238,191,145, 242,193,150, 246,191,152, 241,175,140, 232,153,123, 230,143,116, 237,143,118, 209,148, 85, 217,159, 96, 213,162, 99, 188,144, 83, 154,118, 60, 139,110, 54, 148,127, 72, 165,148, 96, 184,170,121, 194,180,133, 200,183,137, 192,171,126, 174,147,104, 153,121, 80, 133, 98, 56, 121, 84, 42, 149, 93, 19, 146, 94, 19, 139, 93, 18, 136, 97, 20, 148,115, 38, 172,140, 65, 190,156, 84, 197,158, 89, 211,166, 99, 223,172,109, 240,181,121, 249,189,129, 253,193,133, 254,195,135, 254,198,137, 255,202,138, 234,194,143, 236,198,151, 240,207,166, 249,220,188, 255,235,212, 255,244,231, 255,247,242, 251,247,248, 248,249,254, 247,250,255, 246,251,255, 244,249,252, 241,247,243, 237,244,236, 234,240,228, 231,237,223,
221,186,184, 219,185,183, 217,187,185, 217,191,192, 212,192,193, 210,195,198, 216,207,210, 224,219,223, 225,224,229, 223,227,230, 225,231,231, 226,235,234, 230,239,236, 234,243,238, 238,248,240, 240,250,242, 241,248,254, 241,244,249, 246,244,245, 255,244,240, 255,233,222, 240,207,190, 225,183,159, 219,168,139, 240,184,149, 252,193,153, 255,197,153, 253,192,145, 243,185,137, 235,179,130, 227,174,122, 221,169,119, 225,154,102, 230,157,106, 228,154,105, 221,147, 98, 222,148, 99, 233,163,114, 241,178,127, 244,186,136, 243,190,140, 241,189,139, 244,188,141, 244,181,137, 236,164,124, 223,141,104, 219,126, 93, 220,123, 91, 216,147, 90, 225,160,104, 230,171,115, 220,167,113, 197,154,101, 182,146, 94, 180,150,100, 183,159,111, 188,165,121, 194,171,129, 192,167,126, 175,146,106, 156,121, 83, 148,109, 70, 149,105, 68, 152,106, 70, 175,121, 61, 170,120, 59, 161,117, 54, 154,116, 53, 161,127, 64, 176,146, 84, 192,160, 99, 200,164,106, 213,170,115, 227,177,126, 241,188,138, 250,194,145, 249,193,144, 244,191,141, 240,188,138, 238,188,137, 247,207,156, 244,206,159, 242,209,168, 245,216,184, 249,227,204, 252,236,223, 250,241,236, 247,243,244, 246,247,252, 244,247,254, 244,249,253, 242,250,252, 243,249,245, 241,248,240, 239,247,234, 239,245,231,
219,190,186, 217,187,185, 213,187,186, 212,191,190, 210,191,193, 208,196,198, 214,208,210, 221,219,222, 232,233,237, 232,236,239, 233,239,239, 234,243,242, 236,245,242, 238,247,242, 239,248,243, 240,250,242, 241,246,250, 243,244,246, 249,245,244, 255,246,240, 255,238,227, 248,217,199, 234,193,171, 227,180,152, 242,189,157, 248,192,157, 249,191,153, 241,186,145, 235,182,140, 229,178,135, 221,172,129, 213,166,122, 228,155,104, 232,156,106, 232,154,105, 233,153,104, 237,157,108, 243,165,116, 246,173,122, 246,176,124, 239,174,120, 236,173,119, 238,173,119, 239,169,117, 234,156,108, 225,138, 93, 218,122, 80, 216,117, 76, 215,139, 90, 223,151,103, 235,167,120, 239,178,133, 233,179,135, 223,176,134, 214,172,132, 210,172,133, 197,162,124, 201,165,129, 195,157,121, 177,134,100, 164,115, 83, 172,119, 87, 194,137,107, 214,155,125, 218,167,124, 210,163,121, 196,155,111, 183,149,104, 185,154,108, 199,172,127, 219,190,148, 233,200,159, 250,210,174, 255,213,178, 255,212,179, 255,208,175, 249,199,166, 238,189,156, 228,184,149, 226,182,147, 249,209,158, 241,205,157, 234,201,160, 232,203,171, 234,212,189, 239,223,210, 241,232,227, 240,236,237, 241,242,247, 238,243,249, 237,245,248, 237,245,247, 238,247,244, 238,248,240, 241,249,238, 241,249,236,
220,196,192, 215,191,189, 208,188,187, 206,190,190, 206,194,194, 211,202,203, 222,218,219, 231,231,233, 240,244,245, 240,246,246, 243,249,249, 243,252,251, 244,253,250, 244,253,248, 243,252,247, 243,253,245, 241,245,246, 244,244,244, 250,245,242, 255,246,238, 255,241,230, 255,227,211, 248,210,189, 242,198,173, 237,188,158, 239,186,154, 235,182,148, 229,176,142, 225,175,140, 224,176,140, 216,170,134, 207,163,126, 228,156,106, 232,156,107, 236,155,108, 240,158,111, 246,159,114, 246,160,113, 239,157,109, 231,153,104, 223,150, 97, 223,152, 98, 225,156, 99, 229,156,101, 230,153, 99, 226,143, 91, 220,130, 78, 217,123, 72, 211,133, 94, 217,142,103, 227,155,117, 232,167,129, 233,173,137, 228,176,139, 222,173,140, 217,172,139, 205,162,130, 210,165,134, 207,160,130, 196,145,116, 191,134,107, 204,143,115, 227,161,135, 244,177,151, 230,183,155, 221,177,148, 207,168,139, 193,162,131, 193,166,136, 210,187,155, 236,211,180, 254,227,198, 255,231,204, 255,226,204, 255,219,197, 252,207,186, 239,197,175, 232,191,169, 228,192,168, 229,194,172, 242,204,155, 236,199,154, 227,195,156, 225,198,168, 231,209,186, 238,222,209, 241,232,227, 242,238,239, 239,240,244, 235,240,246, 232,239,245, 231,241,242, 230,240,239, 231,242,236, 232,242,233, 233,243,232,
214,196,192, 210,195,192, 211,197,194, 216,205,203, 222,214,212, 227,223,222, 236,236,236, 246,247,249, 240,244,245, 240,246,246, 240,249,248, 241,250,247, 242,251,248, 241,250,245, 240,249,244, 239,248,243, 243,247,246, 246,246,244, 248,245,240, 253,243,234, 255,237,226, 255,228,214, 251,216,196, 246,204,180, 230,183,157, 230,181,151, 226,175,144, 221,170,139, 223,172,141, 224,175,143, 219,172,142, 212,165,135, 222,153,111, 224,153,111, 233,155,116, 243,160,120, 250,162,124, 244,156,116, 234,146,106, 223,140, 96, 211,134, 88, 212,142, 91, 217,150, 98, 223,156,103, 228,158,106, 227,156,104, 223,147, 95, 218,141, 89, 220,150,116, 225,157,122, 230,166,131, 229,169,135, 222,168,134, 212,162,129, 203,156,126, 198,155,123, 195,151,122, 202,157,128, 207,160,132, 207,156,129, 210,153,126, 216,154,129, 219,155,128, 219,153,127, 202,158,133, 196,154,129, 187,152,124, 180,150,122, 179,156,125, 189,168,137, 207,186,155, 224,200,172, 224,194,168, 229,195,170, 231,195,173, 231,193,172, 228,192,170, 228,196,173, 231,203,181, 235,209,186, 242,206,158, 238,204,159, 235,203,165, 236,209,179, 243,223,199, 249,236,220, 253,244,237, 250,249,247, 243,244,248, 239,244,248, 233,242,247, 230,240,242, 226,238,236, 224,236,232, 223,236,229, 224,235,227,
203,194,189, 204,196,193, 213,205,202, 225,220,217, 231,230,228, 235,235,235, 239,241,240, 242,246,247, 237,243,243, 238,244,244, 237,246,245, 238,247,244, 238,247,244, 240,246,244, 240,246,242, 240,246,242, 244,250,248, 247,249,246, 246,245,241, 247,238,231, 248,231,221, 248,222,207, 241,208,189, 235,194,172, 226,180,156, 228,178,151, 227,173,145, 224,169,139, 226,171,141, 230,175,145, 228,175,144, 223,170,139, 225,163,126, 225,159,124, 232,159,126, 242,161,131, 244,159,130, 235,148,118, 224,137,107, 213,133,100, 207,134, 99, 212,149,108, 222,165,122, 229,176,132, 237,186,141, 242,191,144, 241,189,142, 238,184,138, 237,184,150, 242,189,155, 244,195,162, 239,193,159, 223,180,146, 203,164,131, 186,150,116, 177,142,110, 172,137,105, 181,145,113, 195,154,124, 208,163,132, 219,170,140, 222,169,138, 211,156,126, 199,142,113, 179,134,101, 175,135,100, 172,138,101, 172,144,104, 170,149,106, 169,150,107, 174,155,112, 183,160,119, 194,166,127, 207,175,137, 221,187,152, 230,196,161, 231,201,165, 229,203,168, 228,206,169, 228,208,171, 239,205,160, 237,205,164, 238,210,173, 244,219,189, 250,232,210, 255,243,227, 255,248,240, 251,250,248, 247,251,252, 243,251,254, 239,249,251, 234,245,247, 230,242,242, 224,239,236, 221,236,231, 219,234,227,
214,213,209, 213,212,208, 215,216,211, 223,223,221, 227,229,226, 226,230,229, 227,231,230, 229,235,233, 235,241,241, 235,241,241, 235,241,239, 236,242,240, 237,243,241, 239,245,243, 240,246,244, 241,247,243, 240,248,250, 244,250,250, 246,246,244, 243,238,232, 243,230,221, 241,219,205, 233,202,184, 223,185,162, 223,177,151, 229,175,147, 229,172,142, 228,167,136, 230,167,134, 235,171,136, 236,172,137, 232,168,133, 228,168,134, 226,161,129, 228,157,127, 235,155,128, 236,150,127, 228,140,118, 220,136,112, 214,136,113, 223,156,129, 231,174,145, 239,194,161, 241,205,169, 245,212,177, 247,219,182, 247,219,182, 243,215,178, 241,207,170, 244,210,173, 244,212,174, 238,210,171, 226,200,163, 209,185,147, 192,168,130, 181,157,119, 175,151,113, 182,156,119, 194,164,128, 207,173,136, 221,183,147, 224,184,148, 217,173,138, 203,159,124, 179,136, 85, 172,131, 79, 168,133, 79, 169,140, 84, 170,146, 86, 167,147, 86, 170,148, 88, 177,153, 93, 203,174,116, 216,184,127, 230,197,143, 238,205,151, 236,206,152, 227,202,146, 218,199,143, 213,196,140, 224,195,153, 226,196,158, 230,204,171, 239,218,189, 248,232,209, 253,241,227, 253,246,238, 247,246,242, 248,252,253, 245,253,255, 242,252,254, 239,250,252, 233,247,247, 229,243,243, 225,240,237, 223,238,233,
241,246,242, 232,237,233, 224,229,225, 220,224,223, 218,224,222, 216,222,220, 219,225,223, 224,230,228, 230,236,234, 230,236,234, 229,235,233, 230,236,234, 231,237,235, 234,240,238, 237,243,241, 238,244,242, 231,245,248, 238,249,251, 243,249,249, 243,242,238, 243,234,225, 240,222,208, 230,201,183, 220,182,159, 220,173,147, 228,173,142, 233,170,137, 232,164,127, 234,162,124, 239,164,125, 242,164,125, 241,162,121, 222,157,119, 219,149,113, 221,145,113, 229,143,116, 232,142,118, 231,139,118, 231,143,123, 231,153,133, 249,183,161, 254,202,178, 255,219,193, 247,221,194, 237,220,192, 230,219,191, 223,216,187, 217,210,181, 233,214,174, 231,212,172, 229,210,170, 228,210,170, 226,208,168, 218,203,162, 207,192,149, 201,184,141, 202,183,141, 206,184,143, 207,184,142, 211,183,143, 218,186,147, 221,188,147, 215,180,140, 207,169,130, 184,136, 74, 170,125, 60, 159,120, 53, 159,126, 55, 164,136, 63, 170,144, 69, 180,154, 77, 192,163, 87, 213,181,106, 223,186,115, 233,196,125, 234,200,129, 227,197,127, 219,192,121, 209,189,118, 206,188,116, 213,187,150, 215,191,157, 221,200,169, 232,215,189, 246,231,210, 252,243,228, 252,248,239, 248,249,244, 245,249,248, 242,250,252, 242,252,253, 240,251,253, 236,250,250, 231,247,246, 227,243,240, 225,241,238,
242,251,250, 230,239,238, 213,222,221, 201,210,207, 197,206,203, 201,210,207, 210,216,214, 214,220,218, 218,224,222, 221,227,225, 224,230,228, 227,233,231, 228,234,232, 231,237,235, 234,240,238, 236,242,240, 232,249,255, 233,248,253, 237,247,249, 243,247,246, 249,244,238, 249,235,222, 245,219,202, 242,206,182, 228,183,154, 227,171,138, 226,161,123, 229,156,115, 236,157,114, 242,158,112, 244,156,110, 243,152,105, 226,145, 98, 224,142, 95, 227,138, 96, 231,134, 99, 229,129, 97, 232,131,103, 245,149,124, 255,173,149, 255,189,164, 251,197,171, 242,205,178, 236,212,184, 229,218,190, 224,219,190, 219,219,191, 216,219,192, 234,216,178, 231,213,173, 227,209,169, 223,205,165, 219,201,161, 214,197,154, 209,190,148, 205,186,143, 199,178,135, 204,179,138, 209,182,139, 213,184,142, 216,183,142, 215,180,140, 213,175,136, 211,173,134, 198,147, 82, 174,125, 59, 157,112, 44, 161,123, 50, 168,135, 58, 174,143, 63, 190,159, 79, 213,178, 97, 219,180,101, 223,182,103, 225,183,107, 223,184,109, 219,183,109, 211,181,108, 208,182,107, 205,183,108, 200,179,148, 200,181,151, 205,188,162, 220,205,182, 237,226,208, 248,240,227, 248,245,236, 243,244,238, 242,247,243, 240,249,248, 239,249,250, 238,250,250, 234,248,248, 231,245,245, 226,242,241, 224,240,237,
237,249,249, 223,235,235, 204,214,215, 189,199,198, 185,194,193, 188,197,194, 197,203,201, 201,207,205, 212,218,214, 218,224,220, 225,231,229, 231,237,235, 234,240,238, 236,242,240, 235,244,241, 236,245,244, 231,251,255, 231,250,255, 235,249,252, 241,250,249, 248,247,242, 250,240,230, 248,227,210, 248,216,193, 237,193,164, 230,176,142, 220,156,118, 220,147,104, 231,149,102, 238,150,102, 239,147, 98, 237,143, 92, 227,133, 72, 225,129, 71, 228,124, 71, 233,122, 76, 234,121, 79, 238,126, 88, 248,144,109, 255,163,130, 253,177,145, 244,185,153, 239,196,162, 233,207,174, 230,214,181, 227,218,187, 223,218,188, 221,218,187, 238,215,181, 235,212,178, 231,207,171, 227,203,167, 224,198,161, 221,193,156, 217,187,149, 215,183,144, 212,178,140, 213,178,140, 213,175,138, 211,171,135, 209,166,131, 206,162,127, 204,158,124, 202,156,122, 204,151, 99, 187,136, 83, 174,127, 71, 174,134, 73, 182,144, 79, 186,151, 83, 199,162, 92, 212,174,103, 222,179,110, 222,174,108, 218,170,104, 214,169,104, 211,172,107, 210,176,112, 210,182,117, 211,186,122, 209,195,169, 212,198,172, 215,203,181, 220,212,191, 227,220,204, 233,229,217, 236,236,226, 237,240,233, 236,241,235, 234,243,240, 233,243,242, 233,245,243, 231,243,241, 227,242,239, 224,239,236, 222,237,234,
234,248,251, 220,231,233, 198,209,211, 183,193,194, 180,189,188, 183,192,189, 191,197,195, 196,201,197, 211,216,212, 219,224,220, 229,234,230, 236,242,240, 240,246,244, 239,248,245, 239,248,247, 239,248,247, 230,250,255, 230,249,255, 233,248,253, 239,249,250, 247,249,244, 249,245,234, 250,237,221, 254,229,207, 243,207,181, 231,185,152, 214,158,121, 211,143,104, 216,141, 99, 223,141, 94, 222,136, 89, 216,128, 80, 231,129, 63, 229,124, 59, 229,119, 60, 233,118, 63, 236,118, 68, 240,123, 79, 245,136, 93, 248,151,109, 243,161,121, 236,173,132, 235,187,147, 235,202,161, 236,213,172, 237,219,181, 236,222,185, 235,222,187, 241,210,182, 238,207,179, 237,203,176, 234,199,171, 232,195,166, 229,190,159, 226,182,153, 223,178,147, 218,171,141, 217,168,138, 213,162,133, 212,158,130, 210,156,130, 210,156,130, 213,157,132, 214,158,133, 218,167,136, 212,163,131, 204,160,125, 201,162,121, 203,169,124, 209,175,127, 215,179,129, 218,178,127, 217,173,124, 213,165,117, 206,158,112, 203,159,114, 209,168,124, 218,184,139, 225,196,152, 228,204,160, 230,223,204, 234,227,208, 236,231,212, 233,227,211, 226,224,209, 224,224,212, 230,232,221, 235,238,229, 231,236,230, 230,236,232, 229,238,233, 229,240,236, 228,240,236, 226,238,234, 225,237,235, 224,236,234,
234,247,253, 222,233,237, 204,215,219, 194,204,206, 193,201,203, 200,206,206, 205,209,208, 207,212,208, 220,222,219, 225,230,226, 233,238,234, 239,245,243, 242,248,246, 240,249,248, 239,248,247, 238,248,247, 230,247,254, 228,245,252, 231,245,248, 235,245,246, 241,247,243, 246,246,238, 250,242,231, 254,238,222, 249,224,202, 241,207,180, 228,184,155, 221,168,136, 220,160,124, 221,153,116, 217,145,105, 211,137, 98, 223,129, 68, 219,123, 63, 217,116, 60, 217,111, 59, 220,112, 65, 222,115, 71, 221,122, 80, 217,128, 86, 223,148,106, 219,160,118, 223,176,134, 227,192,150, 233,204,162, 237,212,172, 239,215,177, 239,217,178, 233,200,181, 235,200,181, 235,198,179, 235,197,176, 235,193,171, 231,186,163, 225,177,155, 221,171,148, 210,158,136, 210,155,134, 208,151,132, 208,151,132, 213,156,139, 222,164,150, 232,174,160, 238,180,166, 231,191,183, 235,197,186, 233,200,185, 229,198,178, 230,202,178, 236,209,182, 235,206,176, 230,197,166, 213,174,145, 208,167,139, 206,162,137, 210,170,145, 223,187,165, 236,208,186, 248,223,201, 251,231,207, 244,245,231, 247,248,234, 247,248,234, 241,241,229, 231,233,220, 227,229,218, 228,231,222, 231,237,227, 229,234,227, 228,235,227, 227,237,229, 228,237,232, 228,237,232, 227,238,232, 226,237,233, 225,236,232,
235,245,254, 225,236,242, 213,222,227, 210,218,221, 215,220,223, 222,226,227, 227,229,228, 227,229,226, 230,232,229, 234,236,233, 236,241,237, 238,243,239, 237,243,241, 235,244,243, 234,244,243, 234,244,245, 230,241,245, 229,240,242, 228,240,240, 229,239,238, 232,241,238, 237,242,236, 242,242,232, 245,241,229, 250,238,224, 252,233,216, 251,224,205, 246,214,191, 243,202,180, 238,192,168, 235,185,160, 233,182,155, 236,167,125, 234,163,121, 231,156,117, 230,150,115, 232,149,115, 232,152,119, 228,153,121, 221,155,121, 217,163,129, 215,171,136, 217,183,146, 223,195,158, 227,203,167, 231,207,171, 233,209,175, 234,208,175, 225,201,189, 229,203,190, 232,204,192, 235,206,192, 236,203,188, 233,196,180, 226,184,168, 220,177,161, 214,168,153, 213,165,151, 211,163,151, 212,164,154, 218,169,162, 228,181,175, 239,192,186, 244,199,194, 235,210,216, 242,220,223, 245,225,226, 239,224,219, 239,226,217, 245,231,218, 244,227,211, 235,214,197, 220,192,178, 221,189,176, 221,189,178, 229,199,189, 240,215,208, 251,232,225, 254,241,233, 254,245,238, 243,248,241, 243,248,241, 241,247,237, 238,244,234, 233,239,229, 228,234,224, 225,231,221, 223,229,219, 226,232,222, 225,233,222, 226,233,225, 226,233,225, 226,233,226, 224,234,226, 223,233,225, 223,232,227,
234,242,253, 225,234,243, 217,224,232, 218,223,229, 225,229,232, 233,234,236, 235,235,235, 233,233,231, 233,234,229, 235,236,231, 235,237,234, 232,237,233, 230,236,234, 228,237,236, 228,238,237, 229,241,241, 229,235,235, 228,234,232, 225,234,231, 225,234,231, 225,234,231, 227,236,231, 230,237,230, 233,238,232, 236,237,231, 244,241,232, 251,244,234, 254,241,232, 251,233,223, 249,227,216, 250,223,214, 252,223,215, 255,223,210, 255,222,210, 255,219,206, 255,214,202, 255,212,202, 255,216,205, 255,217,205, 251,215,199, 238,211,192, 234,216,194, 236,221,198, 237,225,201, 238,226,200, 241,225,200, 240,222,198, 241,221,197, 229,225,214, 232,225,215, 236,228,217, 241,229,217, 244,228,215, 241,222,208, 236,212,200, 232,206,193, 236,208,197, 235,205,195, 231,201,193, 228,199,193, 228,200,197, 230,204,203, 235,209,210, 238,214,214, 229,223,235, 234,231,240, 237,236,242, 233,234,236, 231,236,230, 235,238,229, 234,234,222, 231,225,213, 234,221,212, 236,219,211, 237,220,213, 240,225,220, 244,233,231, 244,240,237, 241,243,242, 237,241,240, 236,247,243, 233,244,238, 233,242,237, 233,243,235, 233,243,235, 232,239,231, 226,234,223, 222,228,218, 222,228,218, 222,228,218, 221,227,217, 220,226,216, 219,224,217, 217,224,216, 216,223,215, 216,223,216,
235,243,254, 225,231,243, 214,221,231, 213,218,224, 222,223,228, 228,228,230, 228,228,228, 226,225,223, 225,224,220, 226,227,222, 227,229,226, 225,230,226, 224,230,228, 221,231,230, 222,234,234, 224,236,236, 230,231,226, 229,231,226, 225,230,224, 223,229,225, 219,228,225, 218,230,226, 219,231,229, 218,233,230, 218,230,228, 222,232,233, 227,235,237, 232,236,239, 234,235,237, 237,235,238, 241,236,240, 245,239,243, 235,241,255, 241,244,255, 246,244,255, 245,239,253, 247,236,250, 251,241,252, 249,242,250, 242,240,243, 245,247,246, 242,249,242, 242,249,241, 242,248,238, 243,245,234, 245,241,230, 246,238,227, 248,235,226, 228,245,235, 228,244,234, 230,243,233, 233,243,232, 239,242,231, 240,240,228, 240,236,225, 240,234,222, 246,237,228, 245,236,229, 243,234,229, 239,231,228, 236,230,230, 235,231,232, 233,231,234, 233,233,235, 226,236,246, 226,239,247, 225,240,245, 221,240,238, 219,238,232, 220,237,227, 223,237,224, 225,233,220, 233,235,222, 236,234,222, 236,232,223, 235,232,227, 232,234,229, 227,236,233, 223,238,235, 220,239,237, 227,241,241, 225,239,239, 225,237,235, 224,236,232, 226,237,231, 225,235,227, 224,231,223, 222,230,219, 220,226,214, 219,225,213, 217,223,211, 215,221,209, 212,218,208, 211,217,207, 209,214,207, 209,214,207,
239,247,255, 226,232,244, 213,217,228, 208,211,218, 213,214,219, 218,218,220, 218,216,217, 215,214,212, 215,214,210, 217,218,213, 220,222,219, 221,226,222, 219,228,225, 219,229,228, 220,232,232, 222,234,234, 232,229,222, 230,229,224, 228,229,223, 222,227,221, 216,225,220, 214,226,224, 212,228,227, 211,229,229, 210,230,231, 208,227,231, 208,225,232, 211,226,233, 218,228,238, 224,232,243, 229,235,247, 231,237,249, 217,246,255, 227,252,255, 232,253,255, 231,248,255, 230,244,255, 235,247,255, 235,247,255, 229,245,255, 225,245,254, 224,245,250, 223,244,245, 224,243,241, 228,240,238, 231,235,234, 235,234,232, 237,232,229, 217,249,238, 215,245,235, 213,241,229, 215,239,226, 221,239,227, 226,240,227, 230,240,229, 232,240,229, 233,239,229, 234,239,232, 235,242,235, 236,242,240, 234,244,243, 234,245,247, 231,245,248, 231,245,248, 228,248,255, 223,247,251, 220,246,247, 216,245,241, 212,242,232, 212,238,225, 216,239,223, 224,241,223, 222,233,217, 225,231,217, 226,229,218, 222,227,220, 217,228,220, 215,232,226, 215,238,232, 216,243,238, 217,233,233, 216,232,232, 214,228,228, 212,227,224, 212,225,218, 213,224,216, 215,225,216, 218,226,215, 221,227,215, 219,225,213, 219,222,211, 215,218,207, 212,215,204, 210,213,204, 208,211,202, 208,211,202,
};

#else
	#include "mbnet96_0.25_q.h"
	#define IMG_L   (96)
	#define IMG_CH  (3)
	#define CLASS_N (1000)

//IMG_L*IMG_L*IMG_CH
uint8_t test_pic[128*128*3]={
  0,  0,  0,  0,  0,  0,  0,  0,  0,  0,  0,  0,  0,  0,  0,  0,  0,  0,  0,  0,  0,  0,  0,  0,  0,  0,  0,  0,
  0,  0,  0,  0,  0,  0,  0,  0,  0,  0,  0,  0,  0,  0,  0,  0,  0,  0,  0,  0,  0,  0,  0,  0,  0,  0,  0,  0,
  0,  0,  0,  0,  0,  0,  0,  0,  0,  0,  0,  0,  0,  0,  0,  0,  0,  0,  0,  0,  0,  0,  0,  0,  0,  0,  0,  0,
  0,  0,  0,  0,  0,  0,  0,  0,  0,  0,116,125,171,255,255,150, 93,  0,  0,  0,  0,  0,  0,  0,  0,  0,  0,  0,
  0,  0,  0,  0,  0,  0,  0,  0,  0,169,253,253,253,253,253,253,218, 30,  0,  0,  0,  0,  0,  0,  0,  0,  0,  0,
  0,  0,  0,  0,  0,  0,  0,  0,169,253,253,253,213,142,176,253,253,122,  0,  0,  0,  0,  0,  0,  0,  0,  0,  0,
  0,  0,  0,  0,  0,  0,  0, 52,250,253,210, 32, 12,  0,  6,206,253,140,  0,  0,  0,  0,  0,  0,  0,  0,  0,  0,
  0,  0,  0,  0,  0,  0,  0, 77,251,210, 25,  0,  0,  0,122,248,253, 65,  0,  0,  0,  0,  0,  0,  0,  0,  0,  0,
  0,  0,  0,  0,  0,  0,  0,  0, 31, 18,  0,  0,  0,  0,209,253,253, 65,  0,  0,  0,  0,  0,  0,  0,  0,  0,  0,
  0,  0,  0,  0,  0,  0,  0,  0,  0,  0,  0,  0,  0,117,247,253,198, 10,  0,  0,  0,  0,  0,  0,  0,  0,  0,  0,
  0,  0,  0,  0,  0,  0,  0,  0,  0,  0,  0,  0, 76,247,253,231, 63,  0,  0,  0,  0,  0,  0,  0,  0,  0,  0,  0,
  0,  0,  0,  0,  0,  0,  0,  0,  0,  0,  0,  0,128,253,253,144,  0,  0,  0,  0,  0,  0,  0,  0,  0,  0,  0,  0,
  0,  0,  0,  0,  0,  0,  0,  0,  0,  0,  0,176,246,253,159, 12,  0,  0,  0,  0,  0,  0,  0,  0,  0,  0,  0,  0,
  0,  0,  0,  0,  0,  0,  0,  0,  0,  0, 25,234,253,233, 35,  0,  0,  0,  0,  0,  0,  0,  0,  0,  0,  0,  0,  0,
  0,  0,  0,  0,  0,  0,  0,  0,  0,  0,198,253,253,141,  0,  0,  0,  0,  0,  0,  0,  0,  0,  0,  0,  0,  0,  0,
  0,  0,  0,  0,  0,  0,  0,  0,  0, 78,248,253,189, 12,  0,  0,  0,  0,  0,  0,  0,  0,  0,  0,  0,  0,  0,  0,
  0,  0,  0,  0,  0,  0,  0,  0, 19,200,253,253,141,  0,  0,  0,  0,  0,  0,  0,  0,  0,  0,  0,  0,  0,  0,  0,
  0,  0,  0,  0,  0,  0,  0,  0,134,253,253,173, 12,  0,  0,  0,  0,  0,  0,  0,  0,  0,  0,  0,  0,  0,  0,  0,
  0,  0,  0,  0,  0,  0,  0,  0,248,253,253, 25,  0,  0,  0,  0,  0,  0,  0,  0,  0,  0,  0,  0,  0,  0,  0,  0,
  0,  0,  0,  0,  0,  0,  0,  0,248,253,253, 43, 20, 20, 20, 20,  5,  0,  5, 20, 20, 37,150,150,150,147, 10,  0,
  0,  0,  0,  0,  0,  0,  0,  0,248,253,253,253,253,253,253,253,168,143,166,253,253,253,253,253,253,253,123,  0,
  0,  0,  0,  0,  0,  0,  0,  0,174,253,253,253,253,253,253,253,253,253,253,253,249,247,247,169,117,117, 57,  0,
  0,  0,  0,  0,  0,  0,  0,  0,  0,118,123,123,123,166,253,253,253,155,123,123, 41,  0,  0,  0,  0,  0,  0,  0,
  0,  0,  0,  0,  0,  0,  0,  0,  0,  0,  0,  0,  0,  0,  0,  0,  0,  0,  0,  0,  0,  0,  0,  0,  0,  0,  0,  0,
  0,  0,  0,  0,  0,  0,  0,  0,  0,  0,  0,  0,  0,  0,  0,  0,  0,  0,  0,  0,  0,  0,  0,  0,  0,  0,  0,  0,
  0,  0,  0,  0,  0,  0,  0,  0,  0,  0,  0,  0,  0,  0,  0,  0,  0,  0,  0,  0,  0,  0,  0,  0,  0,  0,  0,  0,
  0,  0,  0,  0,  0,  0,  0,  0,  0,  0,  0,  0,  0,  0,  0,  0,  0,  0,  0,  0,  0,  0,  0,  0,  0,  0,  0,  0,
  0,  0,  0,  0,  0,  0,  0,  0,  0,  0,  0,  0,  0,  0,  0,  0,  0,  0,  0,  0,  0,  0,  0,  0,  0,  0,  0,  0,
};
#endif
static uint32_t _t0,_t1;
static tm_err_t layer_cb(tm_mdl_t* mdl, tml_head_t* lh)
{   //dump middle result
    int h = lh->out_dims[1];
    int w = lh->out_dims[2];
    int ch= lh->out_dims[3];
    mtype_t* output = TML_GET_OUTPUT(mdl, lh);
    return TM_OK;
    _t1 = TM_GET_US();
    TM_PRINTF("===L%d use %.3f ms\n", mdl->layer_i, (float)(_t1-_t0)/1000.0);
    _t0 = TM_GET_US();
    TM_PRINTF("Layer %d callback ========\n", mdl->layer_i);
    #if 0
    for(int y=0; y<h; y++){
        TM_PRINTF("[");
        for(int x=0; x<w; x++){
            TM_PRINTF("[");
            for(int c=0; c<ch; c++){
            #if TM_MDL_TYPE == TM_MDL_FP32
                TM_PRINTF("%.3f,", output[(y*w+x)*ch+c]);
            #else
                TM_PRINTF("%.3f,", TML_DEQUANT(lh,output[(y*w+x)*ch+c]));
            #endif
            }
            TM_PRINTF("],");
        }
        TM_PRINTF("],\n");
    }
    TM_PRINTF("\n");
    #endif
    return TM_OK;
}

extern  __IO uint32_t uwTick;
static uint8_t mdl_buf[MDL_BUF_LEN];
extern const char* labels[1000];
extern const unsigned char test_pic[IMG_L*IMG_L*IMG_CH];

static void parse_output(tm_mat_t* outs)
{
    tm_mat_t out = outs[0];
    float* data  = out.dataf;
    float maxp = 0;
    int maxi = -1;
    for(int i=0; i<CLASS_N; i++){
        //TM_PRINTF("%3d: %.3f, ", i, data[i]); if(i%20==19)TM_PRINTF("\n");
        if(data[i] > maxp) {
            maxi = i;
            maxp = data[i];
        }
    }
    TM_PRINTF("### Predict output is: Class %d (), Prob %.3f\n", maxi, maxp);
		//TM_PRINTF("### Predict output is: Class %d (%s), Prob %.3f\n", maxi, labels[maxi], maxp);
    return;
}
/* USER CODE END 0 */

int main(void)
{

  /* MCU Configuration--------------------------------------------------------*/

  /* Reset of all peripherals, Initializes the Flash interface and the Systick. */
  HAL_Init();

  /* Configure the system clock */
  SystemClock_Config();

  /* Initialize all configured peripherals */
  MX_GPIO_Init();
  MX_LPUART1_UART_Init();
  /* USER CODE BEGIN 2 */
//  HAL_UART_Transmit(&hlpuart1,"hello\n",6,HAL_MAX_DELAY);
	// SysTick_Config(SystemCoreClock/1000);
//	printf("hello\n");
	printf("Hello World! %.3f\r\n", 1.23456);
	printf("%d\r\n",uwTick);

	  TM_DBGT_INIT();
    TM_PRINTF("mnist demo\n");
    tm_mdl_t mdl;

    for(int i=0; i<28*28; i++){
        TM_PRINTF("%3d,", test_pic[i]);
        if(i%28==27)printf("\n");
    }

    tm_mat_t in_uint8 = {3,IMG_L,IMG_L,IMG_CH, (mtype_t*)test_pic};
    tm_mat_t in = {3,IMG_L,IMG_L,IMG_CH, NULL};
    tm_mat_t outs[1];
    tm_err_t res;
    tm_stat((tm_mdlbin_t*)mdl_data);

    res = tm_load(&mdl, mdl_data, mdl_buf, layer_cb, &in);
    if(res != TM_OK) {
        TM_PRINTF("tm model load err %d\n", res);
        return -1;
    }

#if TM_MDL_TYPE != TM_MDL_FP32
    res = tm_preprocess(&mdl, TMPP_UINT2INT, &in_uint8, &in);
#else
    res = tm_preprocess(&mdl, TMPP_UINT2FP01, &in_uint8, &in);
#endif

    TM_DBGT_START();
    res = tm_run(&mdl, &in, outs);
    TM_DBGT("tm_run");

    if(res==TM_OK) parse_output(outs);
    else TM_PRINTF("tm run error: %d\n", res);
    tm_unload(&mdl);

  /* USER CODE END 2 */

  /* Infinite loop */
  while (1)
  {

    /* USER CODE BEGIN 3 */
	  HAL_GPIO_TogglePin(LED1_GPIO_Port,LED1_Pin);
	  HAL_Delay(500);
  }
  /* USER CODE END 3 */
}

void SystemClock_Config(void)
{
  RCC_OscInitTypeDef RCC_OscInitStruct = {0};
  RCC_ClkInitTypeDef RCC_ClkInitStruct = {0};

  /** Configure the main internal regulator output voltage
  */
  if (HAL_PWREx_ControlVoltageScaling(PWR_REGULATOR_VOLTAGE_SCALE1) != HAL_OK)
  {
    Error_Handler();
  }

  /** Initializes the RCC Oscillators according to the specified parameters
  * in the RCC_OscInitTypeDef structure.
  */
  RCC_OscInitStruct.OscillatorType = RCC_OSCILLATORTYPE_MSI;
  RCC_OscInitStruct.MSIState = RCC_MSI_ON;
  RCC_OscInitStruct.MSICalibrationValue = 0;
  RCC_OscInitStruct.MSIClockRange = RCC_MSIRANGE_6;
  RCC_OscInitStruct.PLL.PLLState = RCC_PLL_ON;
  RCC_OscInitStruct.PLL.PLLSource = RCC_PLLSOURCE_MSI;
  RCC_OscInitStruct.PLL.PLLM = 1;
  RCC_OscInitStruct.PLL.PLLN = 40;
  RCC_OscInitStruct.PLL.PLLP = RCC_PLLP_DIV2;
  RCC_OscInitStruct.PLL.PLLQ = RCC_PLLQ_DIV2;
  RCC_OscInitStruct.PLL.PLLR = RCC_PLLR_DIV2;
  if (HAL_RCC_OscConfig(&RCC_OscInitStruct) != HAL_OK)
  {
    Error_Handler();
  }

  /** Initializes the CPU, AHB and APB buses clocks
  */
  RCC_ClkInitStruct.ClockType = RCC_CLOCKTYPE_HCLK|RCC_CLOCKTYPE_SYSCLK
                              |RCC_CLOCKTYPE_PCLK1|RCC_CLOCKTYPE_PCLK2;
  RCC_ClkInitStruct.SYSCLKSource = RCC_SYSCLKSOURCE_PLLCLK;
  RCC_ClkInitStruct.AHBCLKDivider = RCC_SYSCLK_DIV1;
  RCC_ClkInitStruct.APB1CLKDivider = RCC_HCLK_DIV1;
  RCC_ClkInitStruct.APB2CLKDivider = RCC_HCLK_DIV1;

  if (HAL_RCC_ClockConfig(&RCC_ClkInitStruct, FLASH_LATENCY_4) != HAL_OK)
  {
    Error_Handler();
  }
}

void Error_Handler(void)
{
  __disable_irq();
  while (1)
  {
  }
}
